VERSION ""

NS_ :

BS_:

BU_: Engine2 Aftertreatment_1_GasOutlet BrakesSystemController Transmission1 Engine1

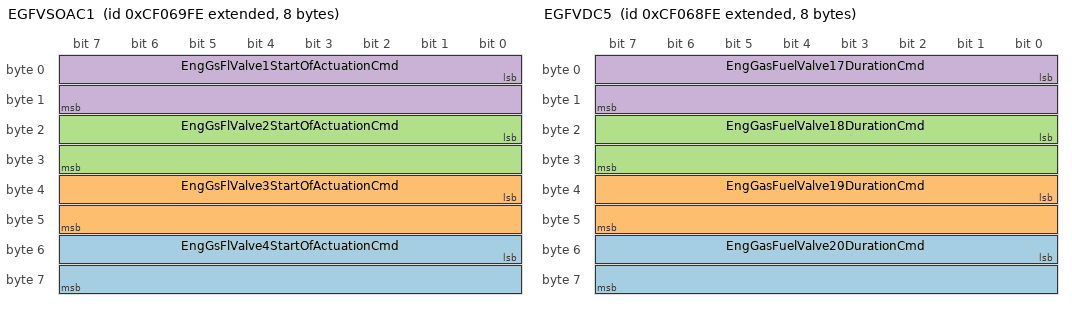
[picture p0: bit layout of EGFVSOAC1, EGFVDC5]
BO_ 2364566014 EGFVSOAC1: 8 Vector__XXX
 SG_ EngGsFlValve4StartOfActuationCmd : 48|16@1+ (0.0078125,-400) [-400|101.99] "deg" Vector__XXX
 SG_ EngGsFlValve3StartOfActuationCmd : 32|16@1+ (0.0078125,-400) [-400|101.99] "deg" Vector__XXX
 SG_ EngGsFlValve2StartOfActuationCmd : 16|16@1+ (0.0078125,-400) [-400|101.99] "deg" Vector__XXX
 SG_ EngGsFlValve1StartOfActuationCmd : 0|16@1+ (0.0078125,-400) [-400|101.99] "deg" Vector__XXX

BO_ 2364565758 EGFVDC5: 8 Vector__XXX
 SG_ EngGasFuelValve20DurationCmd : 48|16@1+ (2,0) [0|128510] "µs" Vector__XXX
 SG_ EngGasFuelValve19DurationCmd : 32|16@1+ (2,0) [0|128510] "µs" Vector__XXX
 SG_ EngGasFuelValve18DurationCmd : 16|16@1+ (2,0) [0|128510] "µs" Vector__XXX
 SG_ EngGasFuelValve17DurationCmd : 0|16@1+ (2,0) [0|128510] "µs" Vector__XXX

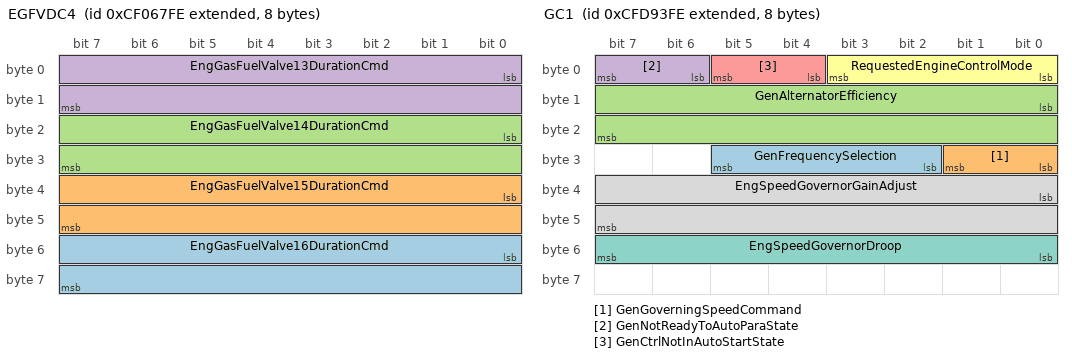
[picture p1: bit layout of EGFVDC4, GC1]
BO_ 2364565502 EGFVDC4: 8 Vector__XXX
 SG_ EngGasFuelValve16DurationCmd : 48|16@1+ (2,0) [0|128510] "µs" Vector__XXX
 SG_ EngGasFuelValve15DurationCmd : 32|16@1+ (2,0) [0|128510] "µs" Vector__XXX
 SG_ EngGasFuelValve14DurationCmd : 16|16@1+ (2,0) [0|128510] "µs" Vector__XXX
 SG_ EngGasFuelValve13DurationCmd : 0|16@1+ (2,0) [0|128510] "µs" Vector__XXX

BO_ 2364565246 EGFVDC3: 8 Vector__XXX
 SG_ EngGasFuelValve12DurationCmd : 48|16@1+ (2,0) [0|128510] "µs" Vector__XXX
 SG_ EngGasFuelValve11DurationCmd : 32|16@1+ (2,0) [0|128510] "µs" Vector__XXX
 SG_ EngGasFuelValve10DurationCmd : 16|16@1+ (2,0) [0|128510] "µs" Vector__XXX
 SG_ EngGasFuelValve9DurationCmd : 0|16@1+ (2,0) [0|128510] "µs" Vector__XXX

BO_ 2364564990 EGFVDC2: 8 Vector__XXX
 SG_ EngGasFuelValve8DurationCmd : 48|16@1+ (2,0) [0|128510] "µs" Vector__XXX
 SG_ EngGasFuelValve7DurationCmd : 32|16@1+ (2,0) [0|128510] "µs" Vector__XXX
 SG_ EngGasFuelValve6DurationCmd : 16|16@1+ (2,0) [0|128510] "µs" Vector__XXX
 SG_ EngGasFuelValve5DurationCmd : 0|16@1+ (2,0) [0|128510] "µs" Vector__XXX

BO_ 2364564734 EGFVDC1: 8 Vector__XXX
 SG_ EngGasFuelValve4DurationCmd : 48|16@1+ (2,0) [0|128510] "µs" Vector__XXX
 SG_ EngGasFuelValve3DurationCmd : 32|16@1+ (2,0) [0|128510] "µs" Vector__XXX
 SG_ EngGasFuelValve2DurationCmd : 16|16@1+ (2,0) [0|128510] "µs" Vector__XXX
 SG_ EngGasFuelValve1DurationCmd : 0|16@1+ (2,0) [0|128510] "µs" Vector__XXX

BO_ 2364564478 GFI5: 8 Vector__XXX
 SG_ EngGsFlVlvNmnlStrtOfActuationCmd : 16|16@1+ (0.0078125,-400) [-400|101.99] "deg" Vector__XXX
 SG_ EngGsFuelValveNominalDurationCmd : 0|16@1+ (2,0) [0|128510] "µs" Vector__XXX

BO_ 2297455358 ETC12: 8 Vector__XXX
 SG_ TransDirectionalOutputShaftSpeed : 32|16@1+ (1,-32127) [-32127|32128] "rpm" Vector__XXX
 SG_ TransHydrostaticLoop2Press : 16|16@1+ (1,0) [0|64255] "kPa" Vector__XXX
 SG_ TransHydrostaticLoop1Press : 0|16@1+ (1,0) [0|64255] "kPa" Vector__XXX

BO_ 2498781694 ECCAI20: 8 Vector__XXX
 SG_ EngCyl20AvrageCombustionDuration : 48|16@1+ (0.0078125,0) [0|501.99] "deg" Vector__XXX
 SG_ EngCyl20AvrgCntrOfCmbstionTiming : 32|16@1+ (0.0078125,-250) [-250|250.992] "deg" Vector__XXX
 SG_ EngCyl20AvrgStrtOfCmbstionTiming : 16|16@1+ (0.0078125,-250) [-250|250.992] "deg" Vector__XXX
 SG_ EngCyl20IndctdMeanEffectivePress : 0|16@1+ (0.0001220703125,-1) [-1|6.84362793] "MPa" Vector__XXX

BO_ 2498781438 ECCAI19: 8 Vector__XXX
 SG_ EngCyl19AvrageCombustionDuration : 48|16@1+ (0.0078125,0) [0|501.99] "deg" Vector__XXX
 SG_ EngCyl19AvrgCntrOfCmbstionTiming : 32|16@1+ (0.0078125,-250) [-250|250.992] "deg" Vector__XXX
 SG_ EngCyl19AvrgStrtOfCmbstionTiming : 16|16@1+ (0.0078125,-250) [-250|250.992] "deg" Vector__XXX
 SG_ EngCyl19IndctdMeanEffectivePress : 0|16@1+ (0.0001220703125,-1) [-1|6.84362793] "MPa" Vector__XXX

BO_ 2498781182 ECCAI18: 8 Vector__XXX
 SG_ EngCyl18AvrageCombustionDuration : 48|16@1+ (0.0078125,0) [0|501.99] "deg" Vector__XXX
 SG_ EngCyl18AvrgCntrOfCmbstionTiming : 32|16@1+ (0.0078125,-250) [-250|250.992] "deg" Vector__XXX
 SG_ EngCyl18AvrgStrtOfCmbstionTiming : 16|16@1+ (0.0078125,-250) [-250|250.992] "deg" Vector__XXX
 SG_ EngCyl18IndctdMeanEffectivePress : 0|16@1+ (0.0001220703125,-1) [-1|6.84362793] "MPa" Vector__XXX

BO_ 2498780926 ECCAI17: 8 Vector__XXX
 SG_ EngCyl17AvrageCombustionDuration : 48|16@1+ (0.0078125,0) [0|501.99] "deg" Vector__XXX
 SG_ EngCyl17AvrgCntrOfCmbstionTiming : 32|16@1+ (0.0078125,-250) [-250|250.992] "deg" Vector__XXX
 SG_ EngCyl17AvrgStrtOfCmbstionTiming : 16|16@1+ (0.0078125,-250) [-250|250.992] "deg" Vector__XXX
 SG_ EngCyl17IndctdMeanEffectivePress : 0|16@1+ (0.0001220703125,-1) [-1|6.84362793] "MPa" Vector__XXX

BO_ 2498780670 ECCAI16: 8 Vector__XXX
 SG_ EngCyl16AvrageCombustionDuration : 48|16@1+ (0.0078125,0) [0|501.99] "deg" Vector__XXX
 SG_ EngCyl16AvrgCntrOfCmbstionTiming : 32|16@1+ (0.0078125,-250) [-250|250.992] "deg" Vector__XXX
 SG_ EngCyl16AvrgStrtOfCmbstionTiming : 16|16@1+ (0.0078125,-250) [-250|250.992] "deg" Vector__XXX
 SG_ EngCyl16IndctdMeanEffectivePress : 0|16@1+ (0.0001220703125,-1) [-1|6.84362793] "MPa" Vector__XXX

BO_ 2498780414 ECCAI15: 8 Vector__XXX
 SG_ EngCyl15AvrageCombustionDuration : 48|16@1+ (0.0078125,0) [0|501.99] "deg" Vector__XXX
 SG_ EngCyl15AvrgCntrOfCmbstionTiming : 32|16@1+ (0.0078125,-250) [-250|250.992] "deg" Vector__XXX
 SG_ EngCyl15AvrgStrtOfCmbstionTiming : 16|16@1+ (0.0078125,-250) [-250|250.992] "deg" Vector__XXX
 SG_ EngCyl15IndctdMeanEffectivePress : 0|16@1+ (0.0001220703125,-1) [-1|6.84362793] "MPa" Vector__XXX

BO_ 2498780158 ECCAI14: 8 Vector__XXX
 SG_ EngCyl14AvrageCombustionDuration : 48|16@1+ (0.0078125,0) [0|501.99] "deg" Vector__XXX
 SG_ EngCyl14AvrgCntrOfCmbstionTiming : 32|16@1+ (0.0078125,-250) [-250|250.992] "deg" Vector__XXX
 SG_ EngCyl14AvrgStrtOfCmbstionTiming : 16|16@1+ (0.0078125,-250) [-250|250.992] "deg" Vector__XXX
 SG_ EngCyl14IndctdMeanEffectivePress : 0|16@1+ (0.0001220703125,-1) [-1|6.84362793] "MPa" Vector__XXX

BO_ 2498779902 ECCAI13: 8 Vector__XXX
 SG_ EngCyl13AvrageCombustionDuration : 48|16@1+ (0.0078125,0) [0|501.99] "deg" Vector__XXX
 SG_ EngCyl13AvrgCntrOfCmbstionTiming : 32|16@1+ (0.0078125,-250) [-250|250.992] "deg" Vector__XXX
 SG_ EngCyl13AvrgStrtOfCmbstionTiming : 16|16@1+ (0.0078125,-250) [-250|250.992] "deg" Vector__XXX
 SG_ EngCyl13IndctdMeanEffectivePress : 0|16@1+ (0.0001220703125,-1) [-1|6.84362793] "MPa" Vector__XXX

BO_ 2498779646 ECCAI12: 8 Vector__XXX
 SG_ EngCyl12AvrageCombustionDuration : 48|16@1+ (0.0078125,0) [0|501.99] "deg" Vector__XXX
 SG_ EngCyl12AvrgCntrOfCmbstionTiming : 32|16@1+ (0.0078125,-250) [-250|250.992] "deg" Vector__XXX
 SG_ EngCyl12AvrgStrtOfCmbstionTiming : 16|16@1+ (0.0078125,-250) [-250|250.992] "deg" Vector__XXX
 SG_ EngCyl12IndctdMeanEffectivePress : 0|16@1+ (0.0001220703125,-1) [-1|6.84362793] "MPa" Vector__XXX

BO_ 2498779390 ECCAI11: 8 Vector__XXX
 SG_ EngCyl11AvrageCombustionDuration : 48|16@1+ (0.0078125,0) [0|501.99] "deg" Vector__XXX
 SG_ EngCyl11AvrgCntrOfCmbstionTiming : 32|16@1+ (0.0078125,-250) [-250|250.992] "deg" Vector__XXX
 SG_ EngCyl11AvrgStrtOfCmbstionTiming : 16|16@1+ (0.0078125,-250) [-250|250.992] "deg" Vector__XXX
 SG_ EngCyl11IndctdMeanEffectivePress : 0|16@1+ (0.0001220703125,-1) [-1|6.84362793] "MPa" Vector__XXX

BO_ 2498779134 ECCAI10: 8 Vector__XXX
 SG_ EngCyl10AvrageCombustionDuration : 48|16@1+ (0.0078125,0) [0|501.99] "deg" Vector__XXX
 SG_ EngCyl10AvrgCntrOfCmbstionTiming : 32|16@1+ (0.0078125,-250) [-250|250.992] "deg" Vector__XXX
 SG_ EngCyl10AvrgStrtOfCmbstionTiming : 16|16@1+ (0.0078125,-250) [-250|250.992] "deg" Vector__XXX
 SG_ EngCyl10IndctdMeanEffectivePress : 0|16@1+ (0.0001220703125,-1) [-1|6.84362793] "MPa" Vector__XXX

BO_ 2498778878 ECCAI9: 8 Vector__XXX
 SG_ EngCyl9AverageCombustionDuration : 48|16@1+ (0.0078125,0) [0|501.99] "deg" Vector__XXX
 SG_ EngCyl9AvrgCntrOfCmbustionTiming : 32|16@1+ (0.0078125,-250) [-250|250.992] "deg" Vector__XXX
 SG_ EngCyl9AvrgStrtOfCmbustionTiming : 16|16@1+ (0.0078125,-250) [-250|250.992] "deg" Vector__XXX
 SG_ EngCyl9IndctedMeanEffectivePress : 0|16@1+ (0.0001220703125,-1) [-1|6.84362793] "MPa" Vector__XXX

BO_ 2365430526 EBS24: 8 Vector__XXX

BO_ 2357919486 RGE12: 8 Vector__XXX

BO_ 2357853950 RGE24: 8 Vector__XXX

BO_ 2365428734 GC1: 8 Vector__XXX
 SG_ GenFrequencySelection : 26|4@1+ (1,0) [0|15] "" Vector__XXX
 SG_ GenGoverningSpeedCommand : 24|2@1+ (1,0) [0|3] "" Vector__XXX
 SG_ GenAlternatorEfficiency : 8|16@1+ (0.0025,0) [0|100] "%" Vector__XXX
 SG_ GenNotReadyToAutoParaState : 6|2@1+ (1,0) [0|3] "" Vector__XXX
 SG_ GenCtrlNotInAutoStartState : 4|2@1+ (1,0) [0|3] "" Vector__XXX
 SG_ RequestedEngineControlMode : 0|4@1+ (1,0) [0|15] "" Vector__XXX
 SG_ EngSpeedGovernorDroop : 48|8@1+ (0.04,0) [0|10] "%" Vector__XXX
 SG_ EngSpeedGovernorGainAdjust : 32|16@1+ (1,-32128) [-32128|32127] "" Vector__XXX

BO_ 2365376254 DM57: 8 Vector__XXX
 SG_ EngOBDWarmUpSequence : 0|2@1+ (1,0) [0|3] "" Vector__XXX

BO_ 2566703102 DM56: 208 Vector__XXX
 SG_ CertificationEngineFamilyName : 64|64@1+ (1,0) [0|255] "" Vector__XXX
 SG_ ModelYear : 0|64@1+ (1,0) [0|255] "" Vector__XXX

BO_ 2566705918 DM54: 22 Vector__XXX
 SG_ DTC1 : 16|32@1+ (1,0) [0|4294967295] "" Vector__XXX
 SG_ FlashProtectLamp : 8|2@1+ (1,0) [0|3] "" Vector__XXX
 SG_ FlashAmberWarningLamp : 10|2@1+ (1,0) [0|3] "" Vector__XXX
 SG_ FlashRedStopLamp : 12|2@1+ (1,0) [0|3] "" Vector__XXX
 SG_ FlashMalfuncIndicatorLamp : 14|2@1+ (1,0) [0|3] "" Vector__XXX
 SG_ ProtectLampStatus : 0|2@1+ (1,0) [0|3] "" Vector__XXX
 SG_ AmberWarningLampStatus : 2|2@1+ (1,0) [0|3] "" Vector__XXX
 SG_ RedStopLampState : 4|2@1+ (1,0) [0|3] "" Vector__XXX
 SG_ MalfunctionIndicatorLampStatus : 6|2@1+ (1,0) [0|3] "" Vector__XXX
 SG_ DTC5 : 144|32@1+ (1,0) [0|4294967295] "" Vector__XXX
 SG_ DTC4 : 112|32@1+ (1,0) [0|4294967295] "" Vector__XXX
 SG_ DTC3 : 80|32@1+ (1,0) [0|4294967295] "" Vector__XXX
 SG_ DTC2 : 48|32@1+ (1,0) [0|4294967295] "" Vector__XXX

BO_ 2566705662 DM53: 22 Vector__XXX
 SG_ DTC1 : 16|32@1+ (1,0) [0|4294967295] "" Vector__XXX
 SG_ FlashProtectLamp : 8|2@1+ (1,0) [0|3] "" Vector__XXX
 SG_ FlashAmberWarningLamp : 10|2@1+ (1,0) [0|3] "" Vector__XXX
 SG_ FlashRedStopLamp : 12|2@1+ (1,0) [0|3] "" Vector__XXX
 SG_ FlashMalfuncIndicatorLamp : 14|2@1+ (1,0) [0|3] "" Vector__XXX
 SG_ ProtectLampStatus : 0|2@1+ (1,0) [0|3] "" Vector__XXX
 SG_ AmberWarningLampStatus : 2|2@1+ (1,0) [0|3] "" Vector__XXX
 SG_ RedStopLampState : 4|2@1+ (1,0) [0|3] "" Vector__XXX
 SG_ MalfunctionIndicatorLampStatus : 6|2@1+ (1,0) [0|3] "" Vector__XXX
 SG_ DTC5 : 144|32@1+ (1,0) [0|4294967295] "" Vector__XXX
 SG_ DTC4 : 112|32@1+ (1,0) [0|4294967295] "" Vector__XXX
 SG_ DTC3 : 80|32@1+ (1,0) [0|4294967295] "" Vector__XXX
 SG_ DTC2 : 48|32@1+ (1,0) [0|4294967295] "" Vector__XXX

BO_ 2365379582 DM55: 0 Vector__XXX

BO_ 2349465342 SRASI: 8 Vector__XXX
 SG_ StaticRollAngleStatus : 8|3@1+ (1,0) [0|7] "" Vector__XXX
 SG_ StaticRollAngle : 0|8@1+ (1,-125) [-90|90] "deg" Vector__XXX

BO_ 2498777086 ECCAI2: 8 Vector__XXX
 SG_ EngCyl2AverageCombustionDuration : 48|16@1+ (0.0078125,0) [0|501.99] "deg" Vector__XXX
 SG_ EngCyl2AvrgCntrOfCmbustionTiming : 32|16@1+ (0.0078125,-250) [-250|250.992] "deg" Vector__XXX
 SG_ EngCyl2AvrgStrtOfCmbustionTiming : 16|16@1+ (0.0078125,-250) [-250|250.992] "deg" Vector__XXX
 SG_ EngCyl2IndctedMeanEffectivePress : 0|16@1+ (0.0001220703125,-1) [-1|6.84362793] "MPa" Vector__XXX

BO_ 2498776830 ECCAI1: 8 Vector__XXX
 SG_ EngCyl1AverageCombustionDuration : 48|16@1+ (0.0078125,0) [0|501.99] "deg" Vector__XXX
 SG_ EngCyl1AvrgCntrOfCmbustionTiming : 32|16@1+ (0.0078125,-250) [-250|250.992] "deg" Vector__XXX
 SG_ EngCyl1AvrgStrtOfCmbustionTiming : 16|16@1+ (0.0078125,-250) [-250|250.992] "deg" Vector__XXX
 SG_ EngCyl1IndctedMeanEffectivePress : 0|16@1+ (0.0001220703125,-1) [-1|6.84362793] "MPa" Vector__XXX

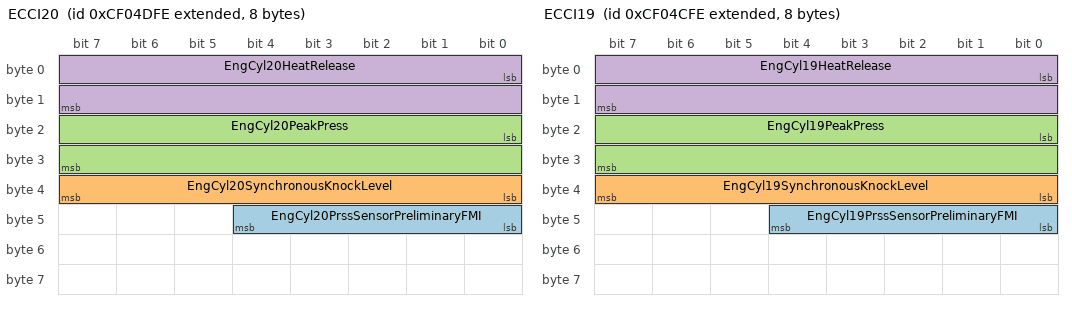
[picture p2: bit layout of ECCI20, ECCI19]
BO_ 2364558846 ECCI20: 8 Vector__XXX
 SG_ EngCyl20PrssSensorPreliminaryFMI : 40|5@1+ (1,0) [0|31] "" Vector__XXX
 SG_ EngCyl20SynchronousKnockLevel : 32|8@1+ (1,0) [0|250] "%" Vector__XXX
 SG_ EngCyl20PeakPress : 16|16@1+ (0.0009765625,0) [0|62.74902344] "MPa" Vector__XXX
 SG_ EngCyl20HeatRelease : 0|16@1+ (0.0001220703125,-1) [-1|6.84362793] "kJ/l" Vector__XXX

BO_ 2364558590 ECCI19: 8 Vector__XXX
 SG_ EngCyl19PrssSensorPreliminaryFMI : 40|5@1+ (1,0) [0|31] "" Vector__XXX
 SG_ EngCyl19SynchronousKnockLevel : 32|8@1+ (1,0) [0|250] "%" Vector__XXX
 SG_ EngCyl19PeakPress : 16|16@1+ (0.0009765625,0) [0|62.74902344] "MPa" Vector__XXX
 SG_ EngCyl19HeatRelease : 0|16@1+ (0.0001220703125,-1) [-1|6.84362793] "kJ/l" Vector__XXX

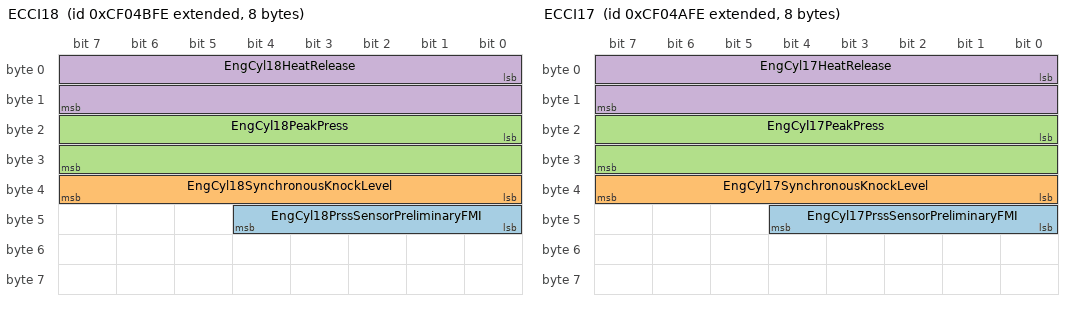
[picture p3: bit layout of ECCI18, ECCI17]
BO_ 2364558334 ECCI18: 8 Vector__XXX
 SG_ EngCyl18PrssSensorPreliminaryFMI : 40|5@1+ (1,0) [0|31] "" Vector__XXX
 SG_ EngCyl18SynchronousKnockLevel : 32|8@1+ (1,0) [0|250] "%" Vector__XXX
 SG_ EngCyl18PeakPress : 16|16@1+ (0.0009765625,0) [0|62.74902344] "MPa" Vector__XXX
 SG_ EngCyl18HeatRelease : 0|16@1+ (0.0001220703125,-1) [-1|6.84362793] "kJ/l" Vector__XXX

BO_ 2364558078 ECCI17: 8 Vector__XXX
 SG_ EngCyl17PrssSensorPreliminaryFMI : 40|5@1+ (1,0) [0|31] "" Vector__XXX
 SG_ EngCyl17SynchronousKnockLevel : 32|8@1+ (1,0) [0|250] "%" Vector__XXX
 SG_ EngCyl17PeakPress : 16|16@1+ (0.0009765625,0) [0|62.74902344] "MPa" Vector__XXX
 SG_ EngCyl17HeatRelease : 0|16@1+ (0.0001220703125,-1) [-1|6.84362793] "kJ/l" Vector__XXX

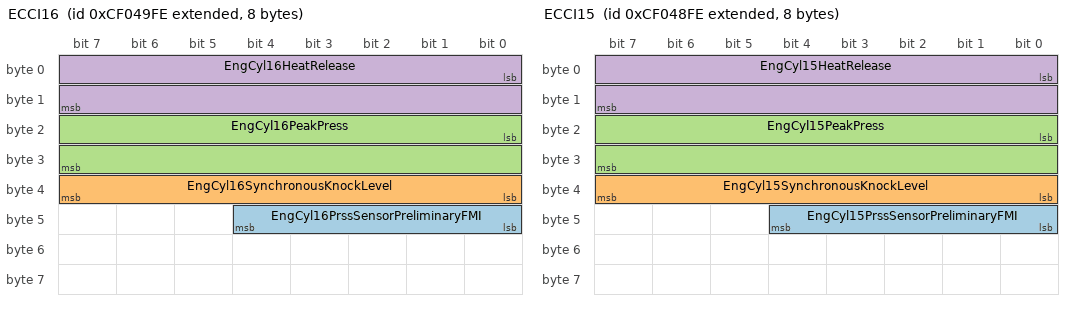
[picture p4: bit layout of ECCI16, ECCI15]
BO_ 2364557822 ECCI16: 8 Vector__XXX
 SG_ EngCyl16PrssSensorPreliminaryFMI : 40|5@1+ (1,0) [0|31] "" Vector__XXX
 SG_ EngCyl16SynchronousKnockLevel : 32|8@1+ (1,0) [0|250] "%" Vector__XXX
 SG_ EngCyl16PeakPress : 16|16@1+ (0.0009765625,0) [0|62.74902344] "MPa" Vector__XXX
 SG_ EngCyl16HeatRelease : 0|16@1+ (0.0001220703125,-1) [-1|6.84362793] "kJ/l" Vector__XXX

BO_ 2364557566 ECCI15: 8 Vector__XXX
 SG_ EngCyl15PrssSensorPreliminaryFMI : 40|5@1+ (1,0) [0|31] "" Vector__XXX
 SG_ EngCyl15SynchronousKnockLevel : 32|8@1+ (1,0) [0|250] "%" Vector__XXX
 SG_ EngCyl15PeakPress : 16|16@1+ (0.0009765625,0) [0|62.74902344] "MPa" Vector__XXX
 SG_ EngCyl15HeatRelease : 0|16@1+ (0.0001220703125,-1) [-1|6.84362793] "kJ/l" Vector__XXX

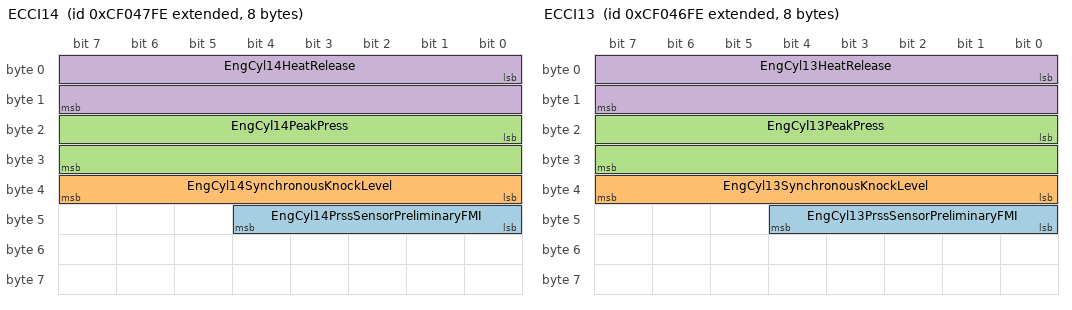
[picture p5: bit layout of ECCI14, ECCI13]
BO_ 2364557310 ECCI14: 8 Vector__XXX
 SG_ EngCyl14PrssSensorPreliminaryFMI : 40|5@1+ (1,0) [0|31] "" Vector__XXX
 SG_ EngCyl14SynchronousKnockLevel : 32|8@1+ (1,0) [0|250] "%" Vector__XXX
 SG_ EngCyl14PeakPress : 16|16@1+ (0.0009765625,0) [0|62.74902344] "MPa" Vector__XXX
 SG_ EngCyl14HeatRelease : 0|16@1+ (0.0001220703125,-1) [-1|6.84362793] "kJ/l" Vector__XXX

BO_ 2364557054 ECCI13: 8 Vector__XXX
 SG_ EngCyl13PrssSensorPreliminaryFMI : 40|5@1+ (1,0) [0|31] "" Vector__XXX
 SG_ EngCyl13SynchronousKnockLevel : 32|8@1+ (1,0) [0|250] "%" Vector__XXX
 SG_ EngCyl13PeakPress : 16|16@1+ (0.0009765625,0) [0|62.74902344] "MPa" Vector__XXX
 SG_ EngCyl13HeatRelease : 0|16@1+ (0.0001220703125,-1) [-1|6.84362793] "kJ/l" Vector__XXX

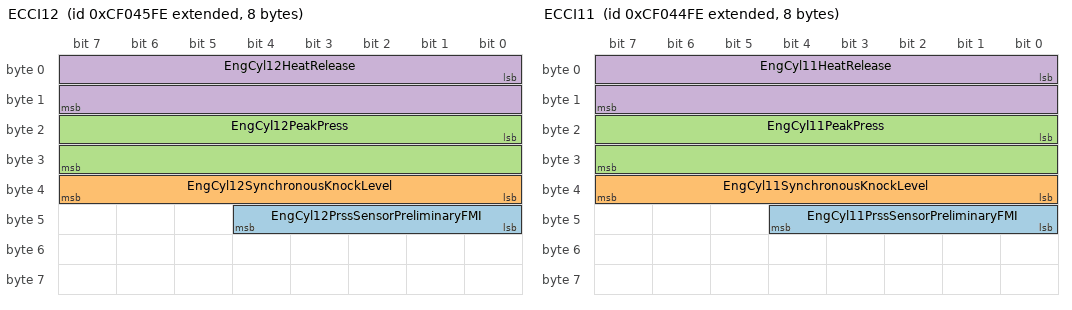
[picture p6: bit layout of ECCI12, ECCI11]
BO_ 2364556798 ECCI12: 8 Vector__XXX
 SG_ EngCyl12PrssSensorPreliminaryFMI : 40|5@1+ (1,0) [0|31] "" Vector__XXX
 SG_ EngCyl12SynchronousKnockLevel : 32|8@1+ (1,0) [0|250] "%" Vector__XXX
 SG_ EngCyl12PeakPress : 16|16@1+ (0.0009765625,0) [0|62.74902344] "MPa" Vector__XXX
 SG_ EngCyl12HeatRelease : 0|16@1+ (0.0001220703125,-1) [-1|6.84362793] "kJ/l" Vector__XXX

BO_ 2364556542 ECCI11: 8 Vector__XXX
 SG_ EngCyl11PrssSensorPreliminaryFMI : 40|5@1+ (1,0) [0|31] "" Vector__XXX
 SG_ EngCyl11SynchronousKnockLevel : 32|8@1+ (1,0) [0|250] "%" Vector__XXX
 SG_ EngCyl11PeakPress : 16|16@1+ (0.0009765625,0) [0|62.74902344] "MPa" Vector__XXX
 SG_ EngCyl11HeatRelease : 0|16@1+ (0.0001220703125,-1) [-1|6.84362793] "kJ/l" Vector__XXX

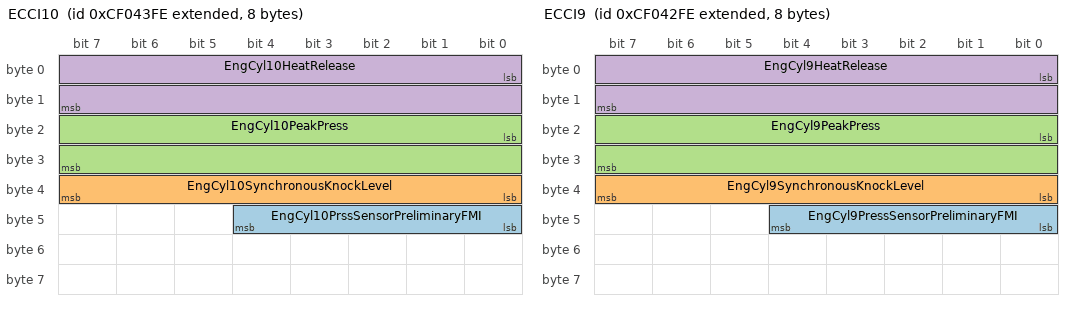
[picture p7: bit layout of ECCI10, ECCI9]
BO_ 2364556286 ECCI10: 8 Vector__XXX
 SG_ EngCyl10PrssSensorPreliminaryFMI : 40|5@1+ (1,0) [0|31] "" Vector__XXX
 SG_ EngCyl10SynchronousKnockLevel : 32|8@1+ (1,0) [0|250] "%" Vector__XXX
 SG_ EngCyl10PeakPress : 16|16@1+ (0.0009765625,0) [0|62.74902344] "MPa" Vector__XXX
 SG_ EngCyl10HeatRelease : 0|16@1+ (0.0001220703125,-1) [-1|6.84362793] "kJ/l" Vector__XXX

BO_ 2364556030 ECCI9: 8 Vector__XXX
 SG_ EngCyl9PressSensorPreliminaryFMI : 40|5@1+ (1,0) [0|31] "" Vector__XXX
 SG_ EngCyl9SynchronousKnockLevel : 32|8@1+ (1,0) [0|250] "%" Vector__XXX
 SG_ EngCyl9PeakPress : 16|16@1+ (0.0009765625,0) [0|62.74902344] "MPa" Vector__XXX
 SG_ EngCyl9HeatRelease : 0|16@1+ (0.0001220703125,-1) [-1|6.84362793] "kJ/l" Vector__XXX

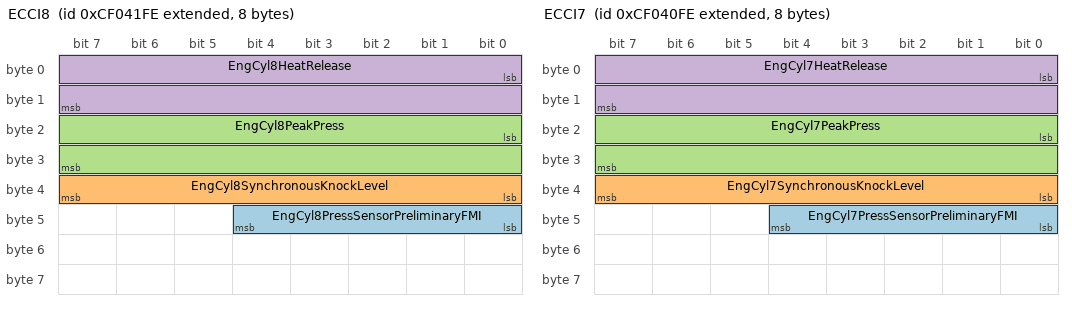
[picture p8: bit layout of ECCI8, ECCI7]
BO_ 2364555774 ECCI8: 8 Vector__XXX
 SG_ EngCyl8PressSensorPreliminaryFMI : 40|5@1+ (1,0) [0|31] "" Vector__XXX
 SG_ EngCyl8SynchronousKnockLevel : 32|8@1+ (1,0) [0|250] "%" Vector__XXX
 SG_ EngCyl8PeakPress : 16|16@1+ (0.0009765625,0) [0|62.74902344] "MPa" Vector__XXX
 SG_ EngCyl8HeatRelease : 0|16@1+ (0.0001220703125,-1) [-1|6.84362793] "kJ/l" Vector__XXX

BO_ 2364555518 ECCI7: 8 Vector__XXX
 SG_ EngCyl7PressSensorPreliminaryFMI : 40|5@1+ (1,0) [0|31] "" Vector__XXX
 SG_ EngCyl7SynchronousKnockLevel : 32|8@1+ (1,0) [0|250] "%" Vector__XXX
 SG_ EngCyl7PeakPress : 16|16@1+ (0.0009765625,0) [0|62.74902344] "MPa" Vector__XXX
 SG_ EngCyl7HeatRelease : 0|16@1+ (0.0001220703125,-1) [-1|6.84362793] "kJ/l" Vector__XXX

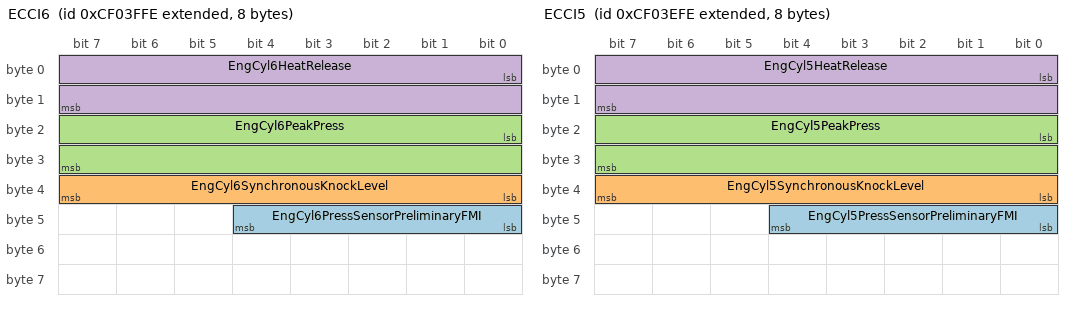
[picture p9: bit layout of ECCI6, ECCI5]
BO_ 2364555262 ECCI6: 8 Vector__XXX
 SG_ EngCyl6PressSensorPreliminaryFMI : 40|5@1+ (1,0) [0|31] "" Vector__XXX
 SG_ EngCyl6SynchronousKnockLevel : 32|8@1+ (1,0) [0|250] "%" Vector__XXX
 SG_ EngCyl6PeakPress : 16|16@1+ (0.0009765625,0) [0|62.74902344] "MPa" Vector__XXX
 SG_ EngCyl6HeatRelease : 0|16@1+ (0.0001220703125,-1) [-1|6.84362793] "kJ/l" Vector__XXX

BO_ 2364555006 ECCI5: 8 Vector__XXX
 SG_ EngCyl5PressSensorPreliminaryFMI : 40|5@1+ (1,0) [0|31] "" Vector__XXX
 SG_ EngCyl5SynchronousKnockLevel : 32|8@1+ (1,0) [0|250] "%" Vector__XXX
 SG_ EngCyl5PeakPress : 16|16@1+ (0.0009765625,0) [0|62.74902344] "MPa" Vector__XXX
 SG_ EngCyl5HeatRelease : 0|16@1+ (0.0001220703125,-1) [-1|6.84362793] "kJ/l" Vector__XXX

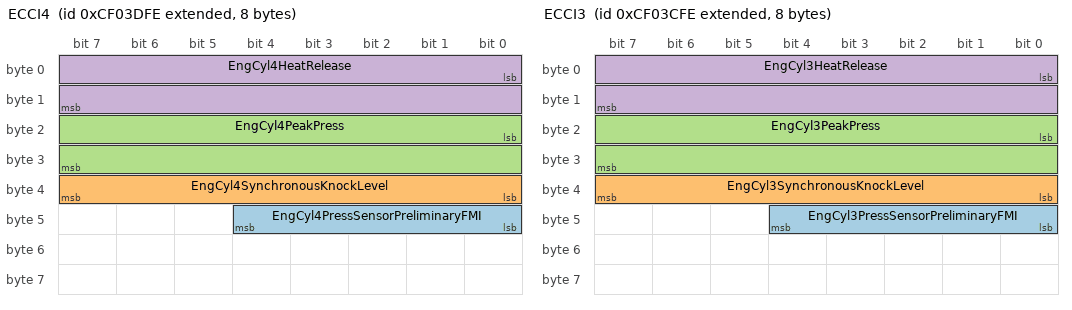
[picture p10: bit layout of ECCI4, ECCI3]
BO_ 2364554750 ECCI4: 8 Vector__XXX
 SG_ EngCyl4PressSensorPreliminaryFMI : 40|5@1+ (1,0) [0|31] "" Vector__XXX
 SG_ EngCyl4SynchronousKnockLevel : 32|8@1+ (1,0) [0|250] "%" Vector__XXX
 SG_ EngCyl4PeakPress : 16|16@1+ (0.0009765625,0) [0|62.74902344] "MPa" Vector__XXX
 SG_ EngCyl4HeatRelease : 0|16@1+ (0.0001220703125,-1) [-1|6.84362793] "kJ/l" Vector__XXX

BO_ 2364554494 ECCI3: 8 Vector__XXX
 SG_ EngCyl3PressSensorPreliminaryFMI : 40|5@1+ (1,0) [0|31] "" Vector__XXX
 SG_ EngCyl3SynchronousKnockLevel : 32|8@1+ (1,0) [0|250] "%" Vector__XXX
 SG_ EngCyl3PeakPress : 16|16@1+ (0.0009765625,0) [0|62.74902344] "MPa" Vector__XXX
 SG_ EngCyl3HeatRelease : 0|16@1+ (0.0001220703125,-1) [-1|6.84362793] "kJ/l" Vector__XXX

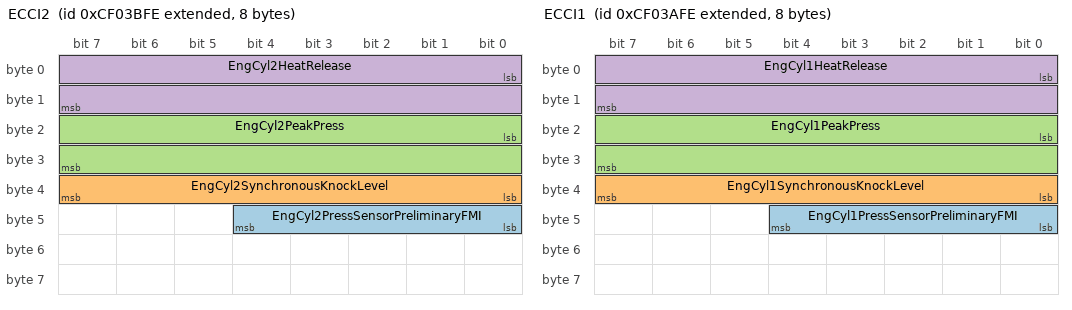
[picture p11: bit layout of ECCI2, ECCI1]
BO_ 2364554238 ECCI2: 8 Vector__XXX
 SG_ EngCyl2PressSensorPreliminaryFMI : 40|5@1+ (1,0) [0|31] "" Vector__XXX
 SG_ EngCyl2SynchronousKnockLevel : 32|8@1+ (1,0) [0|250] "%" Vector__XXX
 SG_ EngCyl2PeakPress : 16|16@1+ (0.0009765625,0) [0|62.74902344] "MPa" Vector__XXX
 SG_ EngCyl2HeatRelease : 0|16@1+ (0.0001220703125,-1) [-1|6.84362793] "kJ/l" Vector__XXX

BO_ 2364553982 ECCI1: 8 Vector__XXX
 SG_ EngCyl1PressSensorPreliminaryFMI : 40|5@1+ (1,0) [0|31] "" Vector__XXX
 SG_ EngCyl1SynchronousKnockLevel : 32|8@1+ (1,0) [0|100] "%" Vector__XXX
 SG_ EngCyl1PeakPress : 16|16@1+ (0.0009765625,0) [0|62.74902344] "MPa" Vector__XXX
 SG_ EngCyl1HeatRelease : 0|16@1+ (0.0001220703125,-1) [-1|6.84362793] "kJ/l" Vector__XXX

BO_ 2364553726 EASI: 8 Vector__XXX
 SG_ EngTotalIntakeMassAirFlowRate : 16|16@1+ (0.0009765625,0) [0|62.74902344] "kg/s" Vector__XXX
 SG_ EngDesiredAirFuelRatio : 0|16@1+ (0.001,0) [0|64.255] "" Vector__XXX

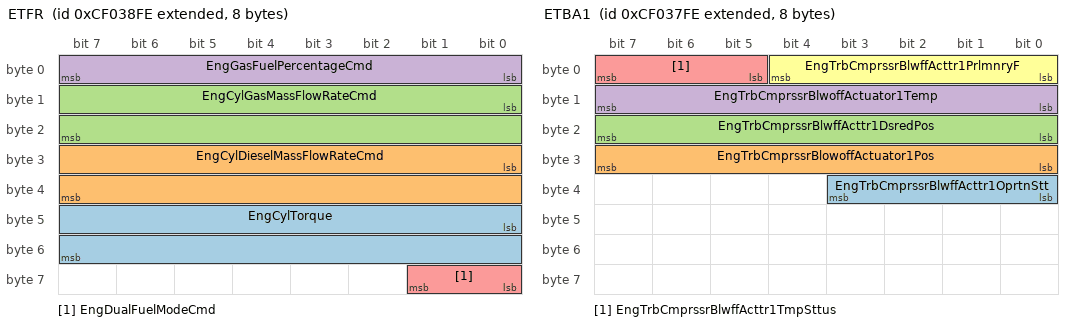
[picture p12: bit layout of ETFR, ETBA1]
BO_ 2364553470 ETFR: 8 Vector__XXX
 SG_ EngCylTorque : 40|16@1+ (1,0) [0|64255] "Nm" Vector__XXX
 SG_ EngCylDieselMassFlowRateCmd : 24|16@1+ (6.103515625E-005,0) [0|3.921813965] "kg/s" Vector__XXX
 SG_ EngCylGasMassFlowRateCmd : 8|16@1+ (6.103515625E-005,0) [0|3.921813965] "kg/s" Vector__XXX
 SG_ EngGasFuelPercentageCmd : 0|8@1+ (0.5,0) [0|100] "%" Vector__XXX
 SG_ EngDualFuelModeCmd : 56|2@1+ (1,0) [0|100] "" Vector__XXX

BO_ 2364553214 ETBA1: 8 Vector__XXX
 SG_ EngTrbCmprssrBlwffActtr1OprtnStt : 32|4@1+ (1,0) [0|15] "" Vector__XXX
 SG_ EngTrbCmprssrBlowoffActuator1Pos : 24|8@1+ (0.4,0) [0|100] "%" Vector__XXX
 SG_ EngTrbCmprssrBlwffActtr1DsredPos : 16|8@1+ (0.4,0) [0|100] "%" Vector__XXX
 SG_ EngTrbCmprssrBlwoffActuator1Temp : 8|8@1+ (1,-40) [-40|210] "°C" Vector__XXX
 SG_ EngTrbCmprssrBlwffActtr1TmpSttus : 5|3@1+ (1,0) [0|7] "" Vector__XXX
 SG_ EngTrbCmprssrBlwffActtr1PrlmnryF : 0|5@1+ (1,0) [0|31] "" Vector__XXX

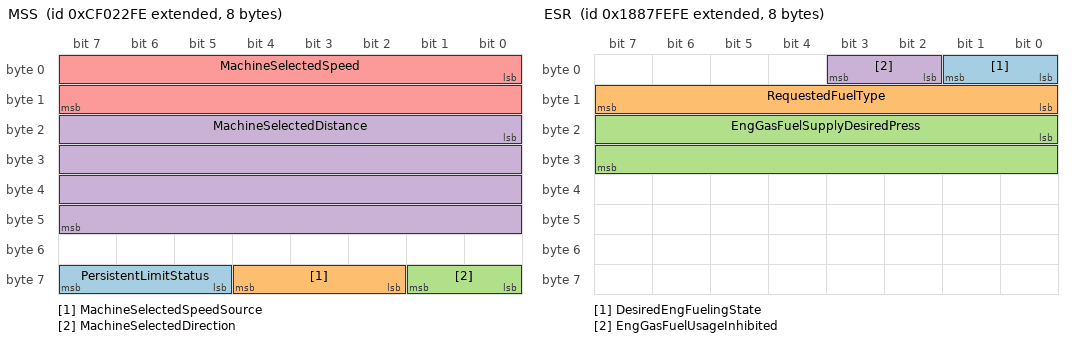
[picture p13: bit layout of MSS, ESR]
BO_ 2364547838 MSS: 8 Vector__XXX
 SG_ PersistentLimitStatus : 61|3@1+ (1,0) [0|0] "" Vector__XXX
 SG_ MachineSelectedSpeedSource : 58|3@1+ (1,0) [0|0] "" Vector__XXX
 SG_ MachineSelectedDirection : 56|2@1+ (1,0) [0|0] "" Vector__XXX
 SG_ MachineSelectedDistance : 16|32@1+ (1,0) [0|0] "" Vector__XXX
 SG_ MachineSelectedSpeed : 0|16@1+ (1,0) [0|0] "" Vector__XXX

BO_ 2364547326 EBS25: 8 Vector__XXX

BO_ 2364547070 EBS26: 8 Vector__XXX

BO_ 2364546814 GC2: 8 Vector__XXX
 SG_ GeneratorGoverningBias : 0|16@1+ (0.004,-125) [-125|125] "%" Vector__XXX

BO_ 2364546046 GPM17: 8 Vector__XXX

BO_ 2364538622 PropA: 8 Vector__XXX
 SG_ ManufacturerSpecificInformation : 0|64@1+ (1,0) [0|0] "" Vector__XXX

BO_ 2364014334 VT21: 8 Vector__XXX

BO_ 2363948798 VT12: 8 Vector__XXX

BO_ 2566767614 EEC15: 8 Vector__XXX
 SG_ AccelPedal2Channel3 : 24|8@1+ (0.4,0) [0|100] "%" Vector__XXX
 SG_ AccelPedal2Channel2 : 16|8@1+ (0.4,0) [0|100] "%" Vector__XXX
 SG_ AccelPedal1Channel3 : 8|8@1+ (0.4,0) [0|100] "%" Vector__XXX
 SG_ AccelPedal1Channel2 : 0|8@1+ (0.4,0) [0|100] "%" Vector__XXX

BO_ 2559049470 ESR: 8 Vector__XXX
 SG_ DesiredEngFuelingState : 0|2@1+ (1,0) [0|3] "" Vector__XXX
 SG_ RequestedFuelType : 8|8@1+ (1,0) [0|255] "" Vector__XXX
 SG_ EngGasFuelSupplyDesiredPress : 16|16@1+ (0.5,0) [0|32127.5] "kPa" Vector__XXX
 SG_ EngGasFuelUsageInhibited : 2|2@1+ (1,0) [0|3] "" Vector__XXX

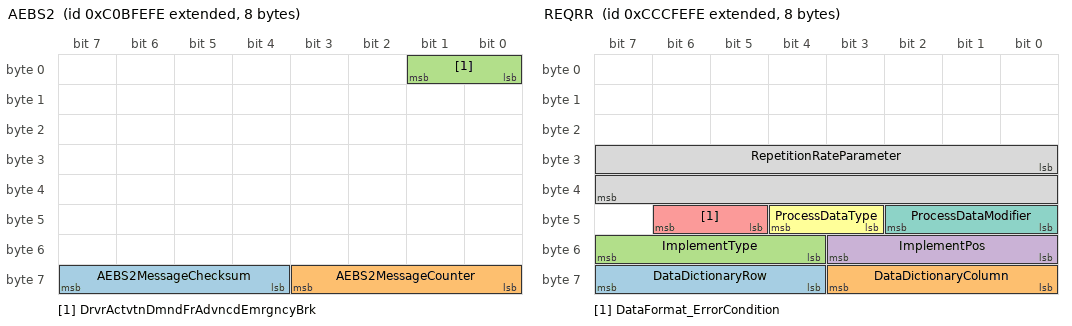
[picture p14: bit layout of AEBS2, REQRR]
BO_ 2349596414 AEBS2: 8 Vector__XXX
 SG_ AEBS2MessageChecksum : 60|4@1+ (1,0) [0|15] "" Vector__XXX
 SG_ AEBS2MessageCounter : 56|4@1+ (1,0) [0|15] "" Vector__XXX
 SG_ DrvrActvtnDmndFrAdvncdEmrgncyBrk : 0|2@1+ (1,0) [0|3] "" Vector__XXX

BO_ 2362375934 KWP3: 8 Vector__XXX

BO_ 2362310398 KWP4: 8 Vector__XXX

BO_ 2362244862 REQRR: 8 Vector__XXX
 SG_ DataDictionaryRow : 60|4@1+ (1,0) [0|0] "" Vector__XXX
 SG_ DataDictionaryColumn : 56|4@1+ (1,0) [0|0] "" Vector__XXX
 SG_ ImplementType : 52|4@1+ (1,0) [0|0] "" Vector__XXX
 SG_ ImplementPos : 48|4@1+ (1,0) [0|0] "" Vector__XXX
 SG_ DataFormat_ErrorCondition : 45|2@1+ (1,0) [0|0] "" Vector__XXX
 SG_ ProcessDataType : 43|2@1+ (1,0) [0|0] "" Vector__XXX
 SG_ ProcessDataModifier : 40|3@1+ (1,0) [0|0] "" Vector__XXX
 SG_ RepetitionRateParameter : 24|16@1+ (1,0) [0|0] "" Vector__XXX

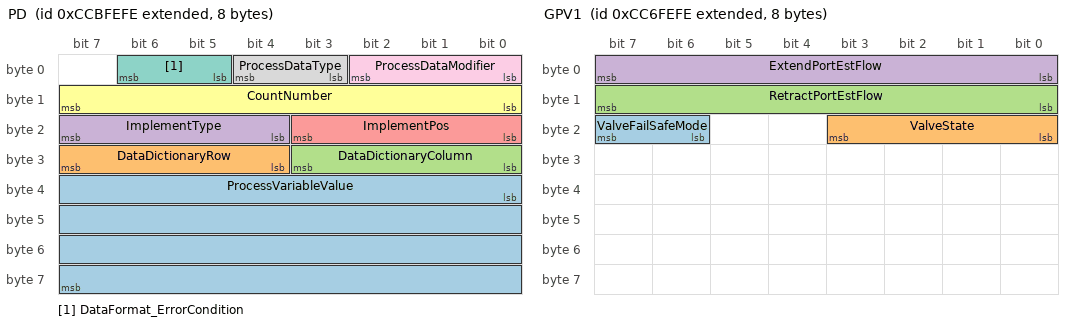
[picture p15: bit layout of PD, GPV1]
BO_ 2362179326 PD: 8 Vector__XXX
 SG_ ProcessVariableValue : 32|32@1+ (1,0) [0|0] "" Vector__XXX
 SG_ DataDictionaryRow : 28|4@1+ (1,0) [0|0] "" Vector__XXX
 SG_ DataDictionaryColumn : 24|4@1+ (1,0) [0|0] "" Vector__XXX
 SG_ ImplementType : 20|4@1+ (1,0) [0|0] "" Vector__XXX
 SG_ ImplementPos : 16|4@1+ (1,0) [0|0] "" Vector__XXX
 SG_ CountNumber : 8|8@1+ (1,0) [0|0] "" Vector__XXX
 SG_ DataFormat_ErrorCondition : 5|2@1+ (1,0) [0|0] "" Vector__XXX
 SG_ ProcessDataType : 3|2@1+ (1,0) [0|0] "" Vector__XXX
 SG_ ProcessDataModifier : 0|3@1+ (1,0) [0|0] "" Vector__XXX

BO_ 2361982718 ETPCM: 8 Vector__XXX

BO_ 2361917182 ETPDT: 8 Vector__XXX

BO_ 2361851646 GPV1: 8 Vector__XXX
 SG_ ValveFailSafeMode : 22|2@1+ (1,0) [0|0] "" Vector__XXX
 SG_ ValveState : 16|4@1+ (1,0) [0|0] "" Vector__XXX
 SG_ RetractPortEstFlow : 8|8@1+ (1,0) [0|0] "" Vector__XXX
 SG_ ExtendPortEstFlow : 0|8@1+ (1,0) [0|0] "" Vector__XXX

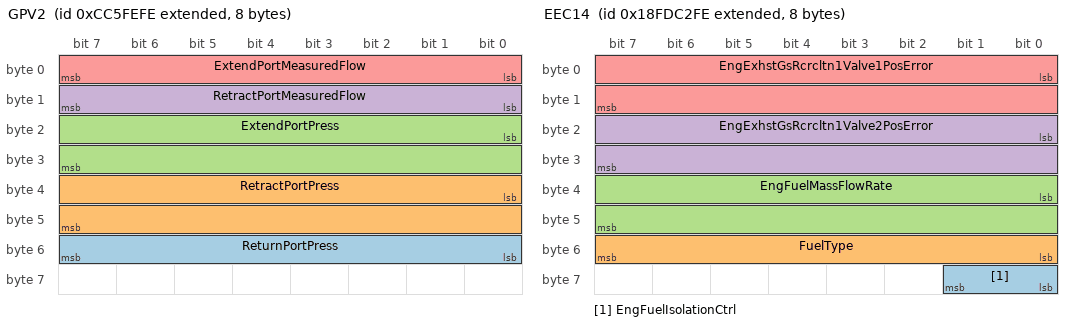
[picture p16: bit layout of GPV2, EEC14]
BO_ 2361786110 GPV2: 8 Vector__XXX
 SG_ ReturnPortPress : 48|8@1+ (1,0) [0|0] "" Vector__XXX
 SG_ RetractPortPress : 32|16@1+ (1,0) [0|0] "" Vector__XXX
 SG_ ExtendPortPress : 16|16@1+ (1,0) [0|0] "" Vector__XXX
 SG_ RetractPortMeasuredFlow : 8|8@1+ (1,0) [0|0] "" Vector__XXX
 SG_ ExtendPortMeasuredFlow : 0|8@1+ (1,0) [0|0] "" Vector__XXX

BO_ 2361720574 GPV3: 8 Vector__XXX
 SG_ PortFlowCmd : 0|8@1+ (1,0) [0|0] "" Vector__XXX

BO_ 2361458430 PCM16: 8 Vector__XXX

BO_ 2361392894 PCM15: 8 Vector__XXX

BO_ 2361327358 PCM14: 8 Vector__XXX

BO_ 2361261822 PCM13: 8 Vector__XXX

BO_ 2361196286 PCM12: 8 Vector__XXX

BO_ 2361130750 PCM11: 8 Vector__XXX

BO_ 2361065214 PCM10: 8 Vector__XXX

BO_ 2360999678 PCM9: 8 Vector__XXX

BO_ 2360934142 PCM8: 8 Vector__XXX

BO_ 2360868606 PCM7: 8 Vector__XXX

BO_ 2360803070 PCM6: 8 Vector__XXX

BO_ 2360737534 PCM5: 8 Vector__XXX

BO_ 2360671998 PCM4: 8 Vector__XXX

BO_ 2360606462 PCM3: 8 Vector__XXX

BO_ 2360540926 PCM2: 8 Vector__XXX

BO_ 2360475390 PCM1: 8 Vector__XXX

BO_ 2360409854 CIM: 8 Vector__XXX

BO_ 2360344318 PLM: 8 Vector__XXX

BO_ 2360213246 GSC: 8 Vector__XXX

BO_ 2360147710 GMS: 8 Vector__XXX

BO_ 2360082174 FSC: 8 Vector__XXX

BO_ 2358968062 GPM18: 8 Vector__XXX

BO_ 2358509310 NM: 8 Vector__XXX
 SG_ VehicleSystemQualifierFlag m0 : 12|1@1+ (1,0) [0|1] "" Vector__XXX
 SG_ VehicleSystemInstanceQualifierFl m0 : 13|1@1+ (1,0) [0|1] "" Vector__XXX
 SG_ NameChecksum m0 : 0|8@1+ (1,0) [0|0] "" Vector__XXX
 SG_ NMControlModeIndicator M : 16|4@1+ (1,0) [0|15] "" Vector__XXX
 SG_ ManufacturerCodeQualifierFlag m0M : 8|1@1+ (1,0) [0|1] "" Vector__XXX
 SG_ IndustryGroupQualifierFlag m0 : 14|1@1+ (1,0) [0|1] "" Vector__XXX
 SG_ FunctionQualifierFlag m0 : 11|1@1+ (1,0) [0|1] "" Vector__XXX
 SG_ FunctionInstanceQualifierFlag m0 : 10|1@1+ (1,0) [0|1] "" Vector__XXX
 SG_ ErrorCode m4 : 0|8@1+ (1,0) [0|0] "" Vector__XXX
 SG_ ECUInstanceQualifierFlag m0 : 9|1@1+ (1,0) [0|1] "" Vector__XXX
 SG_ CommandVehicleSystemInstance m0 : 56|4@1+ (1,0) [0|15] "" Vector__XXX
 SG_ CommandVehicleSystem m0 : 49|7@1+ (1,0) [0|127] "" Vector__XXX
 SG_ CommandManufacturerCode m0 : 21|11@1+ (1,0) [0|2047] "" Vector__XXX
 SG_ CommandIndustryGroup m0 : 60|3@1+ (1,0) [0|7] "" Vector__XXX
 SG_ CommandFunctionInstance m0 : 35|5@1+ (1,0) [0|31] "" Vector__XXX
 SG_ CommandFunction m0 : 40|8@1+ (1,0) [0|255] "" Vector__XXX
 SG_ CommandECUInstance m0 : 32|3@1+ (1,0) [0|7] "" Vector__XXX
 SG_ CommandArbitraryAddressCapable m0 : 63|1@1+ (1,0) [0|1] "" Vector__XXX
 SG_ ArbitraryAddressCapableQualifier m0 : 15|1@1+ (1,0) [0|1] "" Vector__XXX

BO_ 2358181630 SCMCC: 8 Vector__XXX

BO_ 2358116094 SCCCM: 8 Vector__XXX

BO_ 2358050558 CCP_CRO: 8 Vector__XXX

BO_ 2357985022 CCP_DTO: 8 Vector__XXX

BO_ 2558983934 SPOC: 8 Vector__XXX
 SG_ SwitchedPowerOutput18Cmd : 36|2@1+ (1,0) [0|3] "" Vector__XXX
 SG_ SwitchedPowerOutput19Cmd : 34|2@1+ (1,0) [0|3] "" Vector__XXX
 SG_ SwitchedPowerOutput20Cmd : 32|2@1+ (1,0) [0|3] "" Vector__XXX
 SG_ SwitchedPowerOutput13Cmd : 30|2@1+ (1,0) [0|3] "" Vector__XXX
 SG_ SwitchedPowerOutput14Cmd : 27|2@1+ (1,0) [0|3] "" Vector__XXX
 SG_ SwitchedPowerOutput15Cmd : 26|2@1+ (1,0) [0|3] "" Vector__XXX
 SG_ SwitchedPowerOutput16Cmd : 24|2@1+ (1,0) [0|3] "" Vector__XXX
 SG_ SwitchedPowerOutput9Cmd : 22|2@1+ (1,0) [0|3] "" Vector__XXX
 SG_ SwitchedPowerOutput10Cmd : 20|2@1+ (1,0) [0|3] "" Vector__XXX
 SG_ SwitchedPowerOutput29Cmd : 62|2@1+ (1,0) [0|3] "" Vector__XXX
 SG_ SwitchedPowerOutput30Cmd : 60|2@1+ (1,0) [0|3] "" Vector__XXX
 SG_ SwitchedPowerOutput31Cmd : 58|2@1+ (1,0) [0|3] "" Vector__XXX
 SG_ SwitchedPowerOutput32Cmd : 56|2@1+ (1,0) [0|3] "" Vector__XXX
 SG_ SwitchedPowerOutput25Cmd : 54|2@1+ (1,0) [0|3] "" Vector__XXX
 SG_ SwitchedPowerOutput26Cmd : 52|2@1+ (1,0) [0|3] "" Vector__XXX
 SG_ SwitchedPowerOutput27Cmd : 50|2@1+ (1,0) [0|3] "" Vector__XXX
 SG_ SwitchedPowerOutput28Cmd : 48|2@1+ (1,0) [0|3] "" Vector__XXX
 SG_ SwitchedPowerOutput21Cmd : 46|2@1+ (1,0) [0|3] "" Vector__XXX
 SG_ SwitchedPowerOutput22Cmd : 44|2@1+ (1,0) [0|3] "" Vector__XXX
 SG_ SwitchedPowerOutput23Cmd : 42|2@1+ (1,0) [0|3] "" Vector__XXX
 SG_ SwitchedPowerOutput24Cmd : 40|2@1+ (1,0) [0|3] "" Vector__XXX
 SG_ SwitchedPowerOutput17Cmd : 38|2@1+ (1,0) [0|3] "" Vector__XXX
 SG_ SwitchedPowerOutput11Cmd : 18|2@1+ (1,0) [0|3] "" Vector__XXX
 SG_ SwitchedPowerOutput12Cmd : 16|2@1+ (1,0) [0|3] "" Vector__XXX
 SG_ SwitchedPowerOutput5Cmd : 14|2@1+ (1,0) [0|3] "" Vector__XXX
 SG_ SwitchedPowerOutput6Cmd : 12|2@1+ (1,0) [0|3] "" Vector__XXX
 SG_ SwitchedPowerOutput7Cmd : 10|2@1+ (1,0) [0|3] "" Vector__XXX
 SG_ SwitchedPowerOutput8Cmd : 8|2@1+ (1,0) [0|3] "" Vector__XXX
 SG_ SwitchedPowerOutput1Cmd : 6|2@1+ (1,0) [0|3] "" Vector__XXX
 SG_ SwitchedPowerOutput2Cmd : 4|2@1+ (1,0) [0|3] "" Vector__XXX
 SG_ SwitchedPowerOutput3Cmd : 2|2@1+ (1,0) [0|3] "" Vector__XXX
 SG_ SwitchedPowerOutput4Cmd : 0|2@1+ (1,0) [0|3] "" Vector__XXX

BO_ 2349727486 TC2: 8 Vector__XXX
 SG_ TransMode10 : 2|2@1+ (1,0) [0|3] "" Vector__XXX
 SG_ TransMode9 : 0|2@1+ (1,0) [0|3] "" Vector__XXX

BO_ 2550988542 EEC16: 8 Vector__XXX
 SG_ AccelPedalPos3 : 0|8@1+ (0.4,0) [0|100] "%" Vector__XXX

BO_ 2349268734 CAM21: 8 Vector__XXX

BO_ 2349203198 CAM11: 8 Vector__XXX

BO_ 2566767358 EEC14: 8 Vector__XXX
 SG_ EngFuelIsolationCtrl : 56|2@1+ (1,0) [0|3] "" Vector__XXX
 SG_ FuelType : 48|8@1+ (1,0) [0|255] "" Vector__XXX
 SG_ EngFuelMassFlowRate : 32|16@1+ (0.005,0) [0|321.275] "g/s" Vector__XXX
 SG_ EngExhstGsRcrcltn1Valve2PosError : 16|16@1+ (0.004,-125) [-125|132.02] "%" Vector__XXX
 SG_ EngExhstGsRcrcltn1Valve1PosError : 0|16@1+ (0.004,-125) [-125|132.02] "%" Vector__XXX

BO_ 2566706686 AT1P1I: 8 Vector__XXX
 SG_ AT1DslExhustFluidPump2MotorSpeed : 8|16@1+ (0.5,0) [0|32127.5] "rpm" Vector__XXX
 SG_ AT1DieselExhaustFluidPumpHeater : 0|8@1+ (0.4,0) [0|100] "%" Vector__XXX

BO_ 2566705406 EPSI: 8 Vector__XXX
 SG_ AT1ParticulateSensorCurrent : 32|16@1+ (0.00390625,0) [0|127] "µA" Vector__XXX
 SG_ AT2ParticulateSensor : 16|16@1+ (0.0125,0) [0|803.1875] "mg/m³" Vector__XXX
 SG_ AT1ParticulateSensor : 0|16@1+ (0.0125,0) [0|803.1875] "mg/m³" Vector__XXX

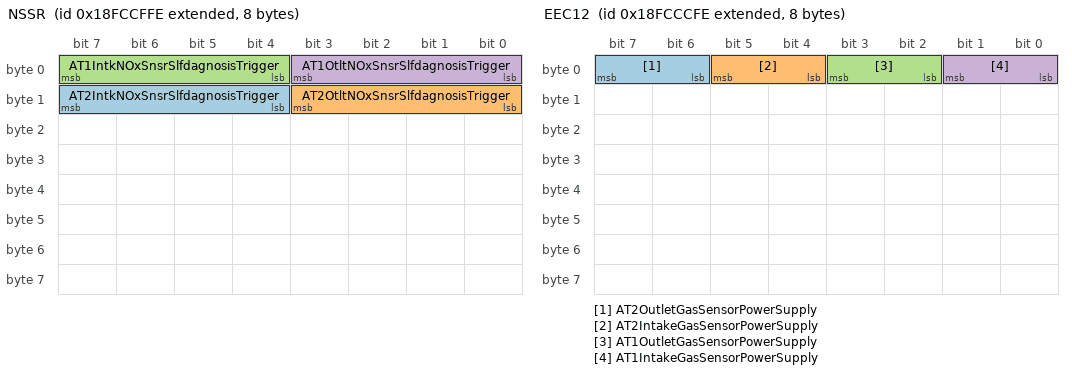
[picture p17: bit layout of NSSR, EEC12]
BO_ 2566705150 NSSR: 8 Vector__XXX
 SG_ AT2IntkNOxSnsrSlfdagnosisTrigger : 12|4@1+ (1,0) [0|15] "" Vector__XXX
 SG_ AT2OtltNOxSnsrSlfdagnosisTrigger : 8|4@1+ (1,0) [0|15] "" Vector__XXX
 SG_ AT1IntkNOxSnsrSlfdagnosisTrigger : 4|4@1+ (1,0) [0|15] "" Vector__XXX
 SG_ AT1OtltNOxSnsrSlfdagnosisTrigger : 0|4@1+ (1,0) [0|15] "" Vector__XXX

BO_ 2566704382 EEC12: 8 Vector__XXX
 SG_ AT2OutletGasSensorPowerSupply : 6|2@1+ (1,0) [0|3] "" Vector__XXX
 SG_ AT2IntakeGasSensorPowerSupply : 4|2@1+ (1,0) [0|3] "" Vector__XXX
 SG_ AT1OutletGasSensorPowerSupply : 2|2@1+ (1,0) [0|3] "" Vector__XXX
 SG_ AT1IntakeGasSensorPowerSupply : 0|2@1+ (1,0) [0|3] "" Vector__XXX

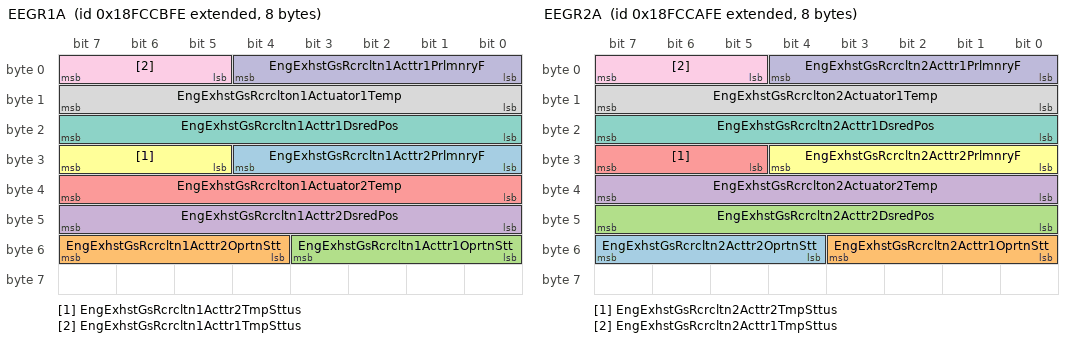
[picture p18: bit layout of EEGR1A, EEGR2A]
BO_ 2566704126 EEGR1A: 8 Vector__XXX
 SG_ EngExhstGsRcrcltn1Acttr2PrlmnryF : 24|5@1+ (1,0) [0|31] "" Vector__XXX
 SG_ EngExhstGsRcrcltn1Acttr2OprtnStt : 52|4@1+ (1,0) [0|15] "" Vector__XXX
 SG_ EngExhstGsRcrcltn1Acttr1OprtnStt : 48|4@1+ (1,0) [0|15] "" Vector__XXX
 SG_ EngExhstGsRcrcltn1Acttr2DsredPos : 40|8@1+ (0.4,0) [0|100] "%" Vector__XXX
 SG_ EngExhstGsRcrclton1Actuator2Temp : 32|8@1+ (1,-40) [-40|210] "°C" Vector__XXX
 SG_ EngExhstGsRcrcltn1Acttr2TmpSttus : 29|3@1+ (1,0) [0|7] "" Vector__XXX
 SG_ EngExhstGsRcrcltn1Acttr1DsredPos : 16|8@1+ (0.4,0) [0|100] "%" Vector__XXX
 SG_ EngExhstGsRcrclton1Actuator1Temp : 8|8@1+ (1,-40) [-40|210] "°C" Vector__XXX
 SG_ EngExhstGsRcrcltn1Acttr1TmpSttus : 5|3@1+ (1,0) [0|7] "" Vector__XXX
 SG_ EngExhstGsRcrcltn1Acttr1PrlmnryF : 0|5@1+ (1,0) [0|31] "" Vector__XXX

BO_ 2566703870 EEGR2A: 8 Vector__XXX
 SG_ EngExhstGsRcrcltn2Acttr2OprtnStt : 52|4@1+ (1,0) [0|15] "" Vector__XXX
 SG_ EngExhstGsRcrcltn2Acttr1OprtnStt : 48|4@1+ (1,0) [0|15] "" Vector__XXX
 SG_ EngExhstGsRcrcltn2Acttr2DsredPos : 40|8@1+ (0.4,0) [0|100] "%" Vector__XXX
 SG_ EngExhstGsRcrclton2Actuator2Temp : 32|8@1+ (1,-40) [-40|210] "°C" Vector__XXX
 SG_ EngExhstGsRcrcltn2Acttr2TmpSttus : 29|3@1+ (1,0) [0|7] "" Vector__XXX
 SG_ EngExhstGsRcrcltn2Acttr2PrlmnryF : 24|5@1+ (1,0) [0|31] "" Vector__XXX
 SG_ EngExhstGsRcrcltn2Acttr1DsredPos : 16|8@1+ (0.4,0) [0|100] "%" Vector__XXX
 SG_ EngExhstGsRcrclton2Actuator1Temp : 8|8@1+ (1,-40) [-40|210] "°C" Vector__XXX
 SG_ EngExhstGsRcrcltn2Acttr1TmpSttus : 5|3@1+ (1,0) [0|7] "" Vector__XXX
 SG_ EngExhstGsRcrcltn2Acttr1PrlmnryF : 0|5@1+ (1,0) [0|31] "" Vector__XXX

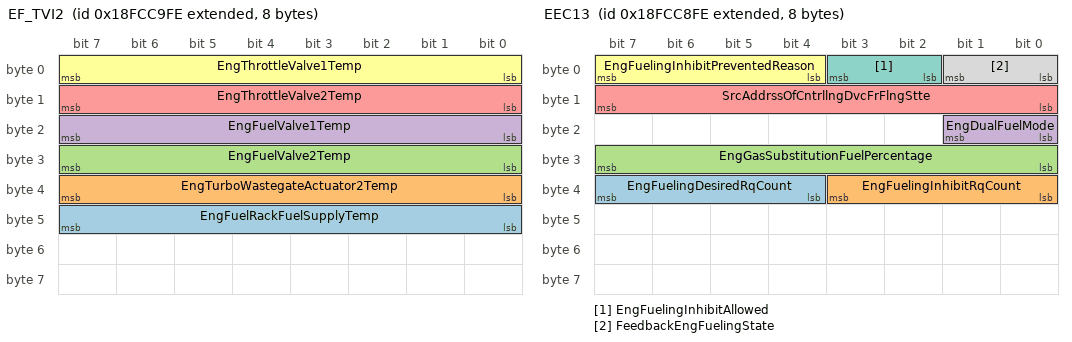
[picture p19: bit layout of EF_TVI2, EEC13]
BO_ 2566703614 EF_TVI2: 8 Vector__XXX
 SG_ EngFuelRackFuelSupplyTemp : 40|8@1+ (1,-40) [-40|210] "°C" Vector__XXX
 SG_ EngTurboWastegateActuator2Temp : 32|8@1+ (1,-40) [-40|210] "°C" Vector__XXX
 SG_ EngFuelValve2Temp : 24|8@1+ (1,-40) [-40|210] "°C" Vector__XXX
 SG_ EngFuelValve1Temp : 16|8@1+ (1,-40) [-40|210] "°C" Vector__XXX
 SG_ EngThrottleValve2Temp : 8|8@1+ (1,-40) [-40|210] "°C" Vector__XXX
 SG_ EngThrottleValve1Temp : 0|8@1+ (1,-40) [-40|210] "°C" Vector__XXX

BO_ 2566703358 EEC13: 8 Vector__XXX
 SG_ EngFuelingDesiredRqCount : 36|4@1+ (1,0) [0|15] "" Vector__XXX
 SG_ EngFuelingInhibitRqCount : 32|4@1+ (1,0) [0|15] "" Vector__XXX
 SG_ EngGasSubstitutionFuelPercentage : 24|8@1+ (0.5,0) [0|125] "%" Vector__XXX
 SG_ EngDualFuelMode : 16|2@1+ (1,0) [0|3] "" Vector__XXX
 SG_ SrcAddrssOfCntrllngDvcFrFlngStte : 8|8@1+ (1,0) [0|255] "" Vector__XXX
 SG_ EngFuelingInhibitPreventedReason : 4|4@1+ (1,0) [0|15] "" Vector__XXX
 SG_ EngFuelingInhibitAllowed : 2|2@1+ (1,0) [0|3] "" Vector__XXX
 SG_ FeedbackEngFuelingState : 0|2@1+ (1,0) [0|3] "" Vector__XXX

BO_ 2566702590 A1SCREGT2: 8 Vector__XXX
 SG_ AT1SCRIntrmdteTempPreliminaryFMI : 16|5@1+ (1,0) [0|31] "" Vector__XXX
 SG_ AT1SCRIntermediateTemp : 0|16@1+ (0.03125,-273) [-273|1734.96875] "°C" Vector__XXX

BO_ 2566702334 A2SCREGT2: 8 Vector__XXX
 SG_ AT2SCRIntrmdteTempPreliminaryFMI : 16|5@1+ (1,0) [0|31] "" Vector__XXX
 SG_ AT2SCRIntermediateTemp : 0|16@1+ (0.03125,-273) [-273|1734.96875] "°C" Vector__XXX

BO_ 2566702078 GFI4: 8 Vector__XXX
 SG_ SupplyGasMethanePercentage : 0|16@1+ (0.0025,0) [0|160.6375] "%" Vector__XXX

CM_ BO_ 2364566014 "Used to transmit the gaseous fuel valve start of activation command information for valve 1 to valve 4.";
CM_ SG_ 2364566014 EngGsFlValve4StartOfActuationCmd "The angle, relative to the TDC of cylinder 4, with 0 being the TDC before the power stroke commences, at the which gaseous fuel valve 4 is activated to open.
Timings after TDC are referred with positive values and timings before TDC are referred ...";
CM_ SG_ 2364566014 EngGsFlValve3StartOfActuationCmd "The angle, relative to the TDC of cylinder 3, with 0 being the TDC before the power stroke commences, at the which gaseous fuel valve 3 is activated to open.
Timings after TDC are referred with positive values and timings before TDC are referred ...";
CM_ SG_ 2364566014 EngGsFlValve2StartOfActuationCmd "The angle, relative to the TDC of cylinder 2, with 0 being the TDC before the power stroke commences, at the which gaseous fuel valve 2 is activated to open.
Timings after TDC are referred with positive values and timings before TDC are referred ...";
CM_ SG_ 2364566014 EngGsFlValve1StartOfActuationCmd "The angle, relative to the TDC of cylinder 1, with 0 being the TDC before the power stroke commences, at the which gaseous fuel valve 1 is activated to open.
Timings after TDC are referred with positive values and timings before TDC are referred ...";
CM_ BO_ 2364565758 "Used to transmit the gaseous fuel valve duration command information for valve 17 to valve 20.";
CM_ SG_ 2364565758 EngGasFuelValve20DurationCmd "Amount of time the gaseous fuel valve 20 is activated.";
CM_ SG_ 2364565758 EngGasFuelValve19DurationCmd "Amount of time the gaseous fuel valve 19 is activated.";
CM_ SG_ 2364565758 EngGasFuelValve18DurationCmd "Amount of time the gaseous fuel valve 18 is activated.";
CM_ SG_ 2364565758 EngGasFuelValve17DurationCmd "Amount of time the gaseous fuel valve 17 is activated.";
CM_ BO_ 2364565502 "Used to transmit the gaseous fuel valve duration command information for valve 13 to valve 16.";
CM_ SG_ 2364565502 EngGasFuelValve16DurationCmd "Amount of time the gaseous fuel valve 16 is activated.";
CM_ SG_ 2364565502 EngGasFuelValve15DurationCmd "Amount of time the gaseous fuel valve 15 is activated.";
CM_ SG_ 2364565502 EngGasFuelValve14DurationCmd "Amount of time the gaseous fuel valve 14 is activated.";
CM_ SG_ 2364565502 EngGasFuelValve13DurationCmd "Amount of time the gaseous fuel valve 13 is activated.";
CM_ BO_ 2364565246 "Used to transmit the gaseous fuel valve duration command information for valve 9 to valve 12.";
CM_ SG_ 2364565246 EngGasFuelValve12DurationCmd "Amount of time the gaseous fuel valve 12 is activated.";
CM_ SG_ 2364565246 EngGasFuelValve11DurationCmd "Amount of time the gaseous fuel valve 11 is activated.";
CM_ SG_ 2364565246 EngGasFuelValve10DurationCmd "Amount of time the gaseous fuel valve 10 is activated.";
CM_ SG_ 2364565246 EngGasFuelValve9DurationCmd "Amount of time the gaseous fuel valve 9 is activated.";
CM_ BO_ 2364564990 "Used to transmit the gaseous fuel valve duration command information for valve 5 to valve 8.";
CM_ SG_ 2364564990 EngGasFuelValve8DurationCmd "Amount of time the gaseous fuel valve 8 is activated.";
CM_ SG_ 2364564990 EngGasFuelValve7DurationCmd "Amount of time the gaseous fuel valve 7 is activated.";
CM_ SG_ 2364564990 EngGasFuelValve6DurationCmd "Amount of time the gaseous fuel valve 6 is activated.";
CM_ SG_ 2364564990 EngGasFuelValve5DurationCmd "Amount of time the gaseous fuel valve 5 is activated.";
CM_ BO_ 2364564734 "Used to transmit the gaseous fuel valve duration command information for valve 1 to valve 4.";
CM_ SG_ 2364564734 EngGasFuelValve4DurationCmd "Amount of time the gaseous fuel valve 4 is activated.";
CM_ SG_ 2364564734 EngGasFuelValve3DurationCmd "Amount of time the gaseous fuel valve 3 is activated.";
CM_ SG_ 2364564734 EngGasFuelValve2DurationCmd "Amount of time the gaseous fuel valve 2 is activated.";
CM_ SG_ 2364564734 EngGasFuelValve1DurationCmd "Amount of time the gaseous fuel valve 1 is activated.";
CM_ BO_ 2364564478 "Used to transmit the gaseous fuel valve command information.";
CM_ SG_ 2364564478 EngGsFlVlvNmnlStrtOfActuationCmd "The angle, relative to the TDC of each cylinder, with 0 being the TDC before the power stroke commences, at the which gaseous fuel valves are activated to open.  It's a nominal value used for all the gaseous fuel valves in the engine.
Timings after ...";
CM_ SG_ 2364564478 EngGsFuelValveNominalDurationCmd "Amount of time the gaseous fuel valves are activated.  It's a nominal value used for all the gaseous fuel valves in the engine.

Note: Please see SPNs 6658 - 6677 for duration command for each gaseous fuel valves";
CM_ BO_ 2297455358 "Electronic Transmission Controller #12";
CM_ SG_ 2297455358 TransDirectionalOutputShaftSpeed "The rotational velocity and direction of the output shaft. Positive values are used for forward vehicle motion, negative values for reverse vehicle motion.

SPN 191 should be used when direction is not used.";
CM_ SG_ 2297455358 TransHydrostaticLoop2Press "Oil pressure in the transmission hydrostatic loop #2 between the pump and motor.";
CM_ SG_ 2297455358 TransHydrostaticLoop1Press "Oil pressure in the transmission hydrostatic loop #1 between the pump and motor.";
CM_ BO_ 2498781694 "Used to transmit the average of combustion parameters of Engine Cylinder 20.
This PGN is transmitted at a defined ratio of the engine speed. The transmission rate is dependent on
SPN 6394 - Number of combustion cycles for Averaging. For example, ...";
CM_ SG_ 2498781694 EngCyl20AvrageCombustionDuration "Average duration of combustion calculated over defined number of combustion cycles for engine cylinder 20 with reference to the crank angle.  Combustion duration is the difference between end of combustion and start of combustion expressed, in this ...";
CM_ SG_ 2498781694 EngCyl20AvrgCntrOfCmbstionTiming "Average timing calculated over defined number of combustion cycles for the center of combustion in engine cylinder 20 with reference to the crank angle.  Center of Combustion is used to indicate the combustion efficiency.  When the combustion ...";
CM_ SG_ 2498781694 EngCyl20AvrgStrtOfCmbstionTiming "Average start of combustion timing calculated over defined number of combustion cycles for engine cylinder 20 with reference to the crank angle.  When the combustion happens after the TDC (Top Dead Center) of this cylinder, the timing is referred in ...";
CM_ SG_ 2498781694 EngCyl20IndctdMeanEffectivePress "Average cylinder pressure calculated over defined number of combustion cycles for engine cylinder 20.  Negative range is to cover thermodynamic behavior during misfire.";
CM_ BO_ 2498781438 "Used to transmit the average of combustion parameters of Engine Cylinder 19.
This PGN is transmitted at a defined ratio of the engine speed. The transmission rate is dependent on
SPN 6394 - Number of combustion cycles for Averaging. For example, ...";
CM_ SG_ 2498781438 EngCyl19AvrageCombustionDuration "Average duration of combustion calculated over defined number of combustion cycles for engine cylinder 19 with reference to the crank angle.  Combustion duration is the difference between end of combustion and start of combustion expressed, in this ...";
CM_ SG_ 2498781438 EngCyl19AvrgCntrOfCmbstionTiming "Average timing calculated over defined number of combustion cycles for the center of combustion in engine cylinder 19 with reference to the crank angle.  Center of Combustion is used to indicate the combustion efficiency.  When the combustion ...";
CM_ SG_ 2498781438 EngCyl19AvrgStrtOfCmbstionTiming "Average start of combustion timing calculated over defined number of combustion cycles for engine cylinder 19 with reference to the crank angle.  When the combustion happens after the TDC (Top Dead Center) of this cylinder, the timing is referred in ...";
CM_ SG_ 2498781438 EngCyl19IndctdMeanEffectivePress "Average cylinder pressure calculated over defined number of combustion cycles for engine cylinder 19.  Negative range is to cover thermodynamic behavior during misfire.";
CM_ BO_ 2498781182 "Used to transmit the average of combustion parameters of Engine Cylinder 18.
This PGN is transmitted at a defined ratio of the engine speed. The transmission rate is dependent on
SPN 6394 - Number of combustion cycles for Averaging. For example, ...";
CM_ SG_ 2498781182 EngCyl18AvrageCombustionDuration "Average duration of combustion calculated over defined number of combustion cycles for engine cylinder 18 with reference to the crank angle.  Combustion duration is the difference between end of combustion and start of combustion expressed, in this ...";
CM_ SG_ 2498781182 EngCyl18AvrgCntrOfCmbstionTiming "Average timing calculated over defined number of combustion cycles for the center of combustion in engine cylinder 18 with reference to the crank angle.  Center of Combustion is used to indicate the combustion efficiency.  When the combustion ...";
CM_ SG_ 2498781182 EngCyl18AvrgStrtOfCmbstionTiming "Average start of combustion timing calculated over defined number of combustion cycles for engine cylinder 18 with reference to the crank angle.  When the combustion happens after the TDC (Top Dead Center) of this cylinder, the timing is referred in ...";
CM_ SG_ 2498781182 EngCyl18IndctdMeanEffectivePress "Average cylinder pressure calculated over defined number of combustion cycles for engine cylinder 18.  Negative range is to cover thermodynamic behavior during misfire.";
CM_ BO_ 2498780926 "Used to transmit the average of combustion parameters of Engine Cylinder 17.
This PGN is transmitted at a defined ratio of the engine speed. The transmission rate is dependent on
SPN 6394 - Number of combustion cycles for Averaging. For example, ...";
CM_ SG_ 2498780926 EngCyl17AvrageCombustionDuration "Average duration of combustion calculated over defined number of combustion cycles for engine cylinder 17 with reference to the crank angle.  Combustion duration is the difference between end of combustion and start of combustion expressed, in this ...";
CM_ SG_ 2498780926 EngCyl17AvrgCntrOfCmbstionTiming "Average timing calculated over defined number of combustion cycles for the center of combustion in engine cylinder 17 with reference to the crank angle.  Center of Combustion is used to indicate the combustion efficiency.  When the combustion ...";
CM_ SG_ 2498780926 EngCyl17AvrgStrtOfCmbstionTiming "Average start of combustion timing calculated over defined number of combustion cycles for engine cylinder 17 with reference to the crank angle.  When the combustion happens after the TDC (Top Dead Center) of this cylinder, the timing is referred in ...";
CM_ SG_ 2498780926 EngCyl17IndctdMeanEffectivePress "Average cylinder pressure calculated over defined number of combustion cycles for engine cylinder 17.  Negative range is to cover thermodynamic behavior during misfire.";
CM_ BO_ 2498780670 "Used to transmit the average of combustion parameters of Engine Cylinder 16.
This PGN is transmitted at a defined ratio of the engine speed. The transmission rate is dependent on
SPN 6394 - Number of combustion cycles for Averaging. For example, ...";
CM_ SG_ 2498780670 EngCyl16AvrageCombustionDuration "Average duration of combustion calculated over defined number of combustion cycles for engine cylinder 16 with reference to the crank angle.  Combustion duration is the difference between end of combustion and start of combustion expressed, in this ...";
CM_ SG_ 2498780670 EngCyl16AvrgCntrOfCmbstionTiming "Average timing calculated over defined number of combustion cycles for the center of combustion in engine cylinder 16 with reference to the crank angle.  Center of Combustion is used to indicate the combustion efficiency.  When the combustion ...";
CM_ SG_ 2498780670 EngCyl16AvrgStrtOfCmbstionTiming "Average start of combustion timing calculated over defined number of combustion cycles for engine cylinder 16 with reference to the crank angle.  When the combustion happens after the TDC (Top Dead Center) of this cylinder, the timing is referred in ...";
CM_ SG_ 2498780670 EngCyl16IndctdMeanEffectivePress "Average cylinder pressure calculated over defined number of combustion cycles for engine cylinder 16.  Negative range is to cover thermodynamic behavior during misfire.";
CM_ BO_ 2498780414 "Used to transmit the average of combustion parameters of Engine Cylinder 15.
This PGN is transmitted at a defined ratio of the engine speed. The transmission rate is dependent on
SPN 6394 - Number of combustion cycles for Averaging. For example, ...";
CM_ SG_ 2498780414 EngCyl15AvrageCombustionDuration "Average duration of combustion calculated over defined number of combustion cycles for engine cylinder 15 with reference to the crank angle.  Combustion duration is the difference between end of combustion and start of combustion expressed, in this ...";
CM_ SG_ 2498780414 EngCyl15AvrgCntrOfCmbstionTiming "Average timing calculated over defined number of combustion cycles for the center of combustion in engine cylinder 15 with reference to the crank angle.  Center of Combustion is used to indicate the combustion efficiency.  When the combustion ...";
CM_ SG_ 2498780414 EngCyl15AvrgStrtOfCmbstionTiming "Average start of combustion timing calculated over defined number of combustion cycles for engine cylinder 15 with reference to the crank angle.  When the combustion happens after the TDC (Top Dead Center) of this cylinder, the timing is referred in ...";
CM_ SG_ 2498780414 EngCyl15IndctdMeanEffectivePress "Average cylinder pressure calculated over defined number of combustion cycles for engine cylinder 15.  Negative range is to cover thermodynamic behavior during misfire.";
CM_ BO_ 2498780158 "Used to transmit the average of combustion parameters of Engine Cylinder 14.
This PGN is transmitted at a defined ratio of the engine speed. The transmission rate is dependent on
SPN 6394 - Number of combustion cycles for Averaging. For example, ...";
CM_ SG_ 2498780158 EngCyl14AvrageCombustionDuration "Average duration of combustion calculated over defined number of combustion cycles for engine cylinder 14 with reference to the crank angle.  Combustion duration is the difference between end of combustion and start of combustion expressed, in this ...";
CM_ SG_ 2498780158 EngCyl14AvrgCntrOfCmbstionTiming "Average timing calculated over defined number of combustion cycles for the center of combustion in engine cylinder 14 with reference to the crank angle.  Center of Combustion is used to indicate the combustion efficiency.  When the combustion ...";
CM_ SG_ 2498780158 EngCyl14AvrgStrtOfCmbstionTiming "Average start of combustion timing calculated over defined number of combustion cycles for engine cylinder 14 with reference to the crank angle.  When the combustion happens after the TDC (Top Dead Center) of this cylinder, the timing is referred in ...";
CM_ SG_ 2498780158 EngCyl14IndctdMeanEffectivePress "Average cylinder pressure calculated over defined number of combustion cycles for engine cylinder 14.  Negative range is to cover thermodynamic behavior during misfire.";
CM_ BO_ 2498779902 "Used to transmit the average of combustion parameters of Engine Cylinder 13.
This PGN is transmitted at a defined ratio of the engine speed. The transmission rate is dependent on
SPN 6394 - Number of combustion cycles for Averaging. For example, ...";
CM_ SG_ 2498779902 EngCyl13AvrageCombustionDuration "Average duration of combustion calculated over defined number of combustion cycles for engine cylinder 13 with reference to the crank angle.  Combustion duration is the difference between end of combustion and start of combustion expressed, in this ...";
CM_ SG_ 2498779902 EngCyl13AvrgCntrOfCmbstionTiming "Average timing calculated over defined number of combustion cycles for the center of combustion in engine cylinder 13 with reference to the crank angle.  Center of Combustion is used to indicate the combustion efficiency.  When the combustion ...";
CM_ SG_ 2498779902 EngCyl13AvrgStrtOfCmbstionTiming "Average start of combustion timing calculated over defined number of combustion cycles for engine cylinder 13 with reference to the crank angle.  When the combustion happens after the TDC (Top Dead Center) of this cylinder, the timing is referred in ...";
CM_ SG_ 2498779902 EngCyl13IndctdMeanEffectivePress "Average cylinder pressure calculated over defined number of combustion cycles for engine cylinder 13.  Negative range is to cover thermodynamic behavior during misfire.";
CM_ BO_ 2498779646 "Used to transmit the average of combustion parameters of Engine Cylinder 12.
This PGN is transmitted at a defined ratio of the engine speed. The transmission rate is dependent on
SPN 6394 - Number of combustion cycles for Averaging. For example, ...";
CM_ SG_ 2498779646 EngCyl12AvrageCombustionDuration "Average duration of combustion calculated over defined number of combustion cycles for engine cylinder 12 with reference to the crank angle.  Combustion duration is the difference between end of combustion and start of combustion expressed, in this ...";
CM_ SG_ 2498779646 EngCyl12AvrgCntrOfCmbstionTiming "Average timing calculated over defined number of combustion cycles for the center of combustion in engine cylinder 12 with reference to the crank angle.  Center of Combustion is used to indicate the combustion efficiency.  When the combustion ...";
CM_ SG_ 2498779646 EngCyl12AvrgStrtOfCmbstionTiming "Average start of combustion timing calculated over defined number of combustion cycles for engine cylinder 12 with reference to the crank angle.  When the combustion happens after the TDC (Top Dead Center) of this cylinder, the timing is referred in ...";
CM_ SG_ 2498779646 EngCyl12IndctdMeanEffectivePress "Average cylinder pressure calculated over defined number of combustion cycles for engine cylinder 12.  Negative range is to cover thermodynamic behavior during misfire.";
CM_ BO_ 2498779390 "Used to transmit the average of combustion parameters of Engine Cylinder 11.
This PGN is transmitted at a defined ratio of the engine speed. The transmission rate is dependent on
SPN 6394 - Number of combustion cycles for Averaging. For example, ...";
CM_ SG_ 2498779390 EngCyl11AvrageCombustionDuration "Average duration of combustion calculated over defined number of combustion cycles for engine cylinder 11 with reference to the crank angle.  Combustion duration is the difference between end of combustion and start of combustion expressed, in this ...";
CM_ SG_ 2498779390 EngCyl11AvrgCntrOfCmbstionTiming "Average timing calculated over defined number of combustion cycles for the center of combustion in engine cylinder 11 with reference to the crank angle.  Center of Combustion is used to indicate the combustion efficiency.  When the combustion ...";
CM_ SG_ 2498779390 EngCyl11AvrgStrtOfCmbstionTiming "Average start of combustion timing calculated over defined number of combustion cycles for engine cylinder 11 with reference to the crank angle.  When the combustion happens after the TDC (Top Dead Center) of this cylinder, the timing is referred in ...";
CM_ SG_ 2498779390 EngCyl11IndctdMeanEffectivePress "Average cylinder pressure calculated over defined number of combustion cycles for engine cylinder 11.  Negative range is to cover thermodynamic behavior during misfire.";
CM_ BO_ 2498779134 "Used to transmit the average of combustion parameters of Engine Cylinder 10.
This PGN is transmitted at a defined ratio of the engine speed. The transmission rate is dependent on
SPN 6394 - Number of combustion cycles for Averaging. For example, ...";
CM_ SG_ 2498779134 EngCyl10AvrageCombustionDuration "Average duration of combustion calculated over defined number of combustion cycles for engine cylinder 10 with reference to the crank angle.  Combustion duration is the difference between end of combustion and start of combustion expressed, in this ...";
CM_ SG_ 2498779134 EngCyl10AvrgCntrOfCmbstionTiming "Average timing calculated over defined number of combustion cycles for the center of combustion in engine cylinder 10 with reference to the crank angle.  Center of Combustion is used to indicate the combustion efficiency.  When the combustion ...";
CM_ SG_ 2498779134 EngCyl10AvrgStrtOfCmbstionTiming "Average start of combustion timing calculated over defined number of combustion cycles for engine cylinder 10 with reference to the crank angle.  When the combustion happens after the TDC (Top Dead Center) of this cylinder, the timing is referred in ...";
CM_ SG_ 2498779134 EngCyl10IndctdMeanEffectivePress "Average cylinder pressure calculated over defined number of combustion cycles for engine cylinder 10.  Negative range is to cover thermodynamic behavior during misfire.";
CM_ BO_ 2498778878 "Used to transmit the average of combustion parameters of Engine Cylinder 9.
This PGN is transmitted at a defined ratio of the engine speed. The transmission rate is dependent on
SPN 6394 - Number of combustion cycles for Averaging. For example, if ...";
CM_ SG_ 2498778878 EngCyl9AverageCombustionDuration "Average duration of combustion calculated over defined number of combustion cycles for engine cylinder 9 with reference to the crank angle.  Combustion duration is the difference between end of combustion and start of combustion expressed, in this ...";
CM_ SG_ 2498778878 EngCyl9AvrgCntrOfCmbustionTiming "Average timing calculated over defined number of combustion cycles for the center of combustion in engine cylinder 9 with reference to the crank angle.  Center of Combustion is used to indicate the combustion efficiency.  When the combustion happens ...";
CM_ SG_ 2498778878 EngCyl9AvrgStrtOfCmbustionTiming "Average start of combustion timing calculated over defined number of combustion cycles for engine cylinder 9 with reference to the crank angle.  When the combustion happens after the TDC (Top Dead Center) of this cylinder, the timing is referred in ...";
CM_ SG_ 2498778878 EngCyl9IndctedMeanEffectivePress "Average cylinder pressure calculated over defined number of combustion cycles for engine cylinder 9.  Negative range is to cover thermodynamic behavior during misfire.";
CM_ BO_ 2365430526 "Message to transmit data of the towed vehicle to the towing vehicle. See ISO 11992-3.";
CM_ BO_ 2357919486 "Message to transmit data of the towing vehicle to the towed vehicle. See ISO 11992-2.";
CM_ BO_ 2357853950 "Message to transmit data of the towed vehicle to the towing vehicle. See ISO 11992-2.";
CM_ BO_ 2365428734 "Message for the generator set control to change or report the status of the generator system.";
CM_ SG_ 2365428734 GenFrequencySelection "Command from user and/or generator control system for the genset (engine) to target operations for 50 Hz, 60 Hz, or 400 Hz.

0000 = 50 Hz
0001 = 60 Hz
0010 = 400 Hz
0011 - 1101 = SAE Reserved
1110 = Unknown
1111= Don't care /take no action";
CM_ SG_ 2365428734 GenGoverningSpeedCommand "Command from user and/or generator control system for the genset (engine) to govern to low idle or rated base speed setpoints.  If this method of engine control is used, then the PGN 0 (TSC1) is not expected to be received by the engine controller ...";
CM_ SG_ 2365428734 GenAlternatorEfficiency "Measured, calculated, and/or estimated operating efficiency of the generator alternator.  Percentage reflects ratio of power output divided by power input, multiplied by 100.";
CM_ SG_ 2365428734 GenNotReadyToAutoParaState "This parameter indicates whether or not all systems required to start the engine and close to the bus are prepared to operate automatically. If not, the generator is not ready to automatically parallel, and the status parameter is in the ACTIVE ...";
CM_ SG_ 2365428734 GenCtrlNotInAutoStartState "This parameter indicates whether or not the generator set is in a condition to automatically start up and provide power. If not, this status parameter is in the ACTIVE state.
00 = inactive (ready to start automatically)
01 = active (not ready to ...";
CM_ SG_ 2365428734 RequestedEngineControlMode "This parameter is used to request a change to the engine control mode.  This is a status parameter.
Bit state 0000 = Normal Engine Shutdown
Bit state 0001 = Rapid Engine Shutdown
Bit state 0010 = Emergency Engine Shutdown
Bit state 0011 = Normal ...";
CM_ SG_ 2365428734 EngSpeedGovernorDroop "This is the percent speed droop adjustment relative to rated speed setpoint. The Engine Speed Droop is equal to the following equation:
100*[(Engine Speed at no load - Engine Speed at full rated load)/ (Engine Speed at full rated load)].
The ...";
CM_ SG_ 2365428734 EngSpeedGovernorGainAdjust "This parameter is used to adjust multiple gains at same time to attain engine stability across a broader range of applications.  

-32128 is least responsive
0 is normal
+32127 is most responsive";
CM_ BO_ 2365376254 "OBD Information";
CM_ SG_ 2365376254 EngOBDWarmUpSequence "Engine warm-up as defined by the applicable region's regulatory agency.  In the US, \"Engine OBD Warm-up\" or “Warm-up cycle” means sufficient vehicle operation such that coolant temperature rises by at least 22.2 °C (40 °F) from engine starting and ...";
CM_ BO_ 2566703102 "Engine Emissions Certification Information";
CM_ SG_ 2566703102 CertificationEngineFamilyName "The regulated family name per the applicable region's certification agency.  For engines certified in the US, this shall be the 12-character engine family name or test group as defined by EPA.  Up to 200 characters may be used.  The characters are ...";
CM_ SG_ 2566703102 ModelYear "The compliance model year of the OBD system of the engine and or vehicle.  For example in the US, this is associated with either a vehicle model year or an engine model year, depending on how the emissions and OBD are certified.  This message shall ...";
CM_ BO_ 2566705918 "Previously Active Service Only DTCs";
CM_ SG_ 2566705918 DTC1 "Diagnostic Trouble Code";
CM_ SG_ 2566705918 FlashProtectLamp "This parameter provides the capability to flash the engine protect lamp


00 - Slow Flash (1 Hz, 50 % duty cycle)
01 - Fast Flash (2 Hz or faster, 50% duty cycle)
10 - Reserved
11 - Unavailable / Do Not Flash";
CM_ SG_ 2566705918 FlashAmberWarningLamp "This parameter provides the capability to flash the AWL

00 - Slow Flash (1 Hz, 50 % duty cycle)
01 - Fast Flash (2 Hz or faster, 50% duty cycle)
10 - Reserved
11 - Unavailable / Do Not Flash";
CM_ SG_ 2566705918 FlashRedStopLamp "This parameter provides the capability to flash the RSL


00 - Slow Flash (1 Hz, 50 % duty cycle)
01 - Fast Flash (2 Hz or faster, 50% duty cycle)
10 - Reserved
11 - Unavailable / Do Not Flash";
CM_ SG_ 2566705918 FlashMalfuncIndicatorLamp "This parameter provides the capability to flash the MIL
00 - Slow Flash (1 Hz, 50 % duty cycle)
01 - Fast Flash (2 Hz or faster, 50% duty cycle)
10 - Class C DTC
11 - Unavailable / Do Not Flash
Note:  State 10 is for WWH OBD discriminatory ...";
CM_ SG_ 2566705918 ProtectLampStatus "This lamp is used to relay trouble code information that is reporting a problem with a vehicle system that is most probably not electronic subsystem related. For instance, engine coolant temperature is exceeding its prescribed temperature range.
00 ...";
CM_ SG_ 2566705918 AmberWarningLampStatus "This lamp is used to relay trouble code information that is reporting a problem with the vehicle system but the vehicle need not be immediately stopped. 

00     Lamp Off
01     Lamp On
10     Reserved
11     Not available";
CM_ SG_ 2566705918 RedStopLampState "This lamp is used to relay trouble code information that is of a severe enough condition that it warrants stopping the vehicle.

00     Lamp Off
01     Lamp On
10     Reserved
11     Not available";
CM_ SG_ 2566705918 MalfunctionIndicatorLampStatus "A lamp used to relay only emissions-related trouble code information. This lamp is only illuminated when there is an emission-related trouble code active.
00     Lamp Off
01     Lamp On
10     Short MIL for WWH OBD
11     Not available
Note ...";
CM_ SG_ 2566705918 DTC5 "Diagnostic Trouble Code";
CM_ SG_ 2566705918 DTC4 "Diagnostic Trouble Code";
CM_ SG_ 2566705918 DTC3 "Diagnostic Trouble Code";
CM_ SG_ 2566705918 DTC2 "Diagnostic Trouble Code";
CM_ BO_ 2566705662 "Active Service Only DTCs";
CM_ SG_ 2566705662 DTC1 "Diagnostic Trouble Code";
CM_ SG_ 2566705662 FlashProtectLamp "This parameter provides the capability to flash the engine protect lamp


00 - Slow Flash (1 Hz, 50 % duty cycle)
01 - Fast Flash (2 Hz or faster, 50% duty cycle)
10 - Reserved
11 - Unavailable / Do Not Flash";
CM_ SG_ 2566705662 FlashAmberWarningLamp "This parameter provides the capability to flash the AWL

00 - Slow Flash (1 Hz, 50 % duty cycle)
01 - Fast Flash (2 Hz or faster, 50% duty cycle)
10 - Reserved
11 - Unavailable / Do Not Flash";
CM_ SG_ 2566705662 FlashRedStopLamp "This parameter provides the capability to flash the RSL


00 - Slow Flash (1 Hz, 50 % duty cycle)
01 - Fast Flash (2 Hz or faster, 50% duty cycle)
10 - Reserved
11 - Unavailable / Do Not Flash";
CM_ SG_ 2566705662 FlashMalfuncIndicatorLamp "This parameter provides the capability to flash the MIL
00 - Slow Flash (1 Hz, 50 % duty cycle)
01 - Fast Flash (2 Hz or faster, 50% duty cycle)
10 - Class C DTC
11 - Unavailable / Do Not Flash
Note:  State 10 is for WWH OBD discriminatory ...";
CM_ SG_ 2566705662 ProtectLampStatus "This lamp is used to relay trouble code information that is reporting a problem with a vehicle system that is most probably not electronic subsystem related. For instance, engine coolant temperature is exceeding its prescribed temperature range.
00 ...";
CM_ SG_ 2566705662 AmberWarningLampStatus "This lamp is used to relay trouble code information that is reporting a problem with the vehicle system but the vehicle need not be immediately stopped. 

00     Lamp Off
01     Lamp On
10     Reserved
11     Not available";
CM_ SG_ 2566705662 RedStopLampState "This lamp is used to relay trouble code information that is of a severe enough condition that it warrants stopping the vehicle.

00     Lamp Off
01     Lamp On
10     Reserved
11     Not available";
CM_ SG_ 2566705662 MalfunctionIndicatorLampStatus "A lamp used to relay only emissions-related trouble code information. This lamp is only illuminated when there is an emission-related trouble code active.
00     Lamp Off
01     Lamp On
10     Short MIL for WWH OBD
11     Not available
Note ...";
CM_ SG_ 2566705662 DTC5 "Diagnostic Trouble Code";
CM_ SG_ 2566705662 DTC4 "Diagnostic Trouble Code";
CM_ SG_ 2566705662 DTC3 "Diagnostic Trouble Code";
CM_ SG_ 2566705662 DTC2 "Diagnostic Trouble Code";
CM_ BO_ 2365379582 "All of the diagnostic information pertaining to the active service only diagnostic trouble codes and previously active diagnostic trouble codes should be erased as well as the DTCs.";
CM_ BO_ 2349465342 "Contains Static Roll Angle Data and Status of the Static Roll Angle Sensor";
CM_ SG_ 2349465342 StaticRollAngleStatus "Status of the transmitted roll angle data.

000 = Sensor Busy
001 = Sensor OK
010 = Sensor Defect
011 = Sensor Reboots
100 = Angle Data Invalid
101 = Reserved
110 = Error
111 = Not available";
CM_ SG_ 2349465342 StaticRollAngle "The measured static roll angle between the vehicle y-axis and the ground plane about the X-axis.  The sign of the roll angle is determined in accordance to the right-hand rule about the X-axis, as specified in SAE J670.  Roll angle is the same for ...";
CM_ BO_ 2498777086 "Used to transmit the average of combustion parameters of Engine Cylinder 2.
This PGN is transmitted at a defined ratio of the engine speed. The transmission rate is dependent on
SPN 6394 - Number of combustion cycles for Averaging. For example, if ...";
CM_ SG_ 2498777086 EngCyl2AverageCombustionDuration "Average duration of combustion calculated over defined number of combustion cycles for engine cylinder 2 with reference to the crank angle.  Combustion duration is the difference between end of combustion and start of combustion expressed, in this ...";
CM_ SG_ 2498777086 EngCyl2AvrgCntrOfCmbustionTiming "Average timing calculated over defined number of combustion cycles for the center of combustion in engine cylinder 2 with reference to the crank angle.  Center of Combustion is used to indicate the combustion efficiency.  When the combustion happens ...";
CM_ SG_ 2498777086 EngCyl2AvrgStrtOfCmbustionTiming "Average start of combustion timing calculated over defined number of combustion cycles for engine cylinder 2 with reference to the crank angle.  When the combustion happens after the TDC (Top Dead Center) of this cylinder, the timing is referred in ...";
CM_ SG_ 2498777086 EngCyl2IndctedMeanEffectivePress "Average cylinder pressure calculated over defined number of combustion cycles for engine cylinder 2.  Negative range is to cover thermodynamic behavior during misfire.";
CM_ BO_ 2498776830 "Used to transmit the average of combustion parameters of Engine Cylinder 1.
This PGN is transmitted at a defined ratio of the engine speed. The transmission rate is dependent on
SPN 6394 - Number of combustion cycles for Averaging. For example, if ...";
CM_ SG_ 2498776830 EngCyl1AverageCombustionDuration "Average duration of combustion calculated over defined number of combustion cycles for engine cylinder 1 with reference to the crank angle.  Combustion duration is the difference between end of combustion and start of combustion expressed, in this ...";
CM_ SG_ 2498776830 EngCyl1AvrgCntrOfCmbustionTiming "Average timing calculated over defined number of combustion cycles for the center of combustion in engine cylinder 1 with reference to the crank angle.  Center of Combustion is used to indicate the combustion efficiency.  When the combustion happens ...";
CM_ SG_ 2498776830 EngCyl1AvrgStrtOfCmbustionTiming "Average start of combustion timing calculated over defined number of combustion cycles for engine cylinder 1 with reference to the crank angle.  When the combustion happens after the TDC (Top Dead Center) of this cylinder, the timing is referred in ...";
CM_ SG_ 2498776830 EngCyl1IndctedMeanEffectivePress "Average cylinder pressure calculated over defined number of combustion cycles for engine cylinder 1.   Negative range is to cover thermodynamic behavior during misfire.";
CM_ BO_ 2364558846 "Used to communicate combustion information of Engine Cylinder 20. The PGN is transmitted at the end of every combustion in Cylinder 20.";
CM_ SG_ 2364558846 EngCyl20PrssSensorPreliminaryFMI "Used to identify the applicable J1939-73 FMI detected in the engine cylinder 20 pressure sensor.  When there is no failure FMI 31 is sent. In the case of multiple failures the most severe is communicated.";
CM_ SG_ 2364558846 EngCyl20SynchronousKnockLevel "Used to indicate the level of knock for engine cylinder 20. The level of knock is reported using a relative scale where 0% is least level of knock, and increasing levels indicate more knock until 100% indicates the most severe level of knock allowed ...";
CM_ SG_ 2364558846 EngCyl20PeakPress "Peak pressure in engine cylinder 20 in combustion cycle.";
CM_ SG_ 2364558846 EngCyl20HeatRelease "The amount of heat produced during combustion in engine cylinder 20.  The negative range is to cover thermodynamic behavior during misfire.";
CM_ BO_ 2364558590 "Used to communicate combustion information of Engine Cylinder 19. The PGN is transmitted at the end of every combustion in Cylinder 19.";
CM_ SG_ 2364558590 EngCyl19PrssSensorPreliminaryFMI "Used to identify the applicable J1939-73 FMI detected in the engine cylinder 19 pressure sensor.  When there is no failure FMI 31 is sent. In the case of multiple failures the most severe is communicated.";
CM_ SG_ 2364558590 EngCyl19SynchronousKnockLevel "Used to indicate the level of knock for engine cylinder 19. The level of knock is reported using a relative scale where 0% is least level of knock, and increasing levels indicate more knock until 100% indicates the most severe level of knock allowed ...";
CM_ SG_ 2364558590 EngCyl19PeakPress "Peak pressure in engine cylinder 19 in combustion cycle.";
CM_ SG_ 2364558590 EngCyl19HeatRelease "The amount of heat produced during combustion in engine cylinder 19.  The negative range is to cover thermodynamic behavior during misfire.";
CM_ BO_ 2364558334 "Used to communicate combustion information of Engine Cylinder 18. The PGN is transmitted at the end of every combustion in Cylinder 18.";
CM_ SG_ 2364558334 EngCyl18PrssSensorPreliminaryFMI "Used to identify the applicable J1939-73 FMI detected in the engine cylinder 18 pressure sensor.  When there is no failure FMI 31 is sent. In the case of multiple failures the most severe is communicated.";
CM_ SG_ 2364558334 EngCyl18SynchronousKnockLevel "Used to indicate the level of knock for engine cylinder 18. The level of knock is reported using a relative scale where 0% is least level of knock, and increasing levels indicate more knock until 100% indicates the most severe level of knock allowed ...";
CM_ SG_ 2364558334 EngCyl18PeakPress "Peak pressure in engine cylinder 18 in combustion cycle.";
CM_ SG_ 2364558334 EngCyl18HeatRelease "The amount of heat produced during combustion in engine cylinder 18.  The negative range is to cover thermodynamic behavior during misfire.";
CM_ BO_ 2364558078 "Used to communicate combustion information of Engine Cylinder 17. The PGN is transmitted at the end of every combustion in Cylinder 17.";
CM_ SG_ 2364558078 EngCyl17PrssSensorPreliminaryFMI "Used to identify the applicable J1939-73 FMI detected in the engine cylinder 17 pressure sensor.  When there is no failure FMI 31 is sent. In the case of multiple failures the most severe is communicated.";
CM_ SG_ 2364558078 EngCyl17SynchronousKnockLevel "Used to indicate the level of knock for engine cylinder 17. The level of knock is reported using a relative scale where 0% is least level of knock, and increasing levels indicate more knock until 100% indicates the most severe level of knock allowed ...";
CM_ SG_ 2364558078 EngCyl17PeakPress "Peak pressure in engine cylinder 17 in combustion cycle.";
CM_ SG_ 2364558078 EngCyl17HeatRelease "The amount of heat produced during combustion in engine cylinder 17.  The negative range is to cover thermodynamic behavior during misfire.";
CM_ BO_ 2364557822 "Used to communicate combustion information of Engine Cylinder 16. The PGN is transmitted at the end of every combustion in Cylinder 16.";
CM_ SG_ 2364557822 EngCyl16PrssSensorPreliminaryFMI "Used to identify the applicable J1939-73 FMI detected in the engine cylinder 16 pressure sensor.  When there is no failure FMI 31 is sent. In the case of multiple failures the most severe is communicated.";
CM_ SG_ 2364557822 EngCyl16SynchronousKnockLevel "Used to indicate the level of knock for engine cylinder 16. The level of knock is reported using a relative scale where 0% is least level of knock, and increasing levels indicate more knock until 100% indicates the most severe level of knock allowed ...";
CM_ SG_ 2364557822 EngCyl16PeakPress "Peak pressure in engine cylinder 16 in combustion cycle.";
CM_ SG_ 2364557822 EngCyl16HeatRelease "The amount of heat produced during combustion in engine cylinder 16.  The negative range is to cover thermodynamic behavior during misfire.";
CM_ BO_ 2364557566 "Used to communicate combustion information of Engine Cylinder 15. The PGN is transmitted at the end of every combustion in Cylinder 15.";
CM_ SG_ 2364557566 EngCyl15PrssSensorPreliminaryFMI "Used to identify the applicable J1939-73 FMI detected in the engine cylinder 15 pressure sensor.  When there is no failure FMI 31 is sent. In the case of multiple failures the most severe is communicated.";
CM_ SG_ 2364557566 EngCyl15SynchronousKnockLevel "Used to indicate the level of knock for engine cylinder 15. The level of knock is reported using a relative scale where 0% is least level of knock, and increasing levels indicate more knock until 100% indicates the most severe level of knock allowed ...";
CM_ SG_ 2364557566 EngCyl15PeakPress "Peak pressure in engine cylinder 15 in combustion cycle.";
CM_ SG_ 2364557566 EngCyl15HeatRelease "The amount of heat produced during combustion in engine cylinder 15.  The negative range is to cover thermodynamic behavior during misfire.";
CM_ BO_ 2364557310 "Used to communicate combustion information of Engine Cylinder 14. The PGN is transmitted at the end of every combustion in Cylinder 14.";
CM_ SG_ 2364557310 EngCyl14PrssSensorPreliminaryFMI "Used to identify the applicable J1939-73 FMI detected in the engine cylinder 14 pressure sensor.  When there is no failure FMI 31 is sent. In the case of multiple failures the most severe is communicated.";
CM_ SG_ 2364557310 EngCyl14SynchronousKnockLevel "Used to indicate the level of knock for engine cylinder 14. The level of knock is reported using a relative scale where 0% is least level of knock, and increasing levels indicate more knock until 100% indicates the most severe level of knock allowed ...";
CM_ SG_ 2364557310 EngCyl14PeakPress "Peak pressure in engine cylinder 14 in combustion cycle.";
CM_ SG_ 2364557310 EngCyl14HeatRelease "The amount of heat produced during combustion in engine cylinder 14.  The negative range is to cover thermodynamic behavior during misfire.";
CM_ BO_ 2364557054 "Used to communicate combustion information of Engine Cylinder 13. The PGN is transmitted at the end of every combustion in Cylinder 13.";
CM_ SG_ 2364557054 EngCyl13PrssSensorPreliminaryFMI "Used to identify the applicable J1939-73 FMI detected in the engine cylinder 13 pressure sensor.  When there is no failure FMI 31 is sent. In the case of multiple failures the most severe is communicated.";
CM_ SG_ 2364557054 EngCyl13SynchronousKnockLevel "Used to indicate the level of knock for engine cylinder 13. The level of knock is reported using a relative scale where 0% is least level of knock, and increasing levels indicate more knock until 100% indicates the most severe level of knock allowed ...";
CM_ SG_ 2364557054 EngCyl13PeakPress "Peak pressure in engine cylinder 13 in combustion cycle.";
CM_ SG_ 2364557054 EngCyl13HeatRelease "The amount of heat produced during combustion in engine cylinder 13.  The negative range is to cover thermodynamic behavior during misfire.";
CM_ BO_ 2364556798 "Used to communicate combustion information of Engine Cylinder 12. The PGN is transmitted at the end of every combustion in Cylinder 12.";
CM_ SG_ 2364556798 EngCyl12PrssSensorPreliminaryFMI "Used to identify the applicable J1939-73 FMI detected in the engine cylinder 12 pressure sensor.  When there is no failure FMI 31 is sent. In the case of multiple failures the most severe is communicated.";
CM_ SG_ 2364556798 EngCyl12SynchronousKnockLevel "Used to indicate the level of knock for engine cylinder 12. The level of knock is reported using a relative scale where 0% is least level of knock, and increasing levels indicate more knock until 100% indicates the most severe level of knock allowed ...";
CM_ SG_ 2364556798 EngCyl12PeakPress "Peak pressure in engine cylinder 12 in combustion cycle.";
CM_ SG_ 2364556798 EngCyl12HeatRelease "The amount of heat produced during combustion in engine cylinder 12.  The negative range is to cover thermodynamic behavior during misfire.";
CM_ BO_ 2364556542 "Used to communicate combustion information of Engine Cylinder 11. The PGN is transmitted at the end of every combustion in Cylinder 11.";
CM_ SG_ 2364556542 EngCyl11PrssSensorPreliminaryFMI "Used to identify the applicable J1939-73 FMI detected in the engine cylinder 11 pressure sensor.  When there is no failure FMI 31 is sent. In the case of multiple failures the most severe is communicated.";
CM_ SG_ 2364556542 EngCyl11SynchronousKnockLevel "Used to indicate the level of knock for engine cylinder 11. The level of knock is reported using a relative scale where 0% is least level of knock, and increasing levels indicate more knock until 100% indicates the most severe level of knock allowed ...";
CM_ SG_ 2364556542 EngCyl11PeakPress "Peak pressure in engine cylinder 11 in combustion cycle.";
CM_ SG_ 2364556542 EngCyl11HeatRelease "The amount of heat produced during combustion in engine cylinder 11.  The negative range is to cover thermodynamic behavior during misfire.";
CM_ BO_ 2364556286 "Used to communicate combustion information of Engine Cylinder 10. The PGN is transmitted at the end of every combustion in Cylinder 10.";
CM_ SG_ 2364556286 EngCyl10PrssSensorPreliminaryFMI "Used to identify the applicable J1939-73 FMI detected in the engine cylinder 10 pressure sensor.  When there is no failure FMI 31 is sent. In the case of multiple failures the most severe is communicated.";
CM_ SG_ 2364556286 EngCyl10SynchronousKnockLevel "Used to indicate the level of knock for engine cylinder 10. The level of knock is reported using a relative scale where 0% is least level of knock, and increasing levels indicate more knock until 100% indicates the most severe level of knock allowed ...";
CM_ SG_ 2364556286 EngCyl10PeakPress "Peak pressure in engine cylinder 10 in combustion cycle.";
CM_ SG_ 2364556286 EngCyl10HeatRelease "The amount of heat produced during combustion in engine cylinder 10.  The negative range is to cover thermodynamic behavior during misfire.";
CM_ BO_ 2364556030 "Used to communicate combustion information of Engine Cylinder 9. The PGN is transmitted at the end of every combustion in Cylinder 9.";
CM_ SG_ 2364556030 EngCyl9PressSensorPreliminaryFMI "Used to identify the applicable J1939-73 FMI detected in the engine cylinder 9 pressure sensor.  When there is no failure FMI 31 is sent. In the case of multiple failures the most severe is communicated.";
CM_ SG_ 2364556030 EngCyl9SynchronousKnockLevel "Used to indicate the level of knock for engine cylinder 9. The level of knock is reported using a relative scale where 0% is least level of knock, and increasing levels indicate more knock until 100% indicates the most severe level of knock allowed ...";
CM_ SG_ 2364556030 EngCyl9PeakPress "Peak pressure in engine cylinder 9 in combustion cycle.";
CM_ SG_ 2364556030 EngCyl9HeatRelease "The amount of heat produced during combustion in engine cylinder 9.  The negative range is to cover thermodynamic behavior during misfire.";
CM_ BO_ 2364555774 "Used to communicate combustion information of Engine Cylinder 8. The PGN is transmitted at the end of every combustion in Cylinder 8.";
CM_ SG_ 2364555774 EngCyl8PressSensorPreliminaryFMI "Used to identify the applicable J1939-73 FMI detected in the engine cylinder 8 pressure sensor.  When there is no failure FMI 31 is sent. In the case of multiple failures the most severe is communicated.";
CM_ SG_ 2364555774 EngCyl8SynchronousKnockLevel "Used to indicate the level of knock for engine cylinder 8. The level of knock is reported using a relative scale where 0% is least level of knock, and increasing levels indicate more knock until 100% indicates the most severe level of knock allowed ...";
CM_ SG_ 2364555774 EngCyl8PeakPress "Peak pressure in engine cylinder 8 in combustion cycle.";
CM_ SG_ 2364555774 EngCyl8HeatRelease "The amount of heat produced during combustion in engine cylinder 8.  The negative range is to cover thermodynamic behavior during misfire.";
CM_ BO_ 2364555518 "Used to communicate combustion information of Engine Cylinder 7. The PGN is transmitted at the end of every combustion in Cylinder 7.";
CM_ SG_ 2364555518 EngCyl7PressSensorPreliminaryFMI "Used to identify the applicable J1939-73 FMI detected in the engine cylinder 7 pressure sensor.  When there is no failure FMI 31 is sent. In the case of multiple failures the most severe is communicated.";
CM_ SG_ 2364555518 EngCyl7SynchronousKnockLevel "Used to indicate the level of knock for engine cylinder 7. The level of knock is reported using a relative scale where 0% is least level of knock, and increasing levels indicate more knock until 100% indicates the most severe level of knock allowed ...";
CM_ SG_ 2364555518 EngCyl7PeakPress "Peak pressure in engine cylinder 7 in combustion cycle.";
CM_ SG_ 2364555518 EngCyl7HeatRelease "The amount of heat produced during combustion in engine cylinder 7.  The negative range is to cover thermodynamic behavior during misfire.";
CM_ BO_ 2364555262 "Used to communicate combustion information of Engine Cylinder 6. The PGN is transmitted at the end of every combustion in Cylinder 6.";
CM_ SG_ 2364555262 EngCyl6PressSensorPreliminaryFMI "Used to identify the applicable J1939-73 FMI detected in the engine cylinder 6 pressure sensor.  When there is no failure FMI 31 is sent. In the case of multiple failures the most severe is communicated.";
CM_ SG_ 2364555262 EngCyl6SynchronousKnockLevel "Used to indicate the level of knock for engine cylinder 6. The level of knock is reported using a relative scale where 0% is least level of knock, and increasing levels indicate more knock until 100% indicates the most severe level of knock allowed ...";
CM_ SG_ 2364555262 EngCyl6PeakPress "Peak pressure in engine cylinder 6 in combustion cycle.";
CM_ SG_ 2364555262 EngCyl6HeatRelease "The amount of heat produced during combustion in engine cylinder 6.  The negative range is to cover thermodynamic behavior during misfire.";
CM_ BO_ 2364555006 "Used to communicate combustion information of Engine Cylinder 5. The PGN is transmitted at the end of every combustion in Cylinder 5.";
CM_ SG_ 2364555006 EngCyl5PressSensorPreliminaryFMI "Used to identify the applicable J1939-73 FMI detected in the engine cylinder 5 pressure sensor.  When there is no failure FMI 31 is sent. In the case of multiple failures the most severe is communicated.";
CM_ SG_ 2364555006 EngCyl5SynchronousKnockLevel "Used to indicate the level of knock for engine cylinder 6. The level of knock is reported using a relative scale where 0% is least level of knock, and increasing levels indicate more knock until 100% indicates the most severe level of knock allowed ...";
CM_ SG_ 2364555006 EngCyl5PeakPress "Peak pressure in engine cylinder 5 in combustion cycle.";
CM_ SG_ 2364555006 EngCyl5HeatRelease "The amount of heat produced during combustion in engine cylinder 5.  The negative range is to cover thermodynamic behavior during misfire.";
CM_ BO_ 2364554750 "Used to communicate combustion information of Engine Cylinder 4. The PGN is transmitted at the end of every combustion in Cylinder 4.";
CM_ SG_ 2364554750 EngCyl4PressSensorPreliminaryFMI "Used to identify the applicable J1939-73 FMI detected in the engine cylinder 4 pressure sensor.  When there is no failure FMI 31 is sent. In the case of multiple failures the most severe is communicated.";
CM_ SG_ 2364554750 EngCyl4SynchronousKnockLevel "Used to indicate the level of knock for engine cylinder 4. The level of knock is reported using a relative scale where 0% is least level of knock, and increasing levels indicate more knock until 100% indicates the most severe level of knock allowed ...";
CM_ SG_ 2364554750 EngCyl4PeakPress "Peak pressure in engine cylinder 4 in combustion cycle.";
CM_ SG_ 2364554750 EngCyl4HeatRelease "The amount of heat produced during combustion in engine cylinder 4.  The negative range is to cover thermodynamic behavior during misfire.";
CM_ BO_ 2364554494 "Used to communicate combustion information of Engine Cylinder 3. The PGN is transmitted at the end of every combustion in Cylinder 3.";
CM_ SG_ 2364554494 EngCyl3PressSensorPreliminaryFMI "Used to identify the applicable J1939-73 FMI detected in the engine cylinder 3 pressure sensor.  When there is no failure FMI 31 is sent. In the case of multiple failures the most severe is communicated.";
CM_ SG_ 2364554494 EngCyl3SynchronousKnockLevel "Used to indicate the level of knock for engine cylinder 3. The level of knock is reported using a relative scale where 0% is least level of knock, and increasing levels indicate more knock until 100% indicates the most severe level of knock allowed ...";
CM_ SG_ 2364554494 EngCyl3PeakPress "Peak pressure in engine cylinder 3 in combustion cycle.";
CM_ SG_ 2364554494 EngCyl3HeatRelease "The amount of heat produced during combustion in engine cylinder 3.  The negative range is to cover thermodynamic behavior during misfire.";
CM_ BO_ 2364554238 "Used to communicate combustion information of Engine Cylinder 2. The PGN is transmitted at the end of every combustion in Cylinder 2.";
CM_ SG_ 2364554238 EngCyl2PressSensorPreliminaryFMI "Used to identify the applicable J1939-73 FMI detected in the engine cylinder 2 pressure sensor.  When there is no failure FMI 31 is sent. In the case of multiple failures the most severe is communicated.";
CM_ SG_ 2364554238 EngCyl2SynchronousKnockLevel "Used to indicate the level of knock for engine cylinder 2. The level of knock is reported using a relative scale where 0% is least level of knock, and increasing levels indicate more knock until 100% indicates the most severe level of knock allowed ...";
CM_ SG_ 2364554238 EngCyl2PeakPress "Peak pressure in engine cylinder 2 in combustion cycle.";
CM_ SG_ 2364554238 EngCyl2HeatRelease "The amount of heat produced during combustion in engine cylinder 2.  The negative range is to cover thermodynamic behavior during misfire.";
CM_ BO_ 2364553982 "Used to communicate combustion information of Engine Cylinder 1. The PGN is transmitted at the end of every combustion in Cylinder 1.";
CM_ SG_ 2364553982 EngCyl1PressSensorPreliminaryFMI "Used to identify the applicable J1939-73 FMI detected in the engine cylinder 1 pressure sensor.  When there is no failure FMI 31 is sent. In the case of multiple failures the most severe is communicated.";
CM_ SG_ 2364553982 EngCyl1SynchronousKnockLevel "Used to indicate the level of knock for engine cylinder 1. The level of knock is reported using a relative scale where 0% is least level of knock, and increasing levels indicate more knock until 100% indicates the most severe level of knock allowed ...";
CM_ SG_ 2364553982 EngCyl1PeakPress "Peak pressure in engine cylinder 1 in combustion cycle.";
CM_ SG_ 2364553982 EngCyl1HeatRelease "The amount of heat produced during combustion in Engine cylinder 1. The negative range is to cover thermodynamic behavior during misfire.";
CM_ BO_ 2364553726 "Used to transmit parameters related to air systems.";
CM_ SG_ 2364553726 EngTotalIntakeMassAirFlowRate "Mass Flow rate of air entering the engine. This also includes the amount of exhaust gas recirculated, if any.";
CM_ SG_ 2364553726 EngDesiredAirFuelRatio "Reports the desired Air Fuel ratio for the engine.

Air Fuel Ratio specifies the amount of air required to completely burn one unit of fuel in the engine to meet the required engine performance and emission standards.";
CM_ BO_ 2364553470 "Used to transmit requested information for engine torque and fuel rate.";
CM_ SG_ 2364553470 EngCylTorque "Calculated engine torque output per cylinder.";
CM_ SG_ 2364553470 EngCylDieselMassFlowRateCmd "Commanded Mass Flow rate of diesel fuel delivered to the engine normalized per cylinder.";
CM_ SG_ 2364553470 EngCylGasMassFlowRateCmd "Commanded Mass Flow rate of gaseous fuel delivered to the engine normalized per cylinder.";
CM_ SG_ 2364553470 EngGasFuelPercentageCmd "Percentage of Gaseous fuel used, in terms of % mass of fuel. 0% means no Gaseous fuel used and 100 % means completely gaseous fuel is used.
Gas substitution is the process for a dual fuel engine system of substituting gas, e.g. natural gas, for ...";
CM_ SG_ 2364553470 EngDualFuelModeCmd "Request to enable dual fuel mode.

00 = De-activate dual fuel mode
01 = Activate dual fuel mode
10 = Reserved
11 = Not available";
CM_ BO_ 2364553214 "Used to transmit Engine Turbocharger Blowoff Actuator parameters";
CM_ SG_ 2364553214 EngTrbCmprssrBlwffActtr1OprtnStt "Used to identify the status of Engine Turbocharger Compressor Blowoff Actuator 1.
0000 - Normal
0001 - Alarm (fully operational but needs service)
0010 - Alarm High Severity (functional but transient performance may be reduced)
0011 - Derate ...";
CM_ SG_ 2364553214 EngTrbCmprssrBlowoffActuator1Pos "Actual position of the turbocharger compressor blowoff actuator, where 0% represents fully closed and 100% represents fully open.";
CM_ SG_ 2364553214 EngTrbCmprssrBlwffActtr1DsredPos "The requested position of the Engine Turbocharger Compressor Blowoff actuator by the engine ECU, where 0% represents bypass fully closed and 100% represents fully open.  This is the position that the device is attempting to achieve.";
CM_ SG_ 2364553214 EngTrbCmprssrBlwoffActuator1Temp "Temperature of the Engine Turbocharger Compressor Bypass Actuator 1 drive circuitry. Temperature excursions may affect the torque output.";
CM_ SG_ 2364553214 EngTrbCmprssrBlwffActtr1TmpSttus "Used to identify the status of the Engine Turbocharger Compresssor Blowoff Actuator 1 drive circuitry temperature. Temperature excursions may affect the torque output.
000 - High Most severe
001 - High Least severe
010 - In Range
011 - Low Least ...";
CM_ SG_ 2364553214 EngTrbCmprssrBlwffActtr1PrlmnryF "Used to identify the applicable J1939-73 FMI detected in the Engine Turbocharger Blowoff Actuator 1 by the manufacturer's software. When there is no failure FMI 31 is transmitted. When there are multiple failures, the most severe is transmitted.";
CM_ BO_ 2364547838 "Message that provides the current machine selected speed, direction, and source parameters.";
CM_ SG_ 2364547838 PersistentLimitStatus "Reports the tractor ECU's present limit status associated with a parameter whose commands are presistent  (i.e. hitch position).
000 - Not limited
001 - Operator limited/controlled (Request cannot be implemented)
010 - Limited high (only lower ...";
CM_ SG_ 2364547838 MachineSelectedSpeedSource "Indicates the speed source that is currently being reported in the machine speed parameter.
000 - Wheel-based speed
001 - Ground-based speed
010 - Navigation-based speed
011 - 'Blended' speed
100 - 'Simulated' speed
101 - 110 - Reserved
111 - ...";
CM_ SG_ 2364547838 MachineSelectedDirection "Indicates the current direction of travel of the machine.

00 - Reverse
01 - Forward
10 - Error indication
11 - Not available";
CM_ SG_ 2364547838 MachineSelectedDistance "Actual distance traveled by the machine based on the value of selected machine speed.  When distance exceeds 4211081.215 m, the value should be reset to zero and incremented as additional distance accrues.";
CM_ SG_ 2364547838 MachineSelectedSpeed "Reports the value of one of the currently available machine speeds (wheel, ground, or navigational-based) which the machine has determined to best represent the machine's speed.";
CM_ BO_ 2364547326 "Message to transmit data of the towed vehicle to the towing vehicle. See ISO 11992-2.";
CM_ BO_ 2364547070 "Message to transmit data of the towed vehicle to the towing vehicle. See ISO 11992-2.";
CM_ BO_ 2364546814 "Contains parameters that allow the generator control system to control the engine and to provide information about the generator control system";
CM_ SG_ 2364546814 GeneratorGoverningBias "Control signal used to govern the genset's speed or load (depending on isochronous or utility parallel operation, respectively)
NOTE:  If this method of engine control is used, the PGN 0 (TSC1) is not expected to be received by the engine ...";
CM_ BO_ 2364546046 "Message to transmit data of the towing vehicle to the towed vehicle. See ISO 11992-3.";
CM_ BO_ 2364538622 "This proprietary PG uses the Destination Specific PDU Format allowing manufacturers to direct their proprietary communications to a specific destination node.";
CM_ BO_ 2364014334 "Node-to-Virtual Terminal";
CM_ BO_ 2363948798 "Virtual Terminal-to-Node";
CM_ BO_ 2566767614 "Electronic Engine Controller 15";
CM_ SG_ 2566767614 AccelPedal2Channel3 "Sensor output 3 for the accelerator pedal #2 position when using a redundant-style sensor.  The ratio of actual accelerator pedal position to maximum pedal position. This is for the second occurrence of the accelerator pedal. Although it is used as ...";
CM_ SG_ 2566767614 AccelPedal2Channel2 "Sensor output 2 for the accelerator pedal #2 position when using a redundant-style sensor.  The ratio of actual accelerator pedal position to maximum pedal position. This is for the second occurrence of the accelerator pedal. Although it is used as ...";
CM_ SG_ 2566767614 AccelPedal1Channel3 "Sensor output 3 for the accelerator pedal #1 position when using a redundant-style sensor.  The ratio of actual accelerator pedal position to maximum pedal position. This is for the first occurrence of the accelerator pedal. Although it is used as ...";
CM_ SG_ 2566767614 AccelPedal1Channel2 "Sensor output 2 for the accelerator pedal #1 position when using a redundant-style sensor.  The ratio of actual accelerator pedal position to maximum pedal position. This is for the first occurrence of the accelerator pedal. Although it is used as ...";
CM_ BO_ 2559049470 "Engine State Requests";
CM_ SG_ 2559049470 DesiredEngFuelingState "Devices send this request to the engine controller to:
(a) Shut off engine fueling, but remain prepared to re-start quickly by not shutting down the control system, or
(b) Keep the engine running.
00 Fueling not desired (shut off engine fueling)
 ...";
CM_ SG_ 2559049470 RequestedFuelType "Engine controller receives this request from another control module to select the type of fuel to be used for engine operation.
0x00 - Not available - NONE
0x01 - Gasoline/petrol - GAS
0x02 - Methanol - METH
0x03 - Ethanol - ETH
0x04 - Diesel - ...";
CM_ SG_ 2559049470 EngGasFuelSupplyDesiredPress "Desired gage pressure of gaseous fuel supply to the engine.";
CM_ SG_ 2559049470 EngGasFuelUsageInhibited "Used to request that the engine should not be allowed to use gaseous fuel for engine cylinder combustion. This state is relevant for dual fuel systems and would be used when conditions are detected that make it unsafe or not appropriate to use ...";
CM_ BO_ 2349596414 "Advanced Emergency Braking System message 2.";
CM_ SG_ 2349596414 AEBS2MessageChecksum "Used to check the message checksum of the transmitting (HMI) unit within the AEBS2 system.
Checksum = (Byte1 + Byte2 + Byte3 + Byte4 + Byte5 + Byte6 + Byte7 + (message counter & 0x0F) + message ID low byte + message ID mid low byte + message ID mid ...";
CM_ SG_ 2349596414 AEBS2MessageCounter "The message counter is increased with every transmitted AEBS2 message.  After reaching a value of 0xF the next value will be 0.";
CM_ SG_ 2349596414 DrvrActvtnDmndFrAdvncdEmrgncyBrk "According to the Vienna world convention on road traffic the driver must be provided with means to deactivate an Advanced Emergency Braking System. This command is to be transmitted from the respective HMI unit to the AEBS unit.
00 - the driver ...";
CM_ BO_ 2362375934 "KWP2000 Mixed physical addressing";
CM_ BO_ 2362310398 "KWP2000 Mixed functional addressing";
CM_ BO_ 2362244862 "This message allows the system to adapt the bus bandwidth to the needs of the user of messages.";
CM_ SG_ 2362244862 DataDictionaryRow "This 4 bit parameter indicates the Row that is to be used within the specific Data Dictionary Table identified by the Implement Type. This is the Group (GRUP) in LBS documents.";
CM_ SG_ 2362244862 DataDictionaryColumn "This 4 bit parameter indicates the Column that is to be used within the specific Data Dictionary Table identified by the Implement Type. This is the Instance (INST) in LBS documents.";
CM_ SG_ 2362244862 ImplementType "This 4 bit parameter indicates which data dictionary page is to be used to locate the identity of the following data.";
CM_ SG_ 2362244862 ImplementPos "This 4 bit parameter of this message will indicate which Implement is referenced within a set of identical Implements.  The numbering is to start with 1 at the leftmost, foremost, bottom most implement.  The numbering will then increment from left ...";
CM_ SG_ 2362244862 DataFormat_ErrorCondition "This 2 bit parameter that indicates the format or availability of the data in the following Process Data Parameter.
00 Data format is Long Integer
01 Data format is Floating
10 Data format is unsigned Long Integer
11 Not Available or error
Data ...";
CM_ SG_ 2362244862 ProcessDataType "This 2 bit parameter indicates what the data in the following Process Data Parameters is to be used for. See Table A.2.
00 Data is Set Point
01 Data is Actual values
10 Message is Set Point request
11 Message is Actual value request
Data is Set ...";
CM_ SG_ 2362244862 ProcessDataModifier "This 3 bit parameter that indicates how the data in the following Process Data Parameters is to be used when combined with the Process Data Type parameter. See Table A.2.

NOTE: Process Data Type is included since MOD is a function of PD";
CM_ SG_ 2362244862 RepetitionRateParameter "This parameter defines the repetition rate of the specified PGN.";
CM_ BO_ 2362179326 "The Process Data message has been defined as a destination specific message implying that the sender must decide which implement should receive the message.Working Set).";
CM_ SG_ 2362179326 ProcessVariableValue "This 4 byte parameter contains the actual data  for the Process Data Message.";
CM_ SG_ 2362179326 DataDictionaryRow "This 4 bit parameter indicates the Row that is to be used within the specific Data Dictionary Table identified by the Implement Type. This is the Group (GRUP) in LBS documents.";
CM_ SG_ 2362179326 DataDictionaryColumn "This 4 bit parameter indicates the Column that is to be used within the specific Data Dictionary Table identified by the Implement Type. This is the Instance (INST) in LBS documents.";
CM_ SG_ 2362179326 ImplementType "This 4 bit parameter indicates which data dictionary page is to be used to locate the identity of the following data.";
CM_ SG_ 2362179326 ImplementPos "This 4 bit parameter of this message will indicate which Implement is referenced within a set of identical Implements.  The numbering is to start with 1 at the leftmost, foremost, bottom most implement.  The numbering will then increment from left ...";
CM_ SG_ 2362179326 CountNumber "This parameter indicates which member of the set of possible entities is being referenced. The means of generating this Count Number is explained in the following clause.";
CM_ SG_ 2362179326 DataFormat_ErrorCondition "This 2 bit parameter that indicates the format or availability of the data in the following Process Data Parameter.
00 Data format is Long Integer
01 Data format is Floating
10 Data format is unsigned Long Integer
11 Not Available or error
Data ...";
CM_ SG_ 2362179326 ProcessDataType "This 2 bit parameter indicates what the data in the following Process Data Parameters is to be used for. See Table A.2.
00 Data is Set Point
01 Data is Actual values
10 Message is Set Point request
11 Message is Actual value request
Data is Set ...";
CM_ SG_ 2362179326 ProcessDataModifier "This 3 bit parameter that indicates how the data in the following Process Data Parameters is to be used when combined with the Process Data Type parameter. See Table A.2.

NOTE: Process Data Type is included since MOD is a function of PD";
CM_ BO_ 2361982718 "Defined in ISO 11783-6  Annex L";
CM_ BO_ 2361917182 "Defined in ISO 11783-6  Annex L";
CM_ BO_ 2361851646 "This message provides the estimated flow of a general purpose valve.  Defined in ISO 11783-7.";
CM_ SG_ 2361851646 ValveFailSafeMode "Command for setting the fail safe mode of a general purpose valve.

00 Block
01 Float
10 Reserved
11 Don’t Care";
CM_ SG_ 2361851646 ValveState "The measured state of the general purpose valve.   With float enabled, hydraulic fluid may flow to or from the tractor as driven by the implement.
0000            Blocked
0001            Extend
0010            Retract
0011            Floating
 ...";
CM_ SG_ 2361851646 RetractPortEstFlow "The value reported by the controller of flow through the extend port of an auxiliary valve of a tractor";
CM_ SG_ 2361851646 ExtendPortEstFlow "The value reported by the controller of flow through the extend port of an auxiliary valve of a tractor";
CM_ BO_ 2361786110 "This message provides the measurement of a general purpose valve.  Defined in ISO11783-7.";
CM_ SG_ 2361786110 ReturnPortPress "The measured nominal pressure at the return port of an auxiliary valve of a tractor";
CM_ SG_ 2361786110 RetractPortPress "The measured nominal pressure at the retract port of an auxiliary valve of a tractor";
CM_ SG_ 2361786110 ExtendPortPress "The measured nominal pressure at the extend port of an auxiliary valve of a tractor";
CM_ SG_ 2361786110 RetractPortMeasuredFlow "The measured flow through the retract port of an auxiliary valve of a tractor";
CM_ SG_ 2361786110 ExtendPortMeasuredFlow "The measured flow through the extend port of an auxiliary valve of a tractor";
CM_ BO_ 2361720574 "This message provides control of the flow through a general purpose valve.  Defined in ISO 11783-7.";
CM_ SG_ 2361720574 PortFlowCmd "The command to set the flow through the extend or retract port of an auxiliary valve of a tractor";
CM_ BO_ 2361458430 "Proprietarily Configuration message for use in J1939-74.";
CM_ BO_ 2361392894 "Proprietarily Configuration message for use in J1939-74.";
CM_ BO_ 2361327358 "Proprietarily Configuration message for use in J1939-74.";
CM_ BO_ 2361261822 "Proprietarily Configuration message for use in J1939-74.";
CM_ BO_ 2361196286 "Proprietarily Configuration message for use in J1939-74.";
CM_ BO_ 2361130750 "Proprietarily Configuration message for use in J1939-74.";
CM_ BO_ 2361065214 "Proprietarily Configuration message for use in J1939-74.";
CM_ BO_ 2360999678 "Proprietarily Configuration message for use in J1939-74.";
CM_ BO_ 2360934142 "Proprietarily Configuration message for use in J1939-74.";
CM_ BO_ 2360868606 "Proprietarily Configuration message for use in J1939-74.";
CM_ BO_ 2360803070 "Proprietarily Configuration message for use in J1939-74.";
CM_ BO_ 2360737534 "Proprietarily Configuration message for use in J1939-74.";
CM_ BO_ 2360671998 "Proprietarily Configuration message for use in J1939-74.";
CM_ BO_ 2360606462 "Proprietarily Configuration message for use in J1939-74.";
CM_ BO_ 2360540926 "Proprietarily Configuration message for use in J1939-74.";
CM_ BO_ 2360475390 "Proprietarily Configuration message for use in J1939-74.";
CM_ BO_ 2360409854 "Message used to identify the data content (by SPN) of one of the configurable messages
(identified by PGN).";
CM_ BO_ 2360344318 "This message is designed to cause other CAs to respond with the identity of any message that they send in which the particular parameter (identified by specific SPN) is contained";
CM_ BO_ 2360213246 "Steering command expressed as desired curvature";
CM_ BO_ 2360147710 "Machine system feedback detailing status of machine relative to guidance operation";
CM_ BO_ 2360082174 "Used for obtaining status of the client, volume handling, file access, file handling and directory handling.  Description of messages is given in ISO 11783 Part 13.";
CM_ BO_ 2358968062 "Message to transmit data of the towing vehicle to the towed vehicle. See ISO 11992-3.";
CM_ BO_ 2358509310 "A message to change fields of the NAME of a CA";
CM_ BO_ 2358181630 "The PGN is for a sequence control system, such as a headland management system, which includes tractor and implement functions in one system.";
CM_ BO_ 2358116094 "This PGN is for sending response messages from control functions to a Sequence Control Master on the tractor and connected implement(s).";
CM_ BO_ 2358050558 "The CRO message is the one of two PGNs needed by the CAN Calibration Protocol. It is sent by a tool to send queries or commands to a target ECU.";
CM_ BO_ 2357985022 "The DTO message is the one of two PGNs needed by the CAN Calibration Protocol. It is sent by an ECU in response tool to tool queries or commands.";
CM_ BO_ 2558983934 "The switched power outputs command is sent to the Power Distribution Module (PDM) to change the state of the PDM's switched power outputs.

This command is sent to the PDM as needed to change the power outputs, but no faster than once every 100ms.";
CM_ SG_ 2558983934 SwitchedPowerOutput18Cmd "Desired state of Switched Power Output #18. Used to set the desired state.

00 - Output off
01 - Output on
10 - Reserved
11 - Take no action";
CM_ SG_ 2558983934 SwitchedPowerOutput19Cmd "Desired state of Switched Power Output #19. Used to set the desired state.

00 - Output off
01 - Output on
10 - Reserved
11 - Take no action";
CM_ SG_ 2558983934 SwitchedPowerOutput20Cmd "Desired state of Switched Power Output #20. Used to set the desired state.

00 - Output off
01 - Output on
10 - Reserved
11 - Take no action";
CM_ SG_ 2558983934 SwitchedPowerOutput13Cmd "Desired state of Switched Power Output #13. Used to set the desired state.

00 - Output off
01 - Output on
10 - Reserved
11 - Take no action";
CM_ SG_ 2558983934 SwitchedPowerOutput14Cmd "Desired state of Switched Power Output #14. Used to set the desired state.

00 - Output off
01 - Output on
10 - Reserved
11 - Take no action";
CM_ SG_ 2558983934 SwitchedPowerOutput15Cmd "Desired state of Switched Power Output #15. Used to set the desired state.

00 - Output off
01 - Output on
10 - Reserved
11 - Take no action";
CM_ SG_ 2558983934 SwitchedPowerOutput16Cmd "Desired state of Switched Power Output #16. Used to set the desired state.

00 - Output off
01 - Output on
10 - Reserved
11 - Take no action";
CM_ SG_ 2558983934 SwitchedPowerOutput9Cmd "Desired state of Switched Power Output #9. Used to set the desired state.

00 - Output off
01 - Output on
10 - Reserved
11 - Take no action";
CM_ SG_ 2558983934 SwitchedPowerOutput10Cmd "Desired state of Switched Power Output #10. Used to set the desired state.

00 - Output off
01 - Output on
10 - Reserved
11 - Take no action";
CM_ SG_ 2558983934 SwitchedPowerOutput29Cmd "Desired state of Switched Power Output #29. Used to set the desired state.

00 - Output off
01 - Output on
10 - Reserved
11 - Take no action";
CM_ SG_ 2558983934 SwitchedPowerOutput30Cmd "Desired state of Switched Power Output #30. Used to set the desired state.

00 - Output off
01 - Output on
10 - Reserved
11 - Take no action";
CM_ SG_ 2558983934 SwitchedPowerOutput31Cmd "Desired state of Switched Power Output #31. Used to set the desired state.

00 - Output off
01 - Output on
10 - Reserved
11 - Take no action";
CM_ SG_ 2558983934 SwitchedPowerOutput32Cmd "Desired state of Switched Power Output #32. Used to set the desired state.

00 - Output off
01 - Output on
10 - Reserved
11 - Take no action";
CM_ SG_ 2558983934 SwitchedPowerOutput25Cmd "Desired state of Switched Power Output #25. Used to set the desired state.

00 - Output off
01 - Output on
10 - Reserved
11 - Take no action";
CM_ SG_ 2558983934 SwitchedPowerOutput26Cmd "Desired state of Switched Power Output #26. Used to set the desired state.

00 - Output off
01 - Output on
10 - Reserved
11 - Take no action";
CM_ SG_ 2558983934 SwitchedPowerOutput27Cmd "Desired state of Switched Power Output #27. Used to set the desired state.

00 - Output off
01 - Output on
10 - Reserved
11 - Take no action";
CM_ SG_ 2558983934 SwitchedPowerOutput28Cmd "Desired state of Switched Power Output #28. Used to set the desired state.

00 - Output off
01 - Output on
10 - Reserved
11 - Take no action";
CM_ SG_ 2558983934 SwitchedPowerOutput21Cmd "Desired state of Switched Power Output #21. Used to set the desired state.

00 - Output off
01 - Output on
10 - Reserved
11 - Take no action";
CM_ SG_ 2558983934 SwitchedPowerOutput22Cmd "Desired state of Switched Power Output #22. Used to set the desired state.

00 - Output off
01 - Output on
10 - Reserved
11 - Take no action";
CM_ SG_ 2558983934 SwitchedPowerOutput23Cmd "Desired state of Switched Power Output #23. Used to set the desired state.

00 - Output off
01 - Output on
10 - Reserved
11 - Take no action";
CM_ SG_ 2558983934 SwitchedPowerOutput24Cmd "Desired state of Switched Power Output #24. Used to set the desired state.

00 - Output off
01 - Output on
10 - Reserved
11 - Take no action";
CM_ SG_ 2558983934 SwitchedPowerOutput17Cmd "Desired state of Switched Power Output #17. Used to set the desired state.

00 - Output off
01 - Output on
10 - Reserved
11 - Take no action";
CM_ SG_ 2558983934 SwitchedPowerOutput11Cmd "Desired state of Switched Power Output #11. Used to set the desired state.

00 - Output off
01 - Output on
10 - Reserved
11 - Take no action";
CM_ SG_ 2558983934 SwitchedPowerOutput12Cmd "Desired state of Switched Power Output #12. Used to set the desired state.

00 - Output off
01 - Output on
10 - Reserved
11 - Take no action";
CM_ SG_ 2558983934 SwitchedPowerOutput5Cmd "Desired state of Switched Power Output #5. Used to set the desired state.

00 - Output off
01 - Output on
10 - Reserved
11 - Take no action";
CM_ SG_ 2558983934 SwitchedPowerOutput6Cmd "Desired state of Switched Power Output #6. Used to set the desired state.

00 - Output off
01 - Output on
10 - Reserved
11 - Take no action";
CM_ SG_ 2558983934 SwitchedPowerOutput7Cmd "Desired state of Switched Power Output #7. Used to set the desired state.

00 - Output off
01 - Output on
10 - Reserved
11 - Take no action";
CM_ SG_ 2558983934 SwitchedPowerOutput8Cmd "Desired state of Switched Power Output #8. Used to set the desired state.

00 - Output off
01 - Output on
10 - Reserved
11 - Take no action";
CM_ SG_ 2558983934 SwitchedPowerOutput1Cmd "Desired state of Switched Power Output #1. Used to set the desired state.

00 - Output off
01 - Output on
10 - Reserved
11 - Take no action";
CM_ SG_ 2558983934 SwitchedPowerOutput2Cmd "Desired state of Switched Power Output #2. Used to set the desired state.

00 - Output off
01 - Output on
10 - Reserved
11 - Take no action";
CM_ SG_ 2558983934 SwitchedPowerOutput3Cmd "Desired state of Switched Power Output #3. Used to set the desired state.

00 - Output off
01 - Output on
10 - Reserved
11 - Take no action";
CM_ SG_ 2558983934 SwitchedPowerOutput4Cmd "Desired state of Switched Power Output #4. Used to set the desired state.

00 - Output off
01 - Output on
10 - Reserved
11 - Take no action";
CM_ BO_ 2349727486 "Used to communicate transmission control information";
CM_ SG_ 2349727486 TransMode10 "Indicates whether transmission mode 10 is enabled. Modes are manufacturer specific and are not necessarily mutually exclusive. See also SPN 6568. 

00 Disable
01 Enable
10 Reserved
11 Take no action";
CM_ SG_ 2349727486 TransMode9 "Indicates whether transmission mode 9 is enabled. Modes are manufacturer specific and are not necessarily mutually exclusive. See also SPN 6567. 

00 Disable
01 Enable
10 Reserved
11 Take no action";
CM_ BO_ 2550988542 "Electronic Engine Controller 16";
CM_ SG_ 2550988542 AccelPedalPos3 "The ratio of actual position of the third analog engine speed/torque request input device (such as an accelerator pedal or throttle lever) to the maximum position of the input device.  This parameter is intended for the third accelerator control in ...";
CM_ BO_ 2349268734 "Message to transmit data of the towed vehicle to the towing vehicle. See ISO 11992-3.";
CM_ BO_ 2349203198 "Message to transmit data of the towing vehicle to the towed vehicle. See ISO 11992-3.";
CM_ BO_ 2566767358 "Electronic Engine Controller 14";
CM_ SG_ 2566767358 EngFuelIsolationCtrl "Control setting for fuel isolation. In a single injector dual fuel system when using just diesel fuel, diesel must not be allowed to migrate into the gaseous fuel system. When the fuel isolation valve is closed the engine uses dual fuel by allowing ...";
CM_ SG_ 2566767358 FuelType "Type of fuel currently being utilized by the vehicle
Data Byte - Scaling - External Display
0x00 - Not available - NONE
0x01 - Gasoline/petrol - GAS
0x02 - Methanol - METH
0x03 - Ethanol - ETH
0x04 - Diesel - DSL
0x05 - Liquefied Petroleum ...";
CM_ SG_ 2566767358 EngFuelMassFlowRate "Mass of liquid fuel consumed by engine per unit of time.";
CM_ SG_ 2566767358 EngExhstGsRcrcltn1Valve2PosError "The position error of the Exhaust Gas Recirculation 1 valve 2, determined as the actual position (SPN 3821) minus the commanded position (SPN 3822).";
CM_ SG_ 2566767358 EngExhstGsRcrcltn1Valve1PosError "The position error of the Exhaust Gas Recirculation 1 valve, determined as the actual position (SPN 27) minus the commanded position (SPN 2791).";
CM_ BO_ 2566706686 "Contains information on Diesel Exhaust Fluid Pumps";
CM_ SG_ 2566706686 AT1DslExhustFluidPump2MotorSpeed "Rotational speed of the motor driving the second pump for the diesel exhaust fluid used in aftertreatment system 1 (exhaust bank 1).";
CM_ SG_ 2566706686 AT1DieselExhaustFluidPumpHeater "Percentage of heating applied to the aftertreatment 1 diesel exhaust fluid pump heater. A value of 0% means no heating applied, a value of 100% means full heating applied. The diesel exhaust fluid pump heater warms the diesel exhaust fluid in the ...";
CM_ BO_ 2566705406 "Engine Particulate Sensor Information";
CM_ SG_ 2566705406 AT1ParticulateSensorCurrent "Raw aftertreatment 1 PM sensor electical current reading.";
CM_ SG_ 2566705406 AT2ParticulateSensor "The particulate sensor measures the mass concentration of particulate matter in the exhaust downstream of the DPF in exhaust bank 2.";
CM_ SG_ 2566705406 AT1ParticulateSensor "The particulate sensor measures the mass concentration of particulate matter in the exhaust downstream of the DPF in exhaust bank 1.";
CM_ BO_ 2566705150 "Request to initiate the self-diagnosis of the NOx sensors implemented in the system.
This request may be sent at any time, but should not be sent if the status parameter indicates the self-diagnosis is not possible (state = 100 in SPNs 5713, 5714, ...";
CM_ SG_ 2566705150 AT2IntkNOxSnsrSlfdagnosisTrigger "Signal to trigger the self-diagnosis of NOx sensor ATI2 (Aftertreatment Intake Bank 2)
0000 Diagnostic mode disabled
0001 NOx Sensor ATI2 Self Diagnosis Request at Lambda=1.0
0010 NOx Sensor ATI2 Self Diagnosis Request at partial load
0011 NOx ...";
CM_ SG_ 2566705150 AT2OtltNOxSnsrSlfdagnosisTrigger "Signal to trigger the self-diagnosis of NOx sensor ATO2 (Aftertreatment Outlet Bank 2)
0000 Diagnostic mode disabled
0001 NOx Sensor ATO2 Self Diagnosis Request at Lambda=1.0
0010 NOx Sensor ATO2 Self Diagnosis Request at partial load
0011 NOx ...";
CM_ SG_ 2566705150 AT1IntkNOxSnsrSlfdagnosisTrigger "Signal to trigger the self-diagnosis of NOx sensor ATI1 (Aftertreatment Intake Bank 1)
0000 Diagnostic mode disabled
0001 NOx Sensor ATI1 Self Diagnosis Request at Lambda=1.0
0010 NOx Sensor ATI1 Self Diagnosis Request at partial load
0011 NOx ...";
CM_ SG_ 2566705150 AT1OtltNOxSnsrSlfdagnosisTrigger "Signal to trigger the self-diagnosis of NOx sensor ATO1 (Aftertreatment Outlet Bank 1)
0000 Diagnostic mode disabled
0001 NOx Sensor ATO1 Self Diagnosis Request at Lambda=1.0
0010 NOx Sensor ATO1 Self Diagnosis Request at partial load
0011 NOx ...";
CM_ BO_ 2566704382 "Engine Related Parameters";
CM_ SG_ 2566704382 AT2OutletGasSensorPowerSupply "State signal which indicates when the Aftertreatment 2 Outlet Gas Sensor driver output is being driven.  On means the ECU is powering the Aftertreatment 2 Intake Gas Sensor.  Note that the ECU is external to the sensor.
00 – Off
01 – On: The ECU ...";
CM_ SG_ 2566704382 AT2IntakeGasSensorPowerSupply "State signal which indicates when the Aftertreatment 2 Intake Gas Sensor driver output is being driven.  On means the ECU is powering the Aftertreatment 2 Intake Gas Sensor.  Note that the ECU is external to the sensor.
00 – Off
01 – On: The ECU ...";
CM_ SG_ 2566704382 AT1OutletGasSensorPowerSupply "State signal which indicates when the Aftertreatment 1 Outlet Gas Sensor driver output is being driven.  On means the ECU is powering the Aftertreatment 1 Intake Gas Sensor.  Note that the ECU is external to the sensor.
00 – Off
01 – On: The ECU ...";
CM_ SG_ 2566704382 AT1IntakeGasSensorPowerSupply "State signal which indicates when the Aftertreatment 1 Intake Gas Sensor driver output is being driven.  On means the ECU is powering the Aftertreatment 1 Intake Gas Sensor.  Note that the ECU is external to the sensor.
00 – Off
01 – On: The ECU ...";
CM_ BO_ 2566704126 "Engine Exhaust Gas Recirculation 1 Actuator related parameters";
CM_ SG_ 2566704126 EngExhstGsRcrcltn1Acttr2PrlmnryF "Used to identify the applicable J1939-73 FMI detected in the Engine Exhaust Gas Recirculation 1 Actuator 2 by the manufacturer’s software. When there is no failure FMI 31 is transmitted. When there are multiple failures, the most severe is ...";
CM_ SG_ 2566704126 EngExhstGsRcrcltn1Acttr2OprtnStt "Used to identify the status of Exhaust Gas Recirculation 1 Actuator 2
0000 – Normal
0001 – Alarm (fully operational but needs service)
0010 – Alarm High Severity (functional but transient performance may be reduced)
0011 – Derate Active (torque ...";
CM_ SG_ 2566704126 EngExhstGsRcrcltn1Acttr1OprtnStt "Used to identify the status of Exhaust Gas Recirculation 1 Actuator 1
0000 – Normal
0001 – Alarm (fully operational but needs service)
0010 – Alarm High Severity (functional but transient performance may be reduced)
0011 – Derate Active (torque ...";
CM_ SG_ 2566704126 EngExhstGsRcrcltn1Acttr2DsredPos "The requested position of the Engine Exhaust Gas Recirculation 1 Actuator 2 by the engine ECU, where 0% represents fully closed and 100% represents fully open.

This is the position that the device is attempting to achieve.";
CM_ SG_ 2566704126 EngExhstGsRcrclton1Actuator2Temp "Temperature of the Engine Exhaust Gas Recirculation 1 Actuator 2 drive circuitry.  Temperature excursions may affect the torque output.";
CM_ SG_ 2566704126 EngExhstGsRcrcltn1Acttr2TmpSttus "Used to identify the status of the Engine Exhaust Gas Recirculation 1 Actuator 2 drive circuitry temperature.  Temperature excursions may affect the torque output.
000 – High Most severe
001 – High Least severe
010 – In Range
011 – Low Least ...";
CM_ SG_ 2566704126 EngExhstGsRcrcltn1Acttr1DsredPos "The requested position of the Engine Exhaust Gas Recirculation 1 Actuator 1 by the engine ECU, where 0% represents fully closed and 100% represents fully open.

This is the position that the device is attempting to achieve.";
CM_ SG_ 2566704126 EngExhstGsRcrclton1Actuator1Temp "Temperature of the Engine Exhaust Gas Recirculation 1 Actuator 1 drive circuitry.  Temperature excursions may affect the torque output.";
CM_ SG_ 2566704126 EngExhstGsRcrcltn1Acttr1TmpSttus "Used to identify the status of the Engine Exhaust Gas Recirculation 1 Actuator 1 drive circuitry temperature.  Temperature excursions may affect the torque output.
000 – High Most severe
001 – High Least severe
010 – In Range
011 – Low Least ...";
CM_ SG_ 2566704126 EngExhstGsRcrcltn1Acttr1PrlmnryF "Used to identify the applicable J1939-73 FMI detected in the Engine Exhaust Gas Recirculation 1 Actuator 1 by the manufacturer’s software. When there is no failure FMI 31 is transmitted. When there are multiple failures, the most severe is ...";
CM_ BO_ 2566703870 "Engine Exhaust Gas Recirculation 2 Actuator related parameters";
CM_ SG_ 2566703870 EngExhstGsRcrcltn2Acttr2OprtnStt "Used to identify the status of Exhaust Gas Recirculation 2 Actuator 2
0000 – Normal
0001 – Alarm (fully operational but needs service)
0010 – Alarm High Severity (functional but transient performance may be reduced)
0011 – Derate Active (torque ...";
CM_ SG_ 2566703870 EngExhstGsRcrcltn2Acttr1OprtnStt "Used to identify the status of Exhaust Gas Recirculation 2 Actuator 1
0000 – Normal
0001 – Alarm (fully operational but needs service)
0010 – Alarm High Severity (functional but transient performance may be reduced)
0011 – Derate Active (torque ...";
CM_ SG_ 2566703870 EngExhstGsRcrcltn2Acttr2DsredPos "The requested position of the Engine Exhaust Gas Recirculation 2 Actuator 2 by the engine ECU, where 0% represents fully closed and 100% represents fully open.

This is the position that the device is attempting to achieve.";
CM_ SG_ 2566703870 EngExhstGsRcrclton2Actuator2Temp "Temperature of the Engine Exhaust Gas Recirculation 2 Actuator 2 drive circuitry.  Temperature excursions may affect the torque output.";
CM_ SG_ 2566703870 EngExhstGsRcrcltn2Acttr2TmpSttus "Used to identify the status of the Engine Exhaust Gas Recirculation 2 Actuator 2 drive circuitry temperature.  Temperature excursions may affect the torque output.
000 – High Most severe
001 – High Least severe
010 – In Range
011 – Low Least ...";
CM_ SG_ 2566703870 EngExhstGsRcrcltn2Acttr2PrlmnryF "Used to identify the applicable J1939-73 FMI detected in the Engine Exhaust Gas Recirculation 2 Actuator 2 by the manufacturer’s software. When there is no failure FMI 31 is transmitted. When there are multiple failures, the most severe is ...";
CM_ SG_ 2566703870 EngExhstGsRcrcltn2Acttr1DsredPos "The requested position of the Engine Exhaust Gas Recirculation 2 Actuator 1 by the engine ECU, where 0% represents fully closed and 100% represents fully open.

This is the position that the device is attempting to achieve.";
CM_ SG_ 2566703870 EngExhstGsRcrclton2Actuator1Temp "Temperature of the Engine Exhaust Gas Recirculation 2 Actuator 1 drive circuitry.  Temperature excursions may affect the torque output.";
CM_ SG_ 2566703870 EngExhstGsRcrcltn2Acttr1TmpSttus "Used to identify the status of the Engine Exhaust Gas Recirculation 2 Actuator 1 drive circuitry temperature.  Temperature excursions may affect the torque output.
000 – High Most severe
001 – High Least severe
010 – In Range
011 – Low Least ...";
CM_ SG_ 2566703870 EngExhstGsRcrcltn2Acttr1PrlmnryF "Used to identify the applicable J1939-73 FMI detected in the Engine Exhaust Gas Recirculation 2 Actuator 1 by the manufacturer’s software. When there is no failure FMI 31 is transmitted. When there are multiple failures, the most severe is ...";
CM_ BO_ 2566703614 "This PGN will be used to transmit the Feedback information from the Engine Throttle and Fuel Actuator.";
CM_ SG_ 2566703614 EngFuelRackFuelSupplyTemp "Temperature of fuel in the engine fuel rack.";
CM_ SG_ 2566703614 EngTurboWastegateActuator2Temp "Temperature of the Engine Turbocharger Wastegate Actuator 2 drive circuitry.  Temperature excursions may affect the torque output.";
CM_ SG_ 2566703614 EngFuelValve2Temp "Temperature of the Engine Fuel Valve 2 drive circuitry. Temperature excursions may affect the torque output.";
CM_ SG_ 2566703614 EngFuelValve1Temp "Temperature of the Engine Fuel Valve 1 drive circuitry. Temperature excursions may affect the torque output.";
CM_ SG_ 2566703614 EngThrottleValve2Temp "Temperature of the engine throttle valve 2 drive circuitry (SPN 3673).  Temperature excursions may affect the torque output.";
CM_ SG_ 2566703614 EngThrottleValve1Temp "Temperature of the engine throttle valve 1 drive circuitry (SPN 51).  Temperature excursions may affect the torque output.";
CM_ BO_ 2566703358 "Electronic Engine Controller 13";
CM_ SG_ 2566703358 EngFuelingDesiredRqCount "A signal issued by the engine control system indicating the number of devices from which the engine control system has received a “fueling desired” request. Requests included in this count are either from an external device via SPN 5793 Desired ...";
CM_ SG_ 2566703358 EngFuelingInhibitRqCount "A signal issued by the engine control system indicating the number of devices from which the engine control system has received a “fueling not desired” request. Requests included in this count are either from an external device via SPN 5793 Desired ...";
CM_ SG_ 2566703358 EngGasSubstitutionFuelPercentage "Percentage of Gaseous fuel used. 0% means no Gaseous fuel used and 100% means completely gaseous fuel is used.
Gas substitution is the process for a dual fuel engine system of substituting gas, e.g. natural gas, for some fraction of the primary ...";
CM_ SG_ 2566703358 EngDualFuelMode "Actual dual fuel mode, off or on.

00 = Actual dual fuel mode off
01 = Actual dual fuel mode on
10 = Reserved
11 = Not available";
CM_ SG_ 2566703358 SrcAddrssOfCntrllngDvcFrFlngStte "The J1939 source address of the device currently controlling the fueling state via SPN 5793.
254 (0xFE) is used to indicate that the Source Address of Controlling Device for Fueling State parameter is supported, but no device is currently ...";
CM_ SG_ 2566703358 EngFuelingInhibitPreventedReason "If Engine Fueling Inhibit Allowed (SPN 5795) indicates that the engine will not inhibit fueling, then this parameter will indicate the reason.
If more than one reason exists at the same time, then it is up to the manufacturer to decide which one to ...";
CM_ SG_ 2566703358 EngFuelingInhibitAllowed "This parameter is broadcast by the engine control system, and indicates to other devices on the network whether or not it will respond to requests to inhibit engine fueling via SPN 5793 Desired Engine Fueling State. With this information, devices ...";
CM_ SG_ 2566703358 FeedbackEngFuelingState "This parameter provides feedback to the network that SPN 5793 Desired Engine Fueling State was honored. SPN 5795 Engine Fueling Inhibit Allowed indicates the engine’s current ability to honor requests via SPN 5793 Desired Engine Fueling State.
00 = ...";
CM_ BO_ 2566702590 "This message contains SCR catalyst gas temperature information for aftertreatment system 1 (or bank 1).";
CM_ SG_ 2566702590 AT1SCRIntrmdteTempPreliminaryFMI "Used to identify the applicable J1939-73 FMI detected in the aftertreatment SCR intermediate temperature sensor by the manufacturer’s sensor control software in exhaust bank 1. When there is no failure FMI 31 is sent. In the case of multiple ...";
CM_ SG_ 2566702590 AT1SCRIntermediateTemp "Temperature of engine combustion byproducts at an intermediate point in the SCR component in exhaust bank 1.";
CM_ BO_ 2566702334 "This message contains SCR catalyst gas temperature information for aftertreatment system 2 (or bank 2).";
CM_ SG_ 2566702334 AT2SCRIntrmdteTempPreliminaryFMI "Used to identify the applicable J1939-73 FMI detected in the aftertreatment SCR intermediate temperature sensor by the manufacturer’s sensor control software in exhaust bank 2. When there is no failure FMI 31 is sent. In the case of multiple ...";
CM_ SG_ 2566702334 AT2SCRIntermediateTemp "Temperature of engine combustion byproducts at an intermediate point in the SCR component in exhaust bank 2.";
CM_ BO_ 2566702078 "Gaseous fuel information 4";
CM_ SG_ 2566702078 SupplyGasMethanePercentage "The percentage of methane in the gas supplied to the engine.";
BA_DEF_ SG_  "SigType" ENUM  "Default","Range","RangeSigned","ASCII","Discrete","Control","ReferencePGN","DTC","StringDelimiter","StringLength","StringLengthControl","MessageCounter","MessageChecksum";
BA_DEF_ SG_  "GenSigStartValue" INT 0 10000;
BA_DEF_ SG_  "GenSigSendType" ENUM  "Cyclic","OnWrite","OnWriteWithRepetition","OnChange","OnChangeWithRepetition","IfActive","IfActiveWithRepetition","NoSigSendType";
BA_DEF_ SG_  "GenSigILSupport" ENUM  "No","Yes";
BA_DEF_ SG_  "GenSigEVName" STRING ;
BA_DEF_ SG_  "SPN" INT 0 524287;
BA_DEF_ BO_  "TpJ1939VarDlc" ENUM  "No","Yes";
BA_DEF_ BO_  "GenMsgStartDelayTime" INT 0 100000;
BA_DEF_ BO_  "GenMsgILSupport" ENUM  "No","Yes";
BA_DEF_ BO_  "GenMsgDelayTime" INT 0 1000;
BA_DEF_ BO_  "GenMsgRequestable" INT 0 1;
BA_DEF_ BO_  "GenMsgSendType" ENUM  "cyclic","NotUsed","NotUsed","NotUsed","NotUsed","NotUsed","NotUsed","IfActive","noMsgSendType";
BA_DEF_ BO_  "VFrameFormat" ENUM  "StandardCAN","ExtendedCAN","reserved","J1939PG";
BA_DEF_ BO_  "GenMsgCycleTime" INT 0 3600000;
BA_DEF_ SG_  "SystemSignalLongSymbol" STRING ;
BA_DEF_DEF_  "SigType" "Default";
BA_DEF_DEF_  "GenSigStartValue" 0;
BA_DEF_DEF_  "GenSigSendType" "NoSigSendType";
BA_DEF_DEF_  "GenSigILSupport" "Yes";
BA_DEF_DEF_  "GenSigEVName" "Env@Nodename_@Signame";
BA_DEF_DEF_  "SPN" 0;
BA_DEF_DEF_  "TpJ1939VarDlc" "No";
BA_DEF_DEF_  "GenMsgStartDelayTime" 0;
BA_DEF_DEF_  "GenMsgILSupport" "Yes";
BA_DEF_DEF_  "GenMsgDelayTime" 0;
BA_DEF_DEF_  "GenMsgRequestable" 1;
BA_DEF_DEF_  "GenMsgSendType" "noMsgSendType";
BA_DEF_DEF_  "VFrameFormat" "J1939PG";
BA_DEF_DEF_  "GenMsgCycleTime" 0;
BA_DEF_DEF_  "SystemSignalLongSymbol" "";
BA_ "GenMsgCycleTime" BO_ 2297455358 10;
BA_ "GenMsgSendType" BO_ 2297455358 0;
BA_ "GenMsgCycleTime" BO_ 2365428734 100;
BA_ "GenMsgSendType" BO_ 2365428734 0;
BA_ "TpJ1939VarDlc" BO_ 2566703102 1;
BA_ "GenMsgCycleTime" BO_ 2349465342 100;
BA_ "GenMsgSendType" BO_ 2349465342 0;
BA_ "GenMsgCycleTime" BO_ 2364553726 20;
BA_ "GenMsgSendType" BO_ 2364553726 0;
BA_ "GenMsgCycleTime" BO_ 2364553470 20;
BA_ "GenMsgSendType" BO_ 2364553470 0;
BA_ "GenMsgCycleTime" BO_ 2364553214 100;
BA_ "GenMsgSendType" BO_ 2364553214 0;
BA_ "GenMsgCycleTime" BO_ 2364546814 20;
BA_ "GenMsgSendType" BO_ 2364546814 0;
BA_ "TpJ1939VarDlc" BO_ 2364538622 1;
BA_ "GenMsgCycleTime" BO_ 2559049470 1000;
BA_ "GenMsgSendType" BO_ 2559049470 0;
BA_ "GenMsgDelayTime" BO_ 2559049470 100;
BA_ "GenMsgCycleTime" BO_ 2349596414 50;
BA_ "GenMsgSendType" BO_ 2349596414 0;
BA_ "GenMsgDelayTime" BO_ 2349596414 10;
BA_ "GenMsgRequestable" BO_ 2362375934 0;
BA_ "GenMsgRequestable" BO_ 2362310398 0;
BA_ "GenMsgRequestable" BO_ 2361982718 0;
BA_ "GenMsgRequestable" BO_ 2361917182 0;
BA_ "GenMsgCycleTime" BO_ 2558983934 100;
BA_ "GenMsgSendType" BO_ 2558983934 0;
BA_ "GenMsgDelayTime" BO_ 2558983934 100;
BA_ "GenMsgCycleTime" BO_ 2349727486 50;
BA_ "GenMsgSendType" BO_ 2349727486 0;
BA_ "GenMsgCycleTime" BO_ 2550988542 50;
BA_ "GenMsgSendType" BO_ 2550988542 0;
BA_ "GenMsgCycleTime" BO_ 2566706686 500;
BA_ "GenMsgSendType" BO_ 2566706686 0;
BA_ "GenMsgCycleTime" BO_ 2566704126 100;
BA_ "GenMsgSendType" BO_ 2566704126 0;
BA_ "GenMsgCycleTime" BO_ 2566703870 100;
BA_ "GenMsgSendType" BO_ 2566703870 0;
BA_ "GenMsgCycleTime" BO_ 2566703614 100;
BA_ "GenMsgSendType" BO_ 2566703614 0;
BA_ "GenMsgCycleTime" BO_ 2566703358 1000;
BA_ "GenMsgSendType" BO_ 2566703358 0;
BA_ "GenMsgDelayTime" BO_ 2566703358 100;
BA_ "GenMsgCycleTime" BO_ 2566702590 500;
BA_ "GenMsgSendType" BO_ 2566702590 0;
BA_ "GenMsgCycleTime" BO_ 2566702334 500;
BA_ "GenMsgSendType" BO_ 2566702334 0;
BA_ "GenMsgCycleTime" BO_ 2566702078 200;
BA_ "GenMsgSendType" BO_ 2566702078 0;
BA_ "SPN" SG_ 2364566014 EngGsFlValve4StartOfActuationCmd 6681;
BA_ "SigType" SG_ 2364566014 EngGsFlValve4StartOfActuationCmd 1;
BA_ "SPN" SG_ 2364566014 EngGsFlValve3StartOfActuationCmd 6680;
BA_ "SigType" SG_ 2364566014 EngGsFlValve3StartOfActuationCmd 1;
BA_ "SPN" SG_ 2364566014 EngGsFlValve2StartOfActuationCmd 6679;
BA_ "SigType" SG_ 2364566014 EngGsFlValve2StartOfActuationCmd 1;
BA_ "SPN" SG_ 2364566014 EngGsFlValve1StartOfActuationCmd 6678;
BA_ "SigType" SG_ 2364566014 EngGsFlValve1StartOfActuationCmd 1;
BA_ "SPN" SG_ 2364565758 EngGasFuelValve20DurationCmd 6677;
BA_ "SigType" SG_ 2364565758 EngGasFuelValve20DurationCmd 1;
BA_ "SPN" SG_ 2364565758 EngGasFuelValve19DurationCmd 6676;
BA_ "SigType" SG_ 2364565758 EngGasFuelValve19DurationCmd 1;
BA_ "SPN" SG_ 2364565758 EngGasFuelValve18DurationCmd 6675;
BA_ "SigType" SG_ 2364565758 EngGasFuelValve18DurationCmd 1;
BA_ "SPN" SG_ 2364565758 EngGasFuelValve17DurationCmd 6674;
BA_ "SigType" SG_ 2364565758 EngGasFuelValve17DurationCmd 1;
BA_ "SPN" SG_ 2364565502 EngGasFuelValve16DurationCmd 6673;
BA_ "SigType" SG_ 2364565502 EngGasFuelValve16DurationCmd 1;
BA_ "SPN" SG_ 2364565502 EngGasFuelValve15DurationCmd 6672;
BA_ "SigType" SG_ 2364565502 EngGasFuelValve15DurationCmd 1;
BA_ "SPN" SG_ 2364565502 EngGasFuelValve14DurationCmd 6671;
BA_ "SigType" SG_ 2364565502 EngGasFuelValve14DurationCmd 1;
BA_ "SPN" SG_ 2364565502 EngGasFuelValve13DurationCmd 6670;
BA_ "SigType" SG_ 2364565502 EngGasFuelValve13DurationCmd 1;
BA_ "SPN" SG_ 2364565246 EngGasFuelValve12DurationCmd 6669;
BA_ "SigType" SG_ 2364565246 EngGasFuelValve12DurationCmd 1;
BA_ "SPN" SG_ 2364565246 EngGasFuelValve11DurationCmd 6668;
BA_ "SigType" SG_ 2364565246 EngGasFuelValve11DurationCmd 1;
BA_ "SPN" SG_ 2364565246 EngGasFuelValve10DurationCmd 6667;
BA_ "SigType" SG_ 2364565246 EngGasFuelValve10DurationCmd 1;
BA_ "SPN" SG_ 2364565246 EngGasFuelValve9DurationCmd 6666;
BA_ "SigType" SG_ 2364565246 EngGasFuelValve9DurationCmd 1;
BA_ "SPN" SG_ 2364564990 EngGasFuelValve8DurationCmd 6665;
BA_ "SigType" SG_ 2364564990 EngGasFuelValve8DurationCmd 1;
BA_ "SPN" SG_ 2364564990 EngGasFuelValve7DurationCmd 6664;
BA_ "SigType" SG_ 2364564990 EngGasFuelValve7DurationCmd 1;
BA_ "SPN" SG_ 2364564990 EngGasFuelValve6DurationCmd 6663;
BA_ "SigType" SG_ 2364564990 EngGasFuelValve6DurationCmd 1;
BA_ "SPN" SG_ 2364564990 EngGasFuelValve5DurationCmd 6662;
BA_ "SigType" SG_ 2364564990 EngGasFuelValve5DurationCmd 1;
BA_ "SPN" SG_ 2364564734 EngGasFuelValve4DurationCmd 6661;
BA_ "SigType" SG_ 2364564734 EngGasFuelValve4DurationCmd 1;
BA_ "SPN" SG_ 2364564734 EngGasFuelValve3DurationCmd 6660;
BA_ "SigType" SG_ 2364564734 EngGasFuelValve3DurationCmd 1;
BA_ "SPN" SG_ 2364564734 EngGasFuelValve2DurationCmd 6659;
BA_ "SigType" SG_ 2364564734 EngGasFuelValve2DurationCmd 1;
BA_ "SPN" SG_ 2364564734 EngGasFuelValve1DurationCmd 6658;
BA_ "SigType" SG_ 2364564734 EngGasFuelValve1DurationCmd 1;
BA_ "SPN" SG_ 2364564478 EngGsFlVlvNmnlStrtOfActuationCmd 6657;
BA_ "SigType" SG_ 2364564478 EngGsFlVlvNmnlStrtOfActuationCmd 1;
BA_ "SPN" SG_ 2364564478 EngGsFuelValveNominalDurationCmd 6656;
BA_ "SigType" SG_ 2364564478 EngGsFuelValveNominalDurationCmd 1;
BA_ "SPN" SG_ 2297455358 TransDirectionalOutputShaftSpeed 6585;
BA_ "SigType" SG_ 2297455358 TransDirectionalOutputShaftSpeed 1;
BA_ "SPN" SG_ 2297455358 TransHydrostaticLoop2Press 6584;
BA_ "SigType" SG_ 2297455358 TransHydrostaticLoop2Press 1;
BA_ "SPN" SG_ 2297455358 TransHydrostaticLoop1Press 6583;
BA_ "SigType" SG_ 2297455358 TransHydrostaticLoop1Press 1;
BA_ "SPN" SG_ 2498781694 EngCyl20AvrageCombustionDuration 6562;
BA_ "SigType" SG_ 2498781694 EngCyl20AvrageCombustionDuration 1;
BA_ "SPN" SG_ 2498781694 EngCyl20AvrgCntrOfCmbstionTiming 6561;
BA_ "SigType" SG_ 2498781694 EngCyl20AvrgCntrOfCmbstionTiming 1;
BA_ "SPN" SG_ 2498781694 EngCyl20AvrgStrtOfCmbstionTiming 6560;
BA_ "SigType" SG_ 2498781694 EngCyl20AvrgStrtOfCmbstionTiming 1;
BA_ "SPN" SG_ 2498781694 EngCyl20IndctdMeanEffectivePress 6559;
BA_ "SigType" SG_ 2498781694 EngCyl20IndctdMeanEffectivePress 1;
BA_ "SPN" SG_ 2498781438 EngCyl19AvrageCombustionDuration 6558;
BA_ "SigType" SG_ 2498781438 EngCyl19AvrageCombustionDuration 1;
BA_ "SPN" SG_ 2498781438 EngCyl19AvrgCntrOfCmbstionTiming 6557;
BA_ "SigType" SG_ 2498781438 EngCyl19AvrgCntrOfCmbstionTiming 1;
BA_ "SPN" SG_ 2498781438 EngCyl19AvrgStrtOfCmbstionTiming 6556;
BA_ "SigType" SG_ 2498781438 EngCyl19AvrgStrtOfCmbstionTiming 1;
BA_ "SPN" SG_ 2498781438 EngCyl19IndctdMeanEffectivePress 6555;
BA_ "SigType" SG_ 2498781438 EngCyl19IndctdMeanEffectivePress 1;
BA_ "SPN" SG_ 2498781182 EngCyl18AvrageCombustionDuration 6554;
BA_ "SigType" SG_ 2498781182 EngCyl18AvrageCombustionDuration 1;
BA_ "SPN" SG_ 2498781182 EngCyl18AvrgCntrOfCmbstionTiming 6553;
BA_ "SigType" SG_ 2498781182 EngCyl18AvrgCntrOfCmbstionTiming 1;
BA_ "SPN" SG_ 2498781182 EngCyl18AvrgStrtOfCmbstionTiming 6552;
BA_ "SigType" SG_ 2498781182 EngCyl18AvrgStrtOfCmbstionTiming 1;
BA_ "SPN" SG_ 2498781182 EngCyl18IndctdMeanEffectivePress 6551;
BA_ "SigType" SG_ 2498781182 EngCyl18IndctdMeanEffectivePress 1;
BA_ "SPN" SG_ 2498780926 EngCyl17AvrageCombustionDuration 6550;
BA_ "SigType" SG_ 2498780926 EngCyl17AvrageCombustionDuration 1;
BA_ "SPN" SG_ 2498780926 EngCyl17AvrgCntrOfCmbstionTiming 6549;
BA_ "SigType" SG_ 2498780926 EngCyl17AvrgCntrOfCmbstionTiming 1;
BA_ "SPN" SG_ 2498780926 EngCyl17AvrgStrtOfCmbstionTiming 6548;
BA_ "SigType" SG_ 2498780926 EngCyl17AvrgStrtOfCmbstionTiming 1;
BA_ "SPN" SG_ 2498780926 EngCyl17IndctdMeanEffectivePress 6547;
BA_ "SigType" SG_ 2498780926 EngCyl17IndctdMeanEffectivePress 1;
BA_ "SPN" SG_ 2498780670 EngCyl16AvrageCombustionDuration 6546;
BA_ "SigType" SG_ 2498780670 EngCyl16AvrageCombustionDuration 1;
BA_ "SPN" SG_ 2498780670 EngCyl16AvrgCntrOfCmbstionTiming 6545;
BA_ "SigType" SG_ 2498780670 EngCyl16AvrgCntrOfCmbstionTiming 1;
BA_ "SPN" SG_ 2498780670 EngCyl16AvrgStrtOfCmbstionTiming 6544;
BA_ "SigType" SG_ 2498780670 EngCyl16AvrgStrtOfCmbstionTiming 1;
BA_ "SPN" SG_ 2498780670 EngCyl16IndctdMeanEffectivePress 6543;
BA_ "SigType" SG_ 2498780670 EngCyl16IndctdMeanEffectivePress 1;
BA_ "SPN" SG_ 2498780414 EngCyl15AvrageCombustionDuration 6542;
BA_ "SigType" SG_ 2498780414 EngCyl15AvrageCombustionDuration 1;
BA_ "SPN" SG_ 2498780414 EngCyl15AvrgCntrOfCmbstionTiming 6541;
BA_ "SigType" SG_ 2498780414 EngCyl15AvrgCntrOfCmbstionTiming 1;
BA_ "SPN" SG_ 2498780414 EngCyl15AvrgStrtOfCmbstionTiming 6540;
BA_ "SigType" SG_ 2498780414 EngCyl15AvrgStrtOfCmbstionTiming 1;
BA_ "SPN" SG_ 2498780414 EngCyl15IndctdMeanEffectivePress 6539;
BA_ "SigType" SG_ 2498780414 EngCyl15IndctdMeanEffectivePress 1;
BA_ "SPN" SG_ 2498780158 EngCyl14AvrageCombustionDuration 6538;
BA_ "SigType" SG_ 2498780158 EngCyl14AvrageCombustionDuration 1;
BA_ "SPN" SG_ 2498780158 EngCyl14AvrgCntrOfCmbstionTiming 6537;
BA_ "SigType" SG_ 2498780158 EngCyl14AvrgCntrOfCmbstionTiming 1;
BA_ "SPN" SG_ 2498780158 EngCyl14AvrgStrtOfCmbstionTiming 6536;
BA_ "SigType" SG_ 2498780158 EngCyl14AvrgStrtOfCmbstionTiming 1;
BA_ "SPN" SG_ 2498780158 EngCyl14IndctdMeanEffectivePress 6535;
BA_ "SigType" SG_ 2498780158 EngCyl14IndctdMeanEffectivePress 1;
BA_ "SPN" SG_ 2498779902 EngCyl13AvrageCombustionDuration 6534;
BA_ "SigType" SG_ 2498779902 EngCyl13AvrageCombustionDuration 1;
BA_ "SPN" SG_ 2498779902 EngCyl13AvrgCntrOfCmbstionTiming 6533;
BA_ "SigType" SG_ 2498779902 EngCyl13AvrgCntrOfCmbstionTiming 1;
BA_ "SPN" SG_ 2498779902 EngCyl13AvrgStrtOfCmbstionTiming 6532;
BA_ "SigType" SG_ 2498779902 EngCyl13AvrgStrtOfCmbstionTiming 1;
BA_ "SPN" SG_ 2498779902 EngCyl13IndctdMeanEffectivePress 6531;
BA_ "SigType" SG_ 2498779902 EngCyl13IndctdMeanEffectivePress 1;
BA_ "SPN" SG_ 2498779646 EngCyl12AvrageCombustionDuration 6530;
BA_ "SigType" SG_ 2498779646 EngCyl12AvrageCombustionDuration 1;
BA_ "SPN" SG_ 2498779646 EngCyl12AvrgCntrOfCmbstionTiming 6529;
BA_ "SigType" SG_ 2498779646 EngCyl12AvrgCntrOfCmbstionTiming 1;
BA_ "SPN" SG_ 2498779646 EngCyl12AvrgStrtOfCmbstionTiming 6528;
BA_ "SigType" SG_ 2498779646 EngCyl12AvrgStrtOfCmbstionTiming 1;
BA_ "SPN" SG_ 2498779646 EngCyl12IndctdMeanEffectivePress 6527;
BA_ "SigType" SG_ 2498779646 EngCyl12IndctdMeanEffectivePress 1;
BA_ "SPN" SG_ 2498779390 EngCyl11AvrageCombustionDuration 6526;
BA_ "SigType" SG_ 2498779390 EngCyl11AvrageCombustionDuration 1;
BA_ "SPN" SG_ 2498779390 EngCyl11AvrgCntrOfCmbstionTiming 6525;
BA_ "SigType" SG_ 2498779390 EngCyl11AvrgCntrOfCmbstionTiming 1;
BA_ "SPN" SG_ 2498779390 EngCyl11AvrgStrtOfCmbstionTiming 6524;
BA_ "SigType" SG_ 2498779390 EngCyl11AvrgStrtOfCmbstionTiming 1;
BA_ "SPN" SG_ 2498779390 EngCyl11IndctdMeanEffectivePress 6523;
BA_ "SigType" SG_ 2498779390 EngCyl11IndctdMeanEffectivePress 1;
BA_ "SPN" SG_ 2498779134 EngCyl10AvrageCombustionDuration 6522;
BA_ "SigType" SG_ 2498779134 EngCyl10AvrageCombustionDuration 1;
BA_ "SPN" SG_ 2498779134 EngCyl10AvrgCntrOfCmbstionTiming 6521;
BA_ "SigType" SG_ 2498779134 EngCyl10AvrgCntrOfCmbstionTiming 1;
BA_ "SPN" SG_ 2498779134 EngCyl10AvrgStrtOfCmbstionTiming 6520;
BA_ "SigType" SG_ 2498779134 EngCyl10AvrgStrtOfCmbstionTiming 1;
BA_ "SPN" SG_ 2498779134 EngCyl10IndctdMeanEffectivePress 6519;
BA_ "SigType" SG_ 2498779134 EngCyl10IndctdMeanEffectivePress 1;
BA_ "SPN" SG_ 2498778878 EngCyl9AverageCombustionDuration 6518;
BA_ "SigType" SG_ 2498778878 EngCyl9AverageCombustionDuration 1;
BA_ "SPN" SG_ 2498778878 EngCyl9AvrgCntrOfCmbustionTiming 6517;
BA_ "SigType" SG_ 2498778878 EngCyl9AvrgCntrOfCmbustionTiming 1;
BA_ "SPN" SG_ 2498778878 EngCyl9AvrgStrtOfCmbustionTiming 6516;
BA_ "SigType" SG_ 2498778878 EngCyl9AvrgStrtOfCmbustionTiming 1;
BA_ "SPN" SG_ 2498778878 EngCyl9IndctedMeanEffectivePress 6515;
BA_ "SigType" SG_ 2498778878 EngCyl9IndctedMeanEffectivePress 1;
BA_ "SPN" SG_ 2365428734 GenFrequencySelection 4080;
BA_ "SPN" SG_ 2365428734 GenGoverningSpeedCommand 4079;
BA_ "SigType" SG_ 2365428734 GenGoverningSpeedCommand 5;
BA_ "SPN" SG_ 2365428734 GenAlternatorEfficiency 4078;
BA_ "SigType" SG_ 2365428734 GenAlternatorEfficiency 1;
BA_ "SPN" SG_ 2365428734 GenNotReadyToAutoParaState 3568;
BA_ "SigType" SG_ 2365428734 GenNotReadyToAutoParaState 5;
BA_ "SPN" SG_ 2365428734 GenCtrlNotInAutoStartState 3567;
BA_ "SigType" SG_ 2365428734 GenCtrlNotInAutoStartState 5;
BA_ "SPN" SG_ 2365428734 RequestedEngineControlMode 3542;
BA_ "SigType" SG_ 2365428734 RequestedEngineControlMode 4;
BA_ "SPN" SG_ 2365428734 EngSpeedGovernorDroop 5568;
BA_ "SigType" SG_ 2365428734 EngSpeedGovernorDroop 1;
BA_ "SPN" SG_ 2365428734 EngSpeedGovernorGainAdjust 5567;
BA_ "SigType" SG_ 2365428734 EngSpeedGovernorGainAdjust 1;
BA_ "SPN" SG_ 2365376254 EngOBDWarmUpSequence 5843;
BA_ "SigType" SG_ 2365376254 EngOBDWarmUpSequence 5;
BA_ "SPN" SG_ 2566703102 CertificationEngineFamilyName 5845;
BA_ "SPN" SG_ 2566703102 ModelYear 5844;
BA_ "SigType" SG_ 2566703102 ModelYear 3;
BA_ "SigType" SG_ 2566705918 DTC1 7;
BA_ "SPN" SG_ 2566705918 FlashProtectLamp 3041;
BA_ "SigType" SG_ 2566705918 FlashProtectLamp 5;
BA_ "SPN" SG_ 2566705918 FlashAmberWarningLamp 3040;
BA_ "SigType" SG_ 2566705918 FlashAmberWarningLamp 5;
BA_ "SPN" SG_ 2566705918 FlashRedStopLamp 3039;
BA_ "SigType" SG_ 2566705918 FlashRedStopLamp 5;
BA_ "SPN" SG_ 2566705918 FlashMalfuncIndicatorLamp 3038;
BA_ "SigType" SG_ 2566705918 FlashMalfuncIndicatorLamp 5;
BA_ "SPN" SG_ 2566705918 ProtectLampStatus 987;
BA_ "SigType" SG_ 2566705918 ProtectLampStatus 5;
BA_ "SPN" SG_ 2566705918 AmberWarningLampStatus 624;
BA_ "SigType" SG_ 2566705918 AmberWarningLampStatus 5;
BA_ "SPN" SG_ 2566705918 RedStopLampState 623;
BA_ "SigType" SG_ 2566705918 RedStopLampState 4;
BA_ "SPN" SG_ 2566705918 MalfunctionIndicatorLampStatus 1213;
BA_ "SigType" SG_ 2566705918 MalfunctionIndicatorLampStatus 5;
BA_ "SigType" SG_ 2566705918 DTC5 7;
BA_ "SigType" SG_ 2566705918 DTC4 7;
BA_ "SigType" SG_ 2566705918 DTC3 7;
BA_ "SigType" SG_ 2566705918 DTC2 7;
BA_ "SigType" SG_ 2566705662 DTC1 7;
BA_ "SPN" SG_ 2566705662 FlashProtectLamp 3041;
BA_ "SigType" SG_ 2566705662 FlashProtectLamp 5;
BA_ "SPN" SG_ 2566705662 FlashAmberWarningLamp 3040;
BA_ "SigType" SG_ 2566705662 FlashAmberWarningLamp 5;
BA_ "SPN" SG_ 2566705662 FlashRedStopLamp 3039;
BA_ "SigType" SG_ 2566705662 FlashRedStopLamp 5;
BA_ "SPN" SG_ 2566705662 FlashMalfuncIndicatorLamp 3038;
BA_ "SigType" SG_ 2566705662 FlashMalfuncIndicatorLamp 5;
BA_ "SPN" SG_ 2566705662 ProtectLampStatus 987;
BA_ "SigType" SG_ 2566705662 ProtectLampStatus 5;
BA_ "SPN" SG_ 2566705662 AmberWarningLampStatus 624;
BA_ "SigType" SG_ 2566705662 AmberWarningLampStatus 5;
BA_ "SPN" SG_ 2566705662 RedStopLampState 623;
BA_ "SigType" SG_ 2566705662 RedStopLampState 4;
BA_ "SPN" SG_ 2566705662 MalfunctionIndicatorLampStatus 1213;
BA_ "SigType" SG_ 2566705662 MalfunctionIndicatorLampStatus 5;
BA_ "SigType" SG_ 2566705662 DTC5 7;
BA_ "SigType" SG_ 2566705662 DTC4 7;
BA_ "SigType" SG_ 2566705662 DTC3 7;
BA_ "SigType" SG_ 2566705662 DTC2 7;
BA_ "SPN" SG_ 2349465342 StaticRollAngleStatus 5583;
BA_ "SPN" SG_ 2349465342 StaticRollAngle 5582;
BA_ "GenSigStartValue" SG_ 2349465342 StaticRollAngle 35;
BA_ "SigType" SG_ 2349465342 StaticRollAngle 1;
BA_ "SPN" SG_ 2498777086 EngCyl2AverageCombustionDuration 6490;
BA_ "SigType" SG_ 2498777086 EngCyl2AverageCombustionDuration 1;
BA_ "SPN" SG_ 2498777086 EngCyl2AvrgCntrOfCmbustionTiming 6489;
BA_ "SigType" SG_ 2498777086 EngCyl2AvrgCntrOfCmbustionTiming 1;
BA_ "SPN" SG_ 2498777086 EngCyl2AvrgStrtOfCmbustionTiming 6488;
BA_ "SigType" SG_ 2498777086 EngCyl2AvrgStrtOfCmbustionTiming 1;
BA_ "SPN" SG_ 2498777086 EngCyl2IndctedMeanEffectivePress 6487;
BA_ "SigType" SG_ 2498777086 EngCyl2IndctedMeanEffectivePress 1;
BA_ "SPN" SG_ 2498776830 EngCyl1AverageCombustionDuration 6486;
BA_ "SigType" SG_ 2498776830 EngCyl1AverageCombustionDuration 1;
BA_ "SPN" SG_ 2498776830 EngCyl1AvrgCntrOfCmbustionTiming 6485;
BA_ "SigType" SG_ 2498776830 EngCyl1AvrgCntrOfCmbustionTiming 1;
BA_ "SPN" SG_ 2498776830 EngCyl1AvrgStrtOfCmbustionTiming 6484;
BA_ "SigType" SG_ 2498776830 EngCyl1AvrgStrtOfCmbustionTiming 1;
BA_ "SPN" SG_ 2498776830 EngCyl1IndctedMeanEffectivePress 6483;
BA_ "SigType" SG_ 2498776830 EngCyl1IndctedMeanEffectivePress 1;
BA_ "SPN" SG_ 2364558846 EngCyl20PrssSensorPreliminaryFMI 6475;
BA_ "SPN" SG_ 2364558846 EngCyl20SynchronousKnockLevel 6474;
BA_ "SigType" SG_ 2364558846 EngCyl20SynchronousKnockLevel 1;
BA_ "SPN" SG_ 2364558846 EngCyl20PeakPress 6473;
BA_ "SigType" SG_ 2364558846 EngCyl20PeakPress 1;
BA_ "SPN" SG_ 2364558846 EngCyl20HeatRelease 6472;
BA_ "SigType" SG_ 2364558846 EngCyl20HeatRelease 1;
BA_ "SPN" SG_ 2364558590 EngCyl19PrssSensorPreliminaryFMI 6471;
BA_ "SPN" SG_ 2364558590 EngCyl19SynchronousKnockLevel 6470;
BA_ "SigType" SG_ 2364558590 EngCyl19SynchronousKnockLevel 1;
BA_ "SPN" SG_ 2364558590 EngCyl19PeakPress 6469;
BA_ "SigType" SG_ 2364558590 EngCyl19PeakPress 1;
BA_ "SPN" SG_ 2364558590 EngCyl19HeatRelease 6468;
BA_ "SigType" SG_ 2364558590 EngCyl19HeatRelease 1;
BA_ "SPN" SG_ 2364558334 EngCyl18PrssSensorPreliminaryFMI 6467;
BA_ "SPN" SG_ 2364558334 EngCyl18SynchronousKnockLevel 6466;
BA_ "SigType" SG_ 2364558334 EngCyl18SynchronousKnockLevel 1;
BA_ "SPN" SG_ 2364558334 EngCyl18PeakPress 6465;
BA_ "SigType" SG_ 2364558334 EngCyl18PeakPress 1;
BA_ "SPN" SG_ 2364558334 EngCyl18HeatRelease 6464;
BA_ "SigType" SG_ 2364558334 EngCyl18HeatRelease 1;
BA_ "SPN" SG_ 2364558078 EngCyl17PrssSensorPreliminaryFMI 6463;
BA_ "SPN" SG_ 2364558078 EngCyl17SynchronousKnockLevel 6462;
BA_ "SigType" SG_ 2364558078 EngCyl17SynchronousKnockLevel 1;
BA_ "SPN" SG_ 2364558078 EngCyl17PeakPress 6461;
BA_ "SigType" SG_ 2364558078 EngCyl17PeakPress 1;
BA_ "SPN" SG_ 2364558078 EngCyl17HeatRelease 6460;
BA_ "SigType" SG_ 2364558078 EngCyl17HeatRelease 1;
BA_ "SPN" SG_ 2364557822 EngCyl16PrssSensorPreliminaryFMI 6459;
BA_ "SPN" SG_ 2364557822 EngCyl16SynchronousKnockLevel 6458;
BA_ "SigType" SG_ 2364557822 EngCyl16SynchronousKnockLevel 1;
BA_ "SPN" SG_ 2364557822 EngCyl16PeakPress 6457;
BA_ "SigType" SG_ 2364557822 EngCyl16PeakPress 1;
BA_ "SPN" SG_ 2364557822 EngCyl16HeatRelease 6456;
BA_ "SigType" SG_ 2364557822 EngCyl16HeatRelease 1;
BA_ "SPN" SG_ 2364557566 EngCyl15PrssSensorPreliminaryFMI 6455;
BA_ "SPN" SG_ 2364557566 EngCyl15SynchronousKnockLevel 6454;
BA_ "SigType" SG_ 2364557566 EngCyl15SynchronousKnockLevel 1;
BA_ "SPN" SG_ 2364557566 EngCyl15PeakPress 6453;
BA_ "SigType" SG_ 2364557566 EngCyl15PeakPress 1;
BA_ "SPN" SG_ 2364557566 EngCyl15HeatRelease 6452;
BA_ "SigType" SG_ 2364557566 EngCyl15HeatRelease 1;
BA_ "SPN" SG_ 2364557310 EngCyl14PrssSensorPreliminaryFMI 6451;
BA_ "SPN" SG_ 2364557310 EngCyl14SynchronousKnockLevel 6450;
BA_ "SigType" SG_ 2364557310 EngCyl14SynchronousKnockLevel 1;
BA_ "SPN" SG_ 2364557310 EngCyl14PeakPress 6449;
BA_ "SigType" SG_ 2364557310 EngCyl14PeakPress 1;
BA_ "SPN" SG_ 2364557310 EngCyl14HeatRelease 6448;
BA_ "SigType" SG_ 2364557310 EngCyl14HeatRelease 1;
BA_ "SPN" SG_ 2364557054 EngCyl13PrssSensorPreliminaryFMI 6447;
BA_ "SPN" SG_ 2364557054 EngCyl13SynchronousKnockLevel 6446;
BA_ "SigType" SG_ 2364557054 EngCyl13SynchronousKnockLevel 1;
BA_ "SPN" SG_ 2364557054 EngCyl13PeakPress 6445;
BA_ "SigType" SG_ 2364557054 EngCyl13PeakPress 1;
BA_ "SPN" SG_ 2364557054 EngCyl13HeatRelease 6444;
BA_ "SigType" SG_ 2364557054 EngCyl13HeatRelease 1;
BA_ "SPN" SG_ 2364556798 EngCyl12PrssSensorPreliminaryFMI 6443;
BA_ "SPN" SG_ 2364556798 EngCyl12SynchronousKnockLevel 6442;
BA_ "SigType" SG_ 2364556798 EngCyl12SynchronousKnockLevel 1;
BA_ "SPN" SG_ 2364556798 EngCyl12PeakPress 6441;
BA_ "SigType" SG_ 2364556798 EngCyl12PeakPress 1;
BA_ "SPN" SG_ 2364556798 EngCyl12HeatRelease 6440;
BA_ "SigType" SG_ 2364556798 EngCyl12HeatRelease 1;
BA_ "SPN" SG_ 2364556542 EngCyl11PrssSensorPreliminaryFMI 6439;
BA_ "SPN" SG_ 2364556542 EngCyl11SynchronousKnockLevel 6438;
BA_ "SigType" SG_ 2364556542 EngCyl11SynchronousKnockLevel 1;
BA_ "SPN" SG_ 2364556542 EngCyl11PeakPress 6437;
BA_ "SigType" SG_ 2364556542 EngCyl11PeakPress 1;
BA_ "SPN" SG_ 2364556542 EngCyl11HeatRelease 6436;
BA_ "SigType" SG_ 2364556542 EngCyl11HeatRelease 1;
BA_ "SPN" SG_ 2364556286 EngCyl10PrssSensorPreliminaryFMI 6435;
BA_ "SPN" SG_ 2364556286 EngCyl10SynchronousKnockLevel 6434;
BA_ "SigType" SG_ 2364556286 EngCyl10SynchronousKnockLevel 1;
BA_ "SPN" SG_ 2364556286 EngCyl10PeakPress 6433;
BA_ "SigType" SG_ 2364556286 EngCyl10PeakPress 1;
BA_ "SPN" SG_ 2364556286 EngCyl10HeatRelease 6432;
BA_ "SigType" SG_ 2364556286 EngCyl10HeatRelease 1;
BA_ "SPN" SG_ 2364556030 EngCyl9PressSensorPreliminaryFMI 6431;
BA_ "SPN" SG_ 2364556030 EngCyl9SynchronousKnockLevel 6430;
BA_ "SigType" SG_ 2364556030 EngCyl9SynchronousKnockLevel 1;
BA_ "SPN" SG_ 2364556030 EngCyl9PeakPress 6429;
BA_ "SigType" SG_ 2364556030 EngCyl9PeakPress 1;
BA_ "SPN" SG_ 2364556030 EngCyl9HeatRelease 6428;
BA_ "SigType" SG_ 2364556030 EngCyl9HeatRelease 1;
BA_ "SPN" SG_ 2364555774 EngCyl8PressSensorPreliminaryFMI 6427;
BA_ "SPN" SG_ 2364555774 EngCyl8SynchronousKnockLevel 6426;
BA_ "SigType" SG_ 2364555774 EngCyl8SynchronousKnockLevel 1;
BA_ "SPN" SG_ 2364555774 EngCyl8PeakPress 6425;
BA_ "SigType" SG_ 2364555774 EngCyl8PeakPress 1;
BA_ "SPN" SG_ 2364555774 EngCyl8HeatRelease 6424;
BA_ "SigType" SG_ 2364555774 EngCyl8HeatRelease 1;
BA_ "SPN" SG_ 2364555518 EngCyl7PressSensorPreliminaryFMI 6423;
BA_ "SPN" SG_ 2364555518 EngCyl7SynchronousKnockLevel 6422;
BA_ "SigType" SG_ 2364555518 EngCyl7SynchronousKnockLevel 1;
BA_ "SPN" SG_ 2364555518 EngCyl7PeakPress 6421;
BA_ "SigType" SG_ 2364555518 EngCyl7PeakPress 1;
BA_ "SPN" SG_ 2364555518 EngCyl7HeatRelease 6420;
BA_ "SigType" SG_ 2364555518 EngCyl7HeatRelease 1;
BA_ "SPN" SG_ 2364555262 EngCyl6PressSensorPreliminaryFMI 6419;
BA_ "SPN" SG_ 2364555262 EngCyl6SynchronousKnockLevel 6418;
BA_ "SigType" SG_ 2364555262 EngCyl6SynchronousKnockLevel 1;
BA_ "SPN" SG_ 2364555262 EngCyl6PeakPress 6417;
BA_ "SigType" SG_ 2364555262 EngCyl6PeakPress 1;
BA_ "SPN" SG_ 2364555262 EngCyl6HeatRelease 6416;
BA_ "SigType" SG_ 2364555262 EngCyl6HeatRelease 1;
BA_ "SPN" SG_ 2364555006 EngCyl5PressSensorPreliminaryFMI 6415;
BA_ "SPN" SG_ 2364555006 EngCyl5SynchronousKnockLevel 6414;
BA_ "SigType" SG_ 2364555006 EngCyl5SynchronousKnockLevel 1;
BA_ "SPN" SG_ 2364555006 EngCyl5PeakPress 6413;
BA_ "SigType" SG_ 2364555006 EngCyl5PeakPress 1;
BA_ "SPN" SG_ 2364555006 EngCyl5HeatRelease 6412;
BA_ "SigType" SG_ 2364555006 EngCyl5HeatRelease 1;
BA_ "SPN" SG_ 2364554750 EngCyl4PressSensorPreliminaryFMI 6411;
BA_ "SPN" SG_ 2364554750 EngCyl4SynchronousKnockLevel 6410;
BA_ "SigType" SG_ 2364554750 EngCyl4SynchronousKnockLevel 1;
BA_ "SPN" SG_ 2364554750 EngCyl4PeakPress 6409;
BA_ "SigType" SG_ 2364554750 EngCyl4PeakPress 1;
BA_ "SPN" SG_ 2364554750 EngCyl4HeatRelease 6408;
BA_ "SigType" SG_ 2364554750 EngCyl4HeatRelease 1;
BA_ "SPN" SG_ 2364554494 EngCyl3PressSensorPreliminaryFMI 6407;
BA_ "SPN" SG_ 2364554494 EngCyl3SynchronousKnockLevel 6406;
BA_ "SigType" SG_ 2364554494 EngCyl3SynchronousKnockLevel 1;
BA_ "SPN" SG_ 2364554494 EngCyl3PeakPress 6405;
BA_ "SigType" SG_ 2364554494 EngCyl3PeakPress 1;
BA_ "SPN" SG_ 2364554494 EngCyl3HeatRelease 6404;
BA_ "SigType" SG_ 2364554494 EngCyl3HeatRelease 1;
BA_ "SPN" SG_ 2364554238 EngCyl2PressSensorPreliminaryFMI 6403;
BA_ "SPN" SG_ 2364554238 EngCyl2SynchronousKnockLevel 6402;
BA_ "SigType" SG_ 2364554238 EngCyl2SynchronousKnockLevel 1;
BA_ "SPN" SG_ 2364554238 EngCyl2PeakPress 6401;
BA_ "SigType" SG_ 2364554238 EngCyl2PeakPress 1;
BA_ "SPN" SG_ 2364554238 EngCyl2HeatRelease 6400;
BA_ "SigType" SG_ 2364554238 EngCyl2HeatRelease 1;
BA_ "SPN" SG_ 2364553982 EngCyl1PressSensorPreliminaryFMI 6399;
BA_ "SPN" SG_ 2364553982 EngCyl1SynchronousKnockLevel 6398;
BA_ "SigType" SG_ 2364553982 EngCyl1SynchronousKnockLevel 1;
BA_ "SPN" SG_ 2364553982 EngCyl1PeakPress 6397;
BA_ "SigType" SG_ 2364553982 EngCyl1PeakPress 1;
BA_ "SPN" SG_ 2364553982 EngCyl1HeatRelease 6396;
BA_ "SigType" SG_ 2364553982 EngCyl1HeatRelease 1;
BA_ "SPN" SG_ 2364553726 EngTotalIntakeMassAirFlowRate 6393;
BA_ "SigType" SG_ 2364553726 EngTotalIntakeMassAirFlowRate 1;
BA_ "SPN" SG_ 2364553726 EngDesiredAirFuelRatio 6392;
BA_ "SigType" SG_ 2364553726 EngDesiredAirFuelRatio 1;
BA_ "SPN" SG_ 2364553470 EngCylTorque 6389;
BA_ "SigType" SG_ 2364553470 EngCylTorque 1;
BA_ "SPN" SG_ 2364553470 EngCylDieselMassFlowRateCmd 6388;
BA_ "SigType" SG_ 2364553470 EngCylDieselMassFlowRateCmd 1;
BA_ "SPN" SG_ 2364553470 EngCylGasMassFlowRateCmd 6387;
BA_ "SigType" SG_ 2364553470 EngCylGasMassFlowRateCmd 1;
BA_ "SPN" SG_ 2364553470 EngGasFuelPercentageCmd 6386;
BA_ "SigType" SG_ 2364553470 EngGasFuelPercentageCmd 1;
BA_ "SPN" SG_ 2364553470 EngDualFuelModeCmd 6792;
BA_ "SigType" SG_ 2364553470 EngDualFuelModeCmd 5;
BA_ "SPN" SG_ 2364553214 EngTrbCmprssrBlwffActtr1OprtnStt 6316;
BA_ "SPN" SG_ 2364553214 EngTrbCmprssrBlowoffActuator1Pos 6315;
BA_ "SigType" SG_ 2364553214 EngTrbCmprssrBlowoffActuator1Pos 1;
BA_ "SPN" SG_ 2364553214 EngTrbCmprssrBlwffActtr1DsredPos 6314;
BA_ "SigType" SG_ 2364553214 EngTrbCmprssrBlwffActtr1DsredPos 1;
BA_ "SPN" SG_ 2364553214 EngTrbCmprssrBlwoffActuator1Temp 6313;
BA_ "SigType" SG_ 2364553214 EngTrbCmprssrBlwoffActuator1Temp 1;
BA_ "SPN" SG_ 2364553214 EngTrbCmprssrBlwffActtr1TmpSttus 6312;
BA_ "SPN" SG_ 2364553214 EngTrbCmprssrBlwffActtr1PrlmnryF 6311;
BA_ "SPN" SG_ 2364547838 PersistentLimitStatus 4307;
BA_ "SPN" SG_ 2364547838 MachineSelectedSpeedSource 4308;
BA_ "SPN" SG_ 2364547838 MachineSelectedDirection 4309;
BA_ "SigType" SG_ 2364547838 MachineSelectedDirection 4;
BA_ "SPN" SG_ 2364547838 MachineSelectedDistance 4306;
BA_ "SPN" SG_ 2364547838 MachineSelectedSpeed 4305;
BA_ "SPN" SG_ 2364546814 GeneratorGoverningBias 3938;
BA_ "SigType" SG_ 2364546814 GeneratorGoverningBias 1;
BA_ "SPN" SG_ 2364538622 ManufacturerSpecificInformation 2550;
BA_ "SPN" SG_ 2566767614 AccelPedal2Channel3 2626;
BA_ "SigType" SG_ 2566767614 AccelPedal2Channel3 1;
BA_ "SPN" SG_ 2566767614 AccelPedal2Channel2 2625;
BA_ "SigType" SG_ 2566767614 AccelPedal2Channel2 1;
BA_ "SPN" SG_ 2566767614 AccelPedal1Channel3 2624;
BA_ "SigType" SG_ 2566767614 AccelPedal1Channel3 1;
BA_ "SPN" SG_ 2566767614 AccelPedal1Channel2 2623;
BA_ "SigType" SG_ 2566767614 AccelPedal1Channel2 1;
BA_ "SPN" SG_ 2559049470 DesiredEngFuelingState 5793;
BA_ "SigType" SG_ 2559049470 DesiredEngFuelingState 5;
BA_ "SPN" SG_ 2559049470 RequestedFuelType 6317;
BA_ "SPN" SG_ 2559049470 EngGasFuelSupplyDesiredPress 6715;
BA_ "SigType" SG_ 2559049470 EngGasFuelSupplyDesiredPress 1;
BA_ "SPN" SG_ 2559049470 EngGasFuelUsageInhibited 6833;
BA_ "SigType" SG_ 2559049470 EngGasFuelUsageInhibited 4;
BA_ "SPN" SG_ 2349596414 AEBS2MessageChecksum 5683;
BA_ "SPN" SG_ 2349596414 AEBS2MessageCounter 5682;
BA_ "SPN" SG_ 2349596414 DrvrActvtnDmndFrAdvncdEmrgncyBrk 5681;
BA_ "SigType" SG_ 2349596414 DrvrActvtnDmndFrAdvncdEmrgncyBrk 5;
BA_ "SPN" SG_ 2362244862 DataDictionaryRow 2427;
BA_ "SPN" SG_ 2362244862 DataDictionaryColumn 2428;
BA_ "SPN" SG_ 2362244862 ImplementType 2425;
BA_ "SPN" SG_ 2362244862 ImplementPos 2426;
BA_ "SPN" SG_ 2362244862 DataFormat_ErrorCondition 2419;
BA_ "SigType" SG_ 2362244862 DataFormat_ErrorCondition 4;
BA_ "SPN" SG_ 2362244862 ProcessDataType 2420;
BA_ "SigType" SG_ 2362244862 ProcessDataType 4;
BA_ "SPN" SG_ 2362244862 ProcessDataModifier 2421;
BA_ "SPN" SG_ 2362244862 RepetitionRateParameter 2418;
BA_ "SPN" SG_ 2362179326 ProcessVariableValue 2429;
BA_ "SPN" SG_ 2362179326 DataDictionaryRow 2427;
BA_ "SPN" SG_ 2362179326 DataDictionaryColumn 2428;
BA_ "SPN" SG_ 2362179326 ImplementType 2425;
BA_ "SPN" SG_ 2362179326 ImplementPos 2426;
BA_ "SPN" SG_ 2362179326 CountNumber 2422;
BA_ "SPN" SG_ 2362179326 DataFormat_ErrorCondition 2419;
BA_ "SigType" SG_ 2362179326 DataFormat_ErrorCondition 4;
BA_ "SPN" SG_ 2362179326 ProcessDataType 2420;
BA_ "SigType" SG_ 2362179326 ProcessDataType 4;
BA_ "SPN" SG_ 2362179326 ProcessDataModifier 2421;
BA_ "SPN" SG_ 2361851646 ValveFailSafeMode 2934;
BA_ "SigType" SG_ 2361851646 ValveFailSafeMode 4;
BA_ "SPN" SG_ 2361851646 ValveState 2932;
BA_ "SPN" SG_ 2361851646 RetractPortEstFlow 2940;
BA_ "SPN" SG_ 2361851646 ExtendPortEstFlow 2939;
BA_ "SPN" SG_ 2361786110 ReturnPortPress 2943;
BA_ "SPN" SG_ 2361786110 RetractPortPress 2942;
BA_ "SPN" SG_ 2361786110 ExtendPortPress 2941;
BA_ "SPN" SG_ 2361786110 RetractPortMeasuredFlow 2938;
BA_ "SPN" SG_ 2361786110 ExtendPortMeasuredFlow 2937;
BA_ "SPN" SG_ 2361720574 PortFlowCmd 2944;
BA_ "SystemSignalLongSymbol" SG_ 2358509310 VehicleSystemInstanceQualifierFl "VehicleSystemInstanceQualifierFlag";
BA_ "SystemSignalLongSymbol" SG_ 2358509310 ArbitraryAddressCapableQualifier "ArbitraryAddressCapableQualifierFlag";
BA_ "SPN" SG_ 2558983934 SwitchedPowerOutput18Cmd 6002;
BA_ "SigType" SG_ 2558983934 SwitchedPowerOutput18Cmd 5;
BA_ "SPN" SG_ 2558983934 SwitchedPowerOutput19Cmd 6001;
BA_ "SigType" SG_ 2558983934 SwitchedPowerOutput19Cmd 5;
BA_ "SPN" SG_ 2558983934 SwitchedPowerOutput20Cmd 6000;
BA_ "SigType" SG_ 2558983934 SwitchedPowerOutput20Cmd 5;
BA_ "SPN" SG_ 2558983934 SwitchedPowerOutput13Cmd 5999;
BA_ "SigType" SG_ 2558983934 SwitchedPowerOutput13Cmd 5;
BA_ "SPN" SG_ 2558983934 SwitchedPowerOutput14Cmd 5998;
BA_ "SigType" SG_ 2558983934 SwitchedPowerOutput14Cmd 5;
BA_ "SPN" SG_ 2558983934 SwitchedPowerOutput15Cmd 5997;
BA_ "SigType" SG_ 2558983934 SwitchedPowerOutput15Cmd 5;
BA_ "SPN" SG_ 2558983934 SwitchedPowerOutput16Cmd 5996;
BA_ "SigType" SG_ 2558983934 SwitchedPowerOutput16Cmd 5;
BA_ "SPN" SG_ 2558983934 SwitchedPowerOutput9Cmd 5995;
BA_ "SigType" SG_ 2558983934 SwitchedPowerOutput9Cmd 5;
BA_ "SPN" SG_ 2558983934 SwitchedPowerOutput10Cmd 5994;
BA_ "SigType" SG_ 2558983934 SwitchedPowerOutput10Cmd 5;
BA_ "SPN" SG_ 2558983934 SwitchedPowerOutput29Cmd 6015;
BA_ "SigType" SG_ 2558983934 SwitchedPowerOutput29Cmd 5;
BA_ "SPN" SG_ 2558983934 SwitchedPowerOutput30Cmd 6014;
BA_ "SigType" SG_ 2558983934 SwitchedPowerOutput30Cmd 5;
BA_ "SPN" SG_ 2558983934 SwitchedPowerOutput31Cmd 6013;
BA_ "SigType" SG_ 2558983934 SwitchedPowerOutput31Cmd 5;
BA_ "SPN" SG_ 2558983934 SwitchedPowerOutput32Cmd 6012;
BA_ "SigType" SG_ 2558983934 SwitchedPowerOutput32Cmd 5;
BA_ "SPN" SG_ 2558983934 SwitchedPowerOutput25Cmd 6011;
BA_ "SigType" SG_ 2558983934 SwitchedPowerOutput25Cmd 5;
BA_ "SPN" SG_ 2558983934 SwitchedPowerOutput26Cmd 6010;
BA_ "SigType" SG_ 2558983934 SwitchedPowerOutput26Cmd 5;
BA_ "SPN" SG_ 2558983934 SwitchedPowerOutput27Cmd 6009;
BA_ "SigType" SG_ 2558983934 SwitchedPowerOutput27Cmd 5;
BA_ "SPN" SG_ 2558983934 SwitchedPowerOutput28Cmd 6008;
BA_ "SigType" SG_ 2558983934 SwitchedPowerOutput28Cmd 5;
BA_ "SPN" SG_ 2558983934 SwitchedPowerOutput21Cmd 6007;
BA_ "SigType" SG_ 2558983934 SwitchedPowerOutput21Cmd 5;
BA_ "SPN" SG_ 2558983934 SwitchedPowerOutput22Cmd 6006;
BA_ "SigType" SG_ 2558983934 SwitchedPowerOutput22Cmd 5;
BA_ "SPN" SG_ 2558983934 SwitchedPowerOutput23Cmd 6005;
BA_ "SigType" SG_ 2558983934 SwitchedPowerOutput23Cmd 5;
BA_ "SPN" SG_ 2558983934 SwitchedPowerOutput24Cmd 6004;
BA_ "SigType" SG_ 2558983934 SwitchedPowerOutput24Cmd 5;
BA_ "SPN" SG_ 2558983934 SwitchedPowerOutput17Cmd 6003;
BA_ "SigType" SG_ 2558983934 SwitchedPowerOutput17Cmd 5;
BA_ "SPN" SG_ 2558983934 SwitchedPowerOutput11Cmd 5993;
BA_ "SigType" SG_ 2558983934 SwitchedPowerOutput11Cmd 5;
BA_ "SPN" SG_ 2558983934 SwitchedPowerOutput12Cmd 5992;
BA_ "SigType" SG_ 2558983934 SwitchedPowerOutput12Cmd 5;
BA_ "SPN" SG_ 2558983934 SwitchedPowerOutput5Cmd 5991;
BA_ "SigType" SG_ 2558983934 SwitchedPowerOutput5Cmd 5;
BA_ "SPN" SG_ 2558983934 SwitchedPowerOutput6Cmd 5990;
BA_ "SigType" SG_ 2558983934 SwitchedPowerOutput6Cmd 5;
BA_ "SPN" SG_ 2558983934 SwitchedPowerOutput7Cmd 5989;
BA_ "SigType" SG_ 2558983934 SwitchedPowerOutput7Cmd 5;
BA_ "SPN" SG_ 2558983934 SwitchedPowerOutput8Cmd 5988;
BA_ "SigType" SG_ 2558983934 SwitchedPowerOutput8Cmd 5;
BA_ "SPN" SG_ 2558983934 SwitchedPowerOutput1Cmd 5987;
BA_ "SigType" SG_ 2558983934 SwitchedPowerOutput1Cmd 5;
BA_ "SPN" SG_ 2558983934 SwitchedPowerOutput2Cmd 5986;
BA_ "SigType" SG_ 2558983934 SwitchedPowerOutput2Cmd 5;
BA_ "SPN" SG_ 2558983934 SwitchedPowerOutput3Cmd 5985;
BA_ "SigType" SG_ 2558983934 SwitchedPowerOutput3Cmd 5;
BA_ "SPN" SG_ 2558983934 SwitchedPowerOutput4Cmd 5984;
BA_ "SigType" SG_ 2558983934 SwitchedPowerOutput4Cmd 5;
BA_ "SPN" SG_ 2349727486 TransMode10 6570;
BA_ "SigType" SG_ 2349727486 TransMode10 5;
BA_ "SPN" SG_ 2349727486 TransMode9 6569;
BA_ "SigType" SG_ 2349727486 TransMode9 5;
BA_ "SPN" SG_ 2550988542 AccelPedalPos3 28;
BA_ "SigType" SG_ 2550988542 AccelPedalPos3 1;
BA_ "SPN" SG_ 2566767358 EngFuelIsolationCtrl 7394;
BA_ "SigType" SG_ 2566767358 EngFuelIsolationCtrl 5;
BA_ "SPN" SG_ 2566767358 FuelType 5837;
BA_ "SPN" SG_ 2566767358 EngFuelMassFlowRate 5833;
BA_ "SigType" SG_ 2566767358 EngFuelMassFlowRate 1;
BA_ "SPN" SG_ 2566767358 EngExhstGsRcrcltn1Valve2PosError 5830;
BA_ "SigType" SG_ 2566767358 EngExhstGsRcrcltn1Valve2PosError 1;
BA_ "SPN" SG_ 2566767358 EngExhstGsRcrcltn1Valve1PosError 5829;
BA_ "SigType" SG_ 2566767358 EngExhstGsRcrcltn1Valve1PosError 1;
BA_ "SPN" SG_ 2566706686 AT1DslExhustFluidPump2MotorSpeed 7461;
BA_ "SigType" SG_ 2566706686 AT1DslExhustFluidPump2MotorSpeed 1;
BA_ "SPN" SG_ 2566706686 AT1DieselExhaustFluidPumpHeater 5706;
BA_ "SigType" SG_ 2566706686 AT1DieselExhaustFluidPumpHeater 1;
BA_ "SPN" SG_ 2566705406 AT1ParticulateSensorCurrent 7393;
BA_ "SigType" SG_ 2566705406 AT1ParticulateSensorCurrent 1;
BA_ "SPN" SG_ 2566705406 AT2ParticulateSensor 5836;
BA_ "SigType" SG_ 2566705406 AT2ParticulateSensor 1;
BA_ "SPN" SG_ 2566705406 AT1ParticulateSensor 5835;
BA_ "SigType" SG_ 2566705406 AT1ParticulateSensor 1;
BA_ "SPN" SG_ 2566705150 AT2IntkNOxSnsrSlfdagnosisTrigger 5712;
BA_ "SPN" SG_ 2566705150 AT2OtltNOxSnsrSlfdagnosisTrigger 5711;
BA_ "SPN" SG_ 2566705150 AT1IntkNOxSnsrSlfdagnosisTrigger 5710;
BA_ "SPN" SG_ 2566705150 AT1OtltNOxSnsrSlfdagnosisTrigger 5709;
BA_ "SPN" SG_ 2566704382 AT2OutletGasSensorPowerSupply 5761;
BA_ "SigType" SG_ 2566704382 AT2OutletGasSensorPowerSupply 5;
BA_ "SPN" SG_ 2566704382 AT2IntakeGasSensorPowerSupply 5760;
BA_ "SigType" SG_ 2566704382 AT2IntakeGasSensorPowerSupply 5;
BA_ "SPN" SG_ 2566704382 AT1OutletGasSensorPowerSupply 5759;
BA_ "SigType" SG_ 2566704382 AT1OutletGasSensorPowerSupply 5;
BA_ "SPN" SG_ 2566704382 AT1IntakeGasSensorPowerSupply 5758;
BA_ "SigType" SG_ 2566704382 AT1IntakeGasSensorPowerSupply 5;
BA_ "SPN" SG_ 2566704126 EngExhstGsRcrcltn1Acttr2PrlmnryF 5767;
BA_ "SPN" SG_ 2566704126 EngExhstGsRcrcltn1Acttr2OprtnStt 5772;
BA_ "SPN" SG_ 2566704126 EngExhstGsRcrcltn1Acttr1OprtnStt 5771;
BA_ "SPN" SG_ 2566704126 EngExhstGsRcrcltn1Acttr2DsredPos 5770;
BA_ "SigType" SG_ 2566704126 EngExhstGsRcrcltn1Acttr2DsredPos 1;
BA_ "SPN" SG_ 2566704126 EngExhstGsRcrclton1Actuator2Temp 5769;
BA_ "SigType" SG_ 2566704126 EngExhstGsRcrclton1Actuator2Temp 1;
BA_ "SPN" SG_ 2566704126 EngExhstGsRcrcltn1Acttr2TmpSttus 5768;
BA_ "SPN" SG_ 2566704126 EngExhstGsRcrcltn1Acttr1DsredPos 5766;
BA_ "SigType" SG_ 2566704126 EngExhstGsRcrcltn1Acttr1DsredPos 1;
BA_ "SPN" SG_ 2566704126 EngExhstGsRcrclton1Actuator1Temp 5765;
BA_ "SigType" SG_ 2566704126 EngExhstGsRcrclton1Actuator1Temp 1;
BA_ "SPN" SG_ 2566704126 EngExhstGsRcrcltn1Acttr1TmpSttus 5764;
BA_ "SPN" SG_ 2566704126 EngExhstGsRcrcltn1Acttr1PrlmnryF 5763;
BA_ "SPN" SG_ 2566703870 EngExhstGsRcrcltn2Acttr2OprtnStt 5782;
BA_ "SPN" SG_ 2566703870 EngExhstGsRcrcltn2Acttr1OprtnStt 5781;
BA_ "SPN" SG_ 2566703870 EngExhstGsRcrcltn2Acttr2DsredPos 5780;
BA_ "SigType" SG_ 2566703870 EngExhstGsRcrcltn2Acttr2DsredPos 1;
BA_ "SPN" SG_ 2566703870 EngExhstGsRcrclton2Actuator2Temp 5779;
BA_ "SigType" SG_ 2566703870 EngExhstGsRcrclton2Actuator2Temp 1;
BA_ "SPN" SG_ 2566703870 EngExhstGsRcrcltn2Acttr2TmpSttus 5778;
BA_ "SPN" SG_ 2566703870 EngExhstGsRcrcltn2Acttr2PrlmnryF 5777;
BA_ "SPN" SG_ 2566703870 EngExhstGsRcrcltn2Acttr1DsredPos 5776;
BA_ "SigType" SG_ 2566703870 EngExhstGsRcrcltn2Acttr1DsredPos 1;
BA_ "SPN" SG_ 2566703870 EngExhstGsRcrclton2Actuator1Temp 5775;
BA_ "SigType" SG_ 2566703870 EngExhstGsRcrclton2Actuator1Temp 1;
BA_ "SPN" SG_ 2566703870 EngExhstGsRcrcltn2Acttr1TmpSttus 5774;
BA_ "SPN" SG_ 2566703870 EngExhstGsRcrcltn2Acttr1PrlmnryF 5773;
BA_ "SPN" SG_ 2566703614 EngFuelRackFuelSupplyTemp 7314;
BA_ "SigType" SG_ 2566703614 EngFuelRackFuelSupplyTemp 1;
BA_ "SPN" SG_ 2566703614 EngTurboWastegateActuator2Temp 5787;
BA_ "SigType" SG_ 2566703614 EngTurboWastegateActuator2Temp 1;
BA_ "SPN" SG_ 2566703614 EngFuelValve2Temp 5786;
BA_ "SigType" SG_ 2566703614 EngFuelValve2Temp 1;
BA_ "SPN" SG_ 2566703614 EngFuelValve1Temp 5785;
BA_ "SigType" SG_ 2566703614 EngFuelValve1Temp 1;
BA_ "SPN" SG_ 2566703614 EngThrottleValve2Temp 5784;
BA_ "SigType" SG_ 2566703614 EngThrottleValve2Temp 1;
BA_ "SPN" SG_ 2566703614 EngThrottleValve1Temp 5783;
BA_ "SigType" SG_ 2566703614 EngThrottleValve1Temp 1;
BA_ "SPN" SG_ 2566703358 EngFuelingDesiredRqCount 6897;
BA_ "SPN" SG_ 2566703358 EngFuelingInhibitRqCount 6896;
BA_ "SPN" SG_ 2566703358 EngGasSubstitutionFuelPercentage 6333;
BA_ "SigType" SG_ 2566703358 EngGasSubstitutionFuelPercentage 1;
BA_ "SPN" SG_ 2566703358 EngDualFuelMode 6791;
BA_ "SigType" SG_ 2566703358 EngDualFuelMode 5;
BA_ "SPN" SG_ 2566703358 SrcAddrssOfCntrllngDvcFrFlngStte 6307;
BA_ "SPN" SG_ 2566703358 EngFuelingInhibitPreventedReason 5866;
BA_ "SPN" SG_ 2566703358 EngFuelingInhibitAllowed 5795;
BA_ "SigType" SG_ 2566703358 EngFuelingInhibitAllowed 5;
BA_ "SPN" SG_ 2566703358 FeedbackEngFuelingState 5794;
BA_ "SigType" SG_ 2566703358 FeedbackEngFuelingState 5;
BA_ "SPN" SG_ 2566702590 AT1SCRIntrmdteTempPreliminaryFMI 5863;
BA_ "SPN" SG_ 2566702590 AT1SCRIntermediateTemp 5862;
BA_ "SigType" SG_ 2566702590 AT1SCRIntermediateTemp 1;
BA_ "SPN" SG_ 2566702334 AT2SCRIntrmdteTempPreliminaryFMI 5865;
BA_ "SPN" SG_ 2566702334 AT2SCRIntermediateTemp 5864;
BA_ "SigType" SG_ 2566702334 AT2SCRIntermediateTemp 1;
BA_ "SPN" SG_ 2566702078 SupplyGasMethanePercentage 5867;
BA_ "SigType" SG_ 2566702078 SupplyGasMethanePercentage 1;
VAL_ 2365428734 GenFrequencySelection 14 "Unknown" 2 "400 Hz" 1 "60 Hz" 0 "50 Hz" ;
VAL_ 2365428734 GenGoverningSpeedCommand 3 "Don't care / take no action" 2 "Reserved" 1 "Low Idle Speed" 0 "Rated Speed" ;
VAL_ 2365428734 GenNotReadyToAutoParaState 3 "not available" 2 "error" 1 "active (not ready to parallel)" 0 "inactive (ready to parallel)" ;
VAL_ 2365428734 GenCtrlNotInAutoStartState 3 "not available" 2 "error" 1 "active (not ready to start automatically)" 0 "inactive (ready to start automatically)" ;
VAL_ 2365376254 EngOBDWarmUpSequence 3 "Not supported or not available" 2 "SAE reserved" 1 "A warm-up cycle has occurred on this engine start" 0 "A warm-up cycle has not occurred on this engine start" ;
VAL_ 2566705918 FlashProtectLamp 3 "Unavailable / Do Not Flash" 2 "Reserved" 1 "Fast Flash" 0 "Slow Flash" ;
VAL_ 2566705918 FlashAmberWarningLamp 3 "Unavailable / Do Not Flash" 2 "Reserved" 1 "Fast Flash" 0 "Slow Flash" ;
VAL_ 2566705918 FlashRedStopLamp 3 "Unavailable / Do Not Flash" 2 "Reserved" 1 "Fast Flash" 0 "Slow Flash" ;
VAL_ 2566705918 FlashMalfuncIndicatorLamp 3 "Unavailable / Do Not Flash" 2 "Reserved" 1 "Fast Flash" 0 "Slow Flash" ;
VAL_ 2566705918 ProtectLampStatus 3 "Not available" 2 "Reserved" 1 "Lamp on" 0 "Lamp off" ;
VAL_ 2566705918 AmberWarningLampStatus 3 "Not available" 2 "Reserved" 1 "Lamp on" 0 "Lamp off" ;
VAL_ 2566705918 RedStopLampState 3 "Not available" 2 "Reserved" 1 "Lamp on" 0 "Lamp off" ;
VAL_ 2566705918 MalfunctionIndicatorLampStatus 3 "Not available" 2 "Reserved" 1 "Lamp on" 0 "Lamp off" ;
VAL_ 2566705662 FlashProtectLamp 3 "Unavailable / Do Not Flash" 2 "Reserved" 1 "Fast Flash" 0 "Slow Flash" ;
VAL_ 2566705662 FlashAmberWarningLamp 3 "Unavailable / Do Not Flash" 2 "Reserved" 1 "Fast Flash" 0 "Slow Flash" ;
VAL_ 2566705662 FlashRedStopLamp 3 "Unavailable / Do Not Flash" 2 "Reserved" 1 "Fast Flash" 0 "Slow Flash" ;
VAL_ 2566705662 FlashMalfuncIndicatorLamp 3 "Unavailable / Do Not Flash" 2 "Reserved" 1 "Fast Flash" 0 "Slow Flash" ;
VAL_ 2566705662 ProtectLampStatus 3 "Not available" 2 "Reserved" 1 "Lamp on" 0 "Lamp off" ;
VAL_ 2566705662 AmberWarningLampStatus 3 "Not available" 2 "Reserved" 1 "Lamp on" 0 "Lamp off" ;
VAL_ 2566705662 RedStopLampState 3 "Not available" 2 "Reserved" 1 "Lamp on" 0 "Lamp off" ;
VAL_ 2566705662 MalfunctionIndicatorLampStatus 3 "Not available" 2 "Reserved" 1 "Lamp on" 0 "Lamp off" ;
VAL_ 2349465342 StaticRollAngleStatus 7 "Not available" 6 "Error" 5 "Reserved" 4 "Angle Data Invalid" 3 "Sensor Reboots" 2 "Sensor Defect" 1 "Sensor OK" 0 "Sensor Busy" ;
VAL_ 2364553470 EngDualFuelModeCmd 3 "Not available" 2 "Reserved" 1 "Activate dual fuel mode" 0 "De-activate dual fuel mode" ;
VAL_ 2364553214 EngTrbCmprssrBlwffActtr1OprtnStt 15 "Not available" 14 "Error" 6 "Calibration in Progress (must be broadcast at least once per calibration process defined in SPN 6201)" 5 "Uncontrolled Shutdown Active (no torque is being applied from the actuator)" 4 "Controlled Shutdown Active (driving to the default position - usually this means closed)" 3 "Derate Active (torque output reduced due to environmental conditions)" 2 "Alarm High Severity (functional but transient performance may be reduced)" 1 "Alarm (fully operational but needs service)" 0 "Normal" ;
VAL_ 2364553214 EngTrbCmprssrBlwffActtr1TmpSttus 7 "Not available" 6 "Error" 5 "Not Defined" 4 "Low Most severe" 3 "Low Least severe" 2 "In Range" 1 "High Least severe" 0 "High Most severe" ;
VAL_ 2364547838 PersistentLimitStatus 7 "Not available (parameter not supported)" 6 "Non-recoverable fault" 3 "Limited low (only high command values result in change)" 2 "Limited high (only lower command values result in change)" 1 "Operator limited/controlled (Request cannot be implemented)" 0 "Not limited" ;
VAL_ 2364547838 MachineSelectedSpeedSource 7 "Not available" 4 "'Simulated' speed" 3 "'Blended' speed" 2 "Navigation-based speed" 1 "Ground-based speed" 0 "Wheel-based speed" ;
VAL_ 2364547838 MachineSelectedDirection 3 "Not available" 2 "Error indication" 1 "Forward" 0 "Reverse" ;
VAL_ 2559049470 DesiredEngFuelingState 3 "Dont care / Take no action" 2 "Parameter supported but no request" 1 "Fueling desired keep engine running" 0 "Fueling not desired shut off engine fueling" ;
VAL_ 2559049470 RequestedFuelType 255 "Not supported" 254 "Reserved for use in SPN 5837" 24 "Reserved for use in SPN 5837" 23 "Natural Gas (NG) - NG" 7 "Propane - PROP" 6 "Compressed Natural Gas (CNG) - CNG" 5 "Liquefied Petroleum Gas (LPG) - LPG" 4 "Diesel - DSL" 3 "Ethanol - ETH" 2 "Methanol - METH" 1 "Gasoline/petrol - GAS" 0 "Not available - NONE" ;
VAL_ 2559049470 EngGasFuelUsageInhibited 3 "Not available" 2 "Error" 1 "Gaseous Fuel Usage Inhibited" 0 "Gaseous Fuel Usage Not Inhibited" ;
VAL_ 2349596414 DrvrActvtnDmndFrAdvncdEmrgncyBrk 3 "dont care / take no action" 2 "reserved" 1 "the driver wants the Advanced Emergency Braking System to warn or intervene if necessary no deactivation of" 0 "the driver does not want the Advanced Emergency Braking System to warn or intervene at any time deactivation of" ;
VAL_ 2362244862 DataFormat_ErrorCondition 3 "Not Available or error" 2 "Data format is unsigned Long Integer" 1 "Data format is Floating" 0 "Data format is Long Integer" ;
VAL_ 2362244862 ProcessDataType 3 "Message is Actual value request" 2 "Message is Set Point request" 1 "Data is Actual values" 0 "Data is Set Point" ;
VAL_ 2362179326 DataFormat_ErrorCondition 3 "Not Available or error" 2 "Data format is unsigned Long Integer" 1 "Data format is Floating" 0 "Data format is Long Integer" ;
VAL_ 2362179326 ProcessDataType 3 "Message is Actual value request" 2 "Message is Set Point request" 1 "Data is Actual values" 0 "Data is Set Point" ;
VAL_ 2361851646 ValveFailSafeMode 3 "Don’t Care" 2 "Reserved" 1 "Float" 0 "Block" ;
VAL_ 2361851646 ValveState 15 "Don’t Care" 3 "Floating" 2 "Retract" 1 "Extend" 0 "Blocked" ;
VAL_ 2358509310 NMControlModeIndicator 0 "SetPendingName" 1 "PendingName" 2 "CurrentName" 3 "NameACK" 4 "NameNACK" 5 "ReqPendingName" 6 "ReqCurrentName" 7 "AdoptPendingName" 8 "ReqNameAddressClaim" ;
VAL_ 2358509310 ErrorCode 0 "Security not satisfied" 1 "Item(s) not allowed to change" 2 "Item conflict" 3 "Checksum does not match" 4 "Pending Name not set" 255 "Not Available" 5 "Other" ;
VAL_ 2558983934 SwitchedPowerOutput18Cmd 3 "Take no action" 2 "Reserved" 1 "Output on" 0 "Output off" ;
VAL_ 2558983934 SwitchedPowerOutput19Cmd 3 "Take no action" 2 "Reserved" 1 "Output on" 0 "Output off" ;
VAL_ 2558983934 SwitchedPowerOutput20Cmd 3 "Take no action" 2 "Reserved" 1 "Output on" 0 "Output off" ;
VAL_ 2558983934 SwitchedPowerOutput13Cmd 3 "Take no action" 2 "Reserved" 1 "Output on" 0 "Output off" ;
VAL_ 2558983934 SwitchedPowerOutput14Cmd 3 "Take no action" 2 "Reserved" 1 "Output on" 0 "Output off" ;
VAL_ 2558983934 SwitchedPowerOutput15Cmd 3 "Take no action" 2 "Reserved" 1 "Output on" 0 "Output off" ;
VAL_ 2558983934 SwitchedPowerOutput16Cmd 3 "Take no action" 2 "Reserved" 1 "Output on" 0 "Output off" ;
VAL_ 2558983934 SwitchedPowerOutput9Cmd 3 "Take no action" 2 "Reserved" 1 "Output on" 0 "Output off" ;
VAL_ 2558983934 SwitchedPowerOutput10Cmd 3 "Take no action" 2 "Reserved" 1 "Output on" 0 "Output off" ;
VAL_ 2558983934 SwitchedPowerOutput29Cmd 3 "Take no action" 2 "Reserved" 1 "Output on" 0 "Output off" ;
VAL_ 2558983934 SwitchedPowerOutput30Cmd 3 "Take no action" 2 "Reserved" 1 "Output on" 0 "Output off" ;
VAL_ 2558983934 SwitchedPowerOutput31Cmd 3 "Take no action" 2 "Reserved" 1 "Output on" 0 "Output off" ;
VAL_ 2558983934 SwitchedPowerOutput32Cmd 3 "Take no action" 2 "Reserved" 1 "Output on" 0 "Output off" ;
VAL_ 2558983934 SwitchedPowerOutput25Cmd 3 "Take no action" 2 "Reserved" 1 "Output on" 0 "Output off" ;
VAL_ 2558983934 SwitchedPowerOutput26Cmd 3 "Take no action" 2 "Reserved" 1 "Output on" 0 "Output off" ;
VAL_ 2558983934 SwitchedPowerOutput27Cmd 3 "Take no action" 2 "Reserved" 1 "Output on" 0 "Output off" ;
VAL_ 2558983934 SwitchedPowerOutput28Cmd 3 "Take no action" 2 "Reserved" 1 "Output on" 0 "Output off" ;
VAL_ 2558983934 SwitchedPowerOutput21Cmd 3 "Take no action" 2 "Reserved" 1 "Output on" 0 "Output off" ;
VAL_ 2558983934 SwitchedPowerOutput22Cmd 3 "Take no action" 2 "Reserved" 1 "Output on" 0 "Output off" ;
VAL_ 2558983934 SwitchedPowerOutput23Cmd 3 "Take no action" 2 "Reserved" 1 "Output on" 0 "Output off" ;
VAL_ 2558983934 SwitchedPowerOutput24Cmd 3 "Take no action" 2 "Reserved" 1 "Output on" 0 "Output off" ;
VAL_ 2558983934 SwitchedPowerOutput17Cmd 3 "Take no action" 2 "Reserved" 1 "Output on" 0 "Output off" ;
VAL_ 2558983934 SwitchedPowerOutput11Cmd 3 "Take no action" 2 "Reserved" 1 "Output on" 0 "Output off" ;
VAL_ 2558983934 SwitchedPowerOutput12Cmd 1 "Output on" 0 "Output off" 3 "Take no action" 2 "Reserved" ;
VAL_ 2558983934 SwitchedPowerOutput5Cmd 3 "Take no action" 2 "Reserved" 1 "Output on" 0 "Output off" ;
VAL_ 2558983934 SwitchedPowerOutput6Cmd 3 "Take no action" 2 "Reserved" 1 "Output on" 0 "Output off" ;
VAL_ 2558983934 SwitchedPowerOutput7Cmd 3 "Take no action" 2 "Reserved" 1 "Output on" 0 "Output off" ;
VAL_ 2558983934 SwitchedPowerOutput8Cmd 3 "Take no action" 2 "Reserved" 1 "Output on" 0 "Output off" ;
VAL_ 2558983934 SwitchedPowerOutput1Cmd 3 "Take no action" 2 "Reserved" 1 "Output on" 0 "Output off" ;
VAL_ 2558983934 SwitchedPowerOutput2Cmd 3 "Take no action" 2 "Reserved" 1 "Output on" 0 "Output off" ;
VAL_ 2558983934 SwitchedPowerOutput3Cmd 3 "Take no action" 2 "Reserved" 1 "Output on" 0 "Output off" ;
VAL_ 2558983934 SwitchedPowerOutput4Cmd 3 "Take no action" 2 "Reserved" 1 "Output on" 0 "Output off" ;
VAL_ 2349727486 TransMode10 3 "Take no action" 2 "Reserved" 1 "Enable" 0 "Disable" ;
VAL_ 2349727486 TransMode9 3 "Take no action" 2 "Reserved" 1 "Enable" 0 "Disable" ;
VAL_ 2566767358 EngFuelIsolationCtrl 3 "Don't care / take no action" 2 "Reserved" 1 "Gaseous Fuel is Used" 0 "Gaseous Fuel Migration is Prevented" ;
VAL_ 2566767358 FuelType 255 "Not available (Parameter not supported)" 254 "Error" 28 "Dual Fuel – Diesel and LNG" 27 "Dual Fuel – Diesel and CNG" 26 "Natural Gas (Compressed or Liquefied Natural Gas)" 25 "Bi-fuel using diesel" 24 "Bi-fuel vehicle using NG – BI_NG" 23 "Natural Gas (NG) - NG" 22 "Hybrid vehicle in regeneration mode - HYB_REG" 21 "Hybrid vehicle using battery and combustion engine - HYB_MIX" 20 "Hybrid vehicle using battery - HYB_ELEC" 19 "Hybrid vehicle using diesel engine - HYB_DSL" 18 "Hybrid vehicle using gasoline engine on ethanol - HYB_ETH" 17 "Hybrid vehicle using gasoline engine - HYB_GAS" 16 "Bi-fuel vehicle using battery and combustion engine - BI_MIX" 15 "Bi-fuel vehicle using battery - BI_ELEC" 14 "Bi-fuel vehicle using propane - BI_PROP" 13 "Bi-fuel vehicle using CNG - BI_CNG" 12 "Bi-fuel vehicle using LPG - BI_LPG" 11 "Bi-fuel vehicle using ethanol - BI_ETH" 10 "Bi-fuel vehicle using methanol - BI_METH" 9 "Bi-fuel vehicle using gasoline - BI_GAS" 8 "Battery/electric - ELEC" 7 "Propane - PROP" 6 "Compressed Natural Gas (CNG) - CNG" 5 "Liquefied Petroleum Gas (LPG) - LPG" 4 "Diesel - DSL" 3 "Ethanol - ETH" 2 "Methanol - METH" 1 "Gasoline/petrol - GAS" 0 "Not available - NONE" ;
VAL_ 2566705150 AT2IntkNOxSnsrSlfdagnosisTrigger 15 "Not supported" 4 "NOx Sensor ATI2 Self Diagnosis Request at After Run" 3 "NOx Sensor ATI2 Self Diagnosis Request at fuel cut" 2 "NOx Sensor ATI2 Self Diagnosis Request at partial load" 1 "NOx Sensor ATI2 Self Diagnosis Request at Lambda10" 0 "Diagnostic mode disabled" ;
VAL_ 2566705150 AT2OtltNOxSnsrSlfdagnosisTrigger 15 "Not supported" 4 "NOx Sensor ATO2 Self Diagnosis Request at After Run" 3 "NOx Sensor ATO2 Self Diagnosis Request at fuel cut" 2 "NOx Sensor ATO2 Self Diagnosis Request at partial load" 1 "NOx Sensor ATO2 Self Diagnosis Request at Lambda10" 0 "Diagnostic mode disabled" ;
VAL_ 2566705150 AT1IntkNOxSnsrSlfdagnosisTrigger 15 "Not supported" 4 "NOx Sensor ATI1 Self Diagnosis Request at After Run" 3 "NOx Sensor ATI1 Self Diagnosis Request at fuel cut" 2 "NOx Sensor ATI1 Self Diagnosis Request at partial load" 1 "NOx Sensor ATI1 Self Diagnosis Request at Lambda10" 0 "Diagnostic mode disabled" ;
VAL_ 2566705150 AT1OtltNOxSnsrSlfdagnosisTrigger 15 "Not supported" 4 "NOx Sensor ATO1 Self Diagnosis Request at After Run" 3 "NOx Sensor ATO1 Self Diagnosis Request at fuel cut" 2 "NOx Sensor ATO1 Self Diagnosis Request at partial load" 1 "NOx Sensor ATO1 Self Diagnosis Request at Lambda10" 0 "Diagnostic mode disabled" ;
VAL_ 2566704382 AT2OutletGasSensorPowerSupply 3 "Unavailable" 2 "Error" 1 "On The ECU is powering the Aftertreatment 2 Outlet Gas Sensor" 0 "Off" ;
VAL_ 2566704382 AT2IntakeGasSensorPowerSupply 3 "Unavailable" 2 "Error" 1 "On The ECU is powering the Aftertreatment 2 Intake Gas Sensor" 0 "Off" ;
VAL_ 2566704382 AT1OutletGasSensorPowerSupply 3 "Unavailable" 2 "Error" 1 "On The ECU is powering the Aftertreatment 1 Outlet Gas Sensor" 0 "Off" ;
VAL_ 2566704382 AT1IntakeGasSensorPowerSupply 3 "Unavailable" 2 "Error" 1 "On The ECU is powering the Aftertreatment 1 Intake Gas Sensor" 0 "Off" ;
VAL_ 2566704126 EngExhstGsRcrcltn1Acttr2OprtnStt 15 "Not available" 14 "Error" 5 "Uncontrolled Shutdown Active actuator current is off so it is limp" 4 "Controlled Shutdown Active driving to the default position  usually this means closed" 3 "Derate Active torque output reduced due to environmental conditions" 2 "Alarm High Severity functional but transient performance may be reduced" 1 "Alarm fully operational but needs service" 0 "Normal" ;
VAL_ 2566704126 EngExhstGsRcrcltn1Acttr1OprtnStt 15 "Not available" 14 "Error" 5 "Uncontrolled Shutdown Active actuator current is off so it is limp" 4 "Controlled Shutdown Active driving to the default position  usually this means closed" 3 "Derate Active torque output reduced due to environmental conditions" 2 "Alarm High Severity functional but transient performance may be reduced" 1 "Alarm fully operational but needs service" 0 "Normal" ;
VAL_ 2566704126 EngExhstGsRcrcltn1Acttr2TmpSttus 7 "Not available" 6 "Error" 5 "Not Defined" 4 "Low Most severe" 3 "Low Least severe" 2 "In Range" 1 "High Least severe" 0 "High Most severe" ;
VAL_ 2566704126 EngExhstGsRcrcltn1Acttr1TmpSttus 7 "Not available" 6 "Error" 5 "Not Defined" 4 "Low Most severe" 3 "Low Least severe" 2 "In Range" 1 "High Least severe" 0 "High Most severe" ;
VAL_ 2566703870 EngExhstGsRcrcltn2Acttr2OprtnStt 15 "Not available" 14 "Error" 5 "Uncontrolled Shutdown Active actuator current is off so it is limp" 4 "Controlled Shutdown Active driving to the default position  usually this means closed" 3 "Derate Active torque output reduced due to environmental conditions" 2 "Alarm High Severity functional but transient performance may be reduced" 1 "Alarm fully operational but needs service" 0 "Normal" ;
VAL_ 2566703870 EngExhstGsRcrcltn2Acttr1OprtnStt 5 "Uncontrolled Shutdown Active actuator current is off so it is limp" 4 "Controlled Shutdown Active driving to the default position  usually this means closed" 3 "Derate Active torque output reduced due to environmental conditions" 2 "Alarm High Severity functional but transient performance may be reduced" 1 "Alarm fully operational but needs service" 0 "Normal" 15 "Not available" 14 "Error" ;
VAL_ 2566703870 EngExhstGsRcrcltn2Acttr2TmpSttus 7 "Not available" 6 "Error" 5 "Not Defined" 4 "Low Most severe" 3 "Low Least severe" 2 "In Range" 1 "High Least severe" 0 "High Most severe" ;
VAL_ 2566703870 EngExhstGsRcrcltn2Acttr1TmpSttus 7 "Not available" 6 "Error" 5 "Not Defined" 4 "Low Most severe" 3 "Low Least severe" 2 "In Range" 1 "High Least severe" 0 "High Most severe" ;
VAL_ 2566703358 EngFuelingDesiredRqCount 3 "More than 10 active fueling desired requests" ;
VAL_ 2566703358 EngFuelingInhibitRqCount 3 "More than 10 active fueling inhibit requests" ;
VAL_ 2566703358 EngDualFuelMode 3 "Not available" 2 "Reserved" 1 "Actual dual fuel mode on" 0 "Actual dual fuel mode off" ;
VAL_ 2566703358 EngFuelingInhibitPreventedReason 15 "Not Supported" 12 "Low idle governor operation required" 11 "Engine driven fan request" 10 "Maximum number of engine fuelling inhibit requests (SPN 5793 = 0) temporary limit exceeded. The temporary limit may be bounded by elapsed time, distance travelled, driving conditions, or something else that the manufacturer has specified." 9 "Insufficient SLI battery charge" 8 "Engine protection. Use other engine protection enumerations in this parameter when applicable.  If the method of engine protection is not defined in other states, then use this state." 7 "Engine load too high" 6 "Aftertreatment Protection" 5 "Aftertreatment system is cold" 4 "Service Override" 3 "Engine is cold" 2 "Oil Distribution in engine is incomplete" 1 "Aftertreatment regeneration is active or preparing to be active" 0 "Fueling inhibit allowed (SPN 5795 = 01)" ;
VAL_ 2566703358 EngFuelingInhibitAllowed 3 "Not Supported" 2 "SAE Reserved" 1 "Engine will stop fueling in response to SPN 5793 Desired Engine Fueling State" 0 "Engine currently will not stop fueling in response to SPN 5793 Desired Engine Fueling State" ;
VAL_ 2566703358 FeedbackEngFuelingState 3 "Not Supported" 2 "No active request per SPN 5793 Desired Engine Fueling State" 1 "Engine will be kept running SPN 5793 Desired Engine Fueling State  01" 0 "Fueling is or will be inhibited SPN 5793 Desired Engine Fueling State  00" ;

SG_MUL_VAL_ 2358509310 VehicleSystemQualifierFlag NMControlModeIndicator 0-0, 4-4, 8-8;
SG_MUL_VAL_ 2358509310 VehicleSystemInstanceQualifierFl NMControlModeIndicator 0-0, 4-4, 8-8;
SG_MUL_VAL_ 2358509310 NameChecksum NMControlModeIndicator 0-0;
SG_MUL_VAL_ 2358509310 ManufacturerCodeQualifierFlag NMControlModeIndicator 0-0, 4-4, 8-8;
SG_MUL_VAL_ 2358509310 IndustryGroupQualifierFlag NMControlModeIndicator 0-0, 4-4, 8-8;
SG_MUL_VAL_ 2358509310 FunctionQualifierFlag NMControlModeIndicator 0-0, 4-4, 8-8;
SG_MUL_VAL_ 2358509310 FunctionInstanceQualifierFlag NMControlModeIndicator 0-0, 4-4, 8-8;
SG_MUL_VAL_ 2358509310 ErrorCode NMControlModeIndicator 4-4;
SG_MUL_VAL_ 2358509310 ECUInstanceQualifierFlag NMControlModeIndicator 0-0, 4-4, 8-8;
SG_MUL_VAL_ 2358509310 CommandVehicleSystemInstance NMControlModeIndicator 0-3, 8-8;
SG_MUL_VAL_ 2358509310 CommandVehicleSystem NMControlModeIndicator 0-3, 8-8;
SG_MUL_VAL_ 2358509310 CommandManufacturerCode NMControlModeIndicator 0-3, 8-8;
SG_MUL_VAL_ 2358509310 CommandIndustryGroup NMControlModeIndicator 0-3, 8-8;
SG_MUL_VAL_ 2358509310 CommandFunctionInstance NMControlModeIndicator 0-3, 8-8;
SG_MUL_VAL_ 2358509310 CommandFunction NMControlModeIndicator 0-3, 8-8;
SG_MUL_VAL_ 2358509310 CommandECUInstance NMControlModeIndicator 0-3, 8-8;
SG_MUL_VAL_ 2358509310 CommandArbitraryAddressCapable NMControlModeIndicator 0-3, 8-8;
SG_MUL_VAL_ 2358509310 ArbitraryAddressCapableQualifier ManufacturerCodeQualifierFlag 0-0, 4-4, 8-8;
